VERSION ""

NS_ :

BS_:

BU_: ECM

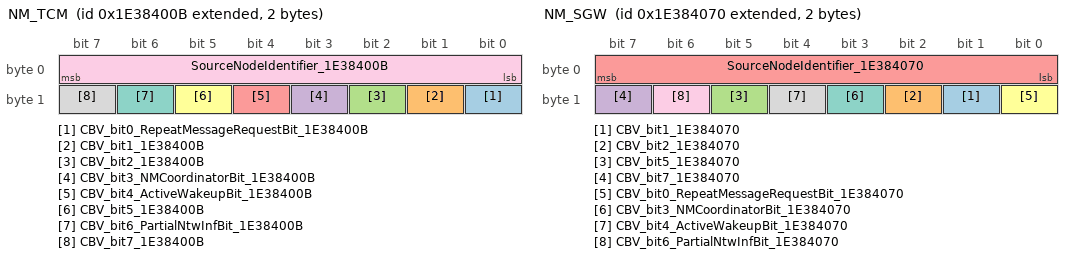
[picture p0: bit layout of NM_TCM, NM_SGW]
BO_ 2654486539 NM_TCM: 2 Vector__XXX
 SG_ CBV_bit0_RepeatMessageRequestBit_1E38400B : 8|1@0+ (1,0) [0|1] "" ECM
 SG_ CBV_bit1_1E38400B : 9|1@0+ (1,0) [0|1] "" ECM
 SG_ CBV_bit2_1E38400B : 10|1@0+ (1,0) [0|1] "" ECM
 SG_ CBV_bit3_NMCoordinatorBit_1E38400B : 11|1@0+ (1,0) [0|1] "" ECM
 SG_ CBV_bit4_ActiveWakeupBit_1E38400B : 12|1@0+ (1,0) [0|1] "" ECM
 SG_ CBV_bit5_1E38400B : 13|1@0+ (1,0) [0|1] "" ECM
 SG_ CBV_bit6_PartialNtwInfBit_1E38400B : 14|1@0+ (1,0) [0|1] "" ECM
 SG_ CBV_bit7_1E38400B : 15|1@0+ (1,0) [0|1] "" ECM
 SG_ SourceNodeIdentifier_1E38400B : 7|8@0+ (1,0) [0|255] "-"  ECM

BO_ 2654486640 NM_SGW: 2 Vector__XXX
 SG_ CBV_bit1_1E384070 : 9|1@0+ (1,0) [0|1] "" ECM
 SG_ CBV_bit2_1E384070 : 10|1@0+ (1,0) [0|1] "" ECM
 SG_ CBV_bit5_1E384070 : 13|1@0+ (1,0) [0|1] "" ECM
 SG_ CBV_bit7_1E384070 : 15|1@0+ (1,0) [0|1] "" ECM
 SG_ SourceNodeIdentifier_1E384070 : 7|8@0+ (1,0) [0|255] "-"  ECM
 SG_ CBV_bit0_RepeatMessageRequestBit_1E384070 : 8|1@0+ (1,0) [0|1] "" ECM
 SG_ CBV_bit3_NMCoordinatorBit_1E384070 : 11|1@0+ (1,0) [0|1] "" ECM
 SG_ CBV_bit4_ActiveWakeupBit_1E384070 : 12|1@0+ (1,0) [0|1] "" ECM
 SG_ CBV_bit6_PartialNtwInfBit_1E384070 : 14|1@0+ (1,0) [0|1] "" ECM

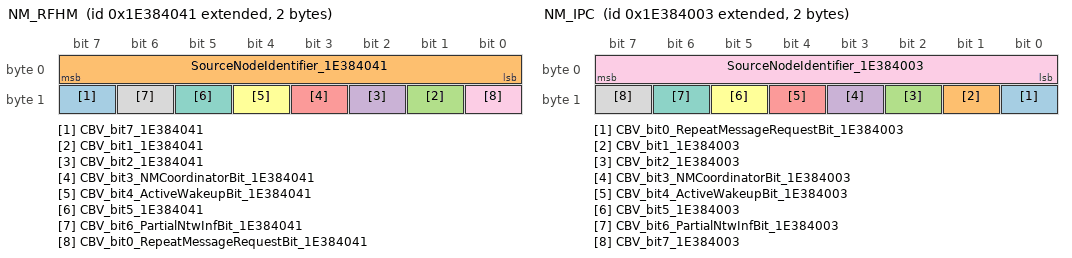
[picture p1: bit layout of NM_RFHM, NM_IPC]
BO_ 2654486593 NM_RFHM: 2 Vector__XXX
 SG_ CBV_bit7_1E384041 : 15|1@0+ (1,0) [0|1] "" ECM
 SG_ SourceNodeIdentifier_1E384041 : 7|8@0+ (1,0) [0|255] "-"  ECM
 SG_ CBV_bit1_1E384041 : 9|1@0+ (1,0) [0|1] "" ECM
 SG_ CBV_bit2_1E384041 : 10|1@0+ (1,0) [0|1] "" ECM
 SG_ CBV_bit3_NMCoordinatorBit_1E384041 : 11|1@0+ (1,0) [0|1] "" ECM
 SG_ CBV_bit4_ActiveWakeupBit_1E384041 : 12|1@0+ (1,0) [0|1] "" ECM
 SG_ CBV_bit5_1E384041 : 13|1@0+ (1,0) [0|1] "" ECM
 SG_ CBV_bit6_PartialNtwInfBit_1E384041 : 14|1@0+ (1,0) [0|1] "" ECM
 SG_ CBV_bit0_RepeatMessageRequestBit_1E384041 : 8|1@0+ (1,0) [0|1] "" ECM

BO_ 2654486531 NM_IPC: 2 Vector__XXX
 SG_ CBV_bit0_RepeatMessageRequestBit_1E384003 : 8|1@0+ (1,0) [0|1] "" ECM
 SG_ CBV_bit1_1E384003 : 9|1@0+ (1,0) [0|1] "" ECM
 SG_ CBV_bit2_1E384003 : 10|1@0+ (1,0) [0|1] "" ECM
 SG_ CBV_bit3_NMCoordinatorBit_1E384003 : 11|1@0+ (1,0) [0|1] "" ECM
 SG_ CBV_bit4_ActiveWakeupBit_1E384003 : 12|1@0+ (1,0) [0|1] "" ECM
 SG_ CBV_bit5_1E384003 : 13|1@0+ (1,0) [0|1] "" ECM
 SG_ CBV_bit6_PartialNtwInfBit_1E384003 : 14|1@0+ (1,0) [0|1] "" ECM
 SG_ CBV_bit7_1E384003 : 15|1@0+ (1,0) [0|1] "" ECM
 SG_ SourceNodeIdentifier_1E384003 : 7|8@0+ (1,0) [0|255] "-"  ECM

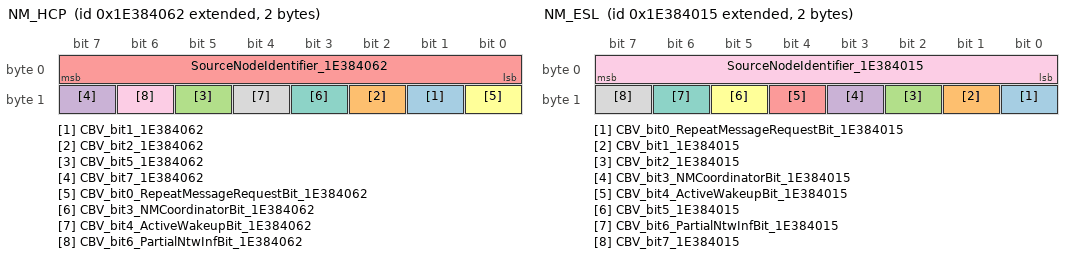
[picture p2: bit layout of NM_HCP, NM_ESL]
BO_ 2654486626 NM_HCP: 2 Vector__XXX
 SG_ CBV_bit1_1E384062 : 9|1@0+ (1,0) [0|1] "" ECM
 SG_ CBV_bit2_1E384062 : 10|1@0+ (1,0) [0|1] "" ECM
 SG_ CBV_bit5_1E384062 : 13|1@0+ (1,0) [0|1] "" ECM
 SG_ CBV_bit7_1E384062 : 15|1@0+ (1,0) [0|1] "" ECM
 SG_ SourceNodeIdentifier_1E384062 : 7|8@0+ (1,0) [0|255] "-"  ECM
 SG_ CBV_bit0_RepeatMessageRequestBit_1E384062 : 8|1@0+ (1,0) [0|1] "" ECM
 SG_ CBV_bit3_NMCoordinatorBit_1E384062 : 11|1@0+ (1,0) [0|1] "" ECM
 SG_ CBV_bit4_ActiveWakeupBit_1E384062 : 12|1@0+ (1,0) [0|1] "" ECM
 SG_ CBV_bit6_PartialNtwInfBit_1E384062 : 14|1@0+ (1,0) [0|1] "" ECM

BO_ 2654486549 NM_ESL: 2 Vector__XXX
 SG_ CBV_bit0_RepeatMessageRequestBit_1E384015 : 8|1@0+ (1,0) [0|1] "" ECM
 SG_ CBV_bit1_1E384015 : 9|1@0+ (1,0) [0|1] "" ECM
 SG_ CBV_bit2_1E384015 : 10|1@0+ (1,0) [0|1] "" ECM
 SG_ CBV_bit3_NMCoordinatorBit_1E384015 : 11|1@0+ (1,0) [0|1] "" ECM
 SG_ CBV_bit4_ActiveWakeupBit_1E384015 : 12|1@0+ (1,0) [0|1] "" ECM
 SG_ CBV_bit5_1E384015 : 13|1@0+ (1,0) [0|1] "" ECM
 SG_ CBV_bit6_PartialNtwInfBit_1E384015 : 14|1@0+ (1,0) [0|1] "" ECM
 SG_ CBV_bit7_1E384015 : 15|1@0+ (1,0) [0|1] "" ECM
 SG_ SourceNodeIdentifier_1E384015 : 7|8@0+ (1,0) [0|255] "-"  ECM

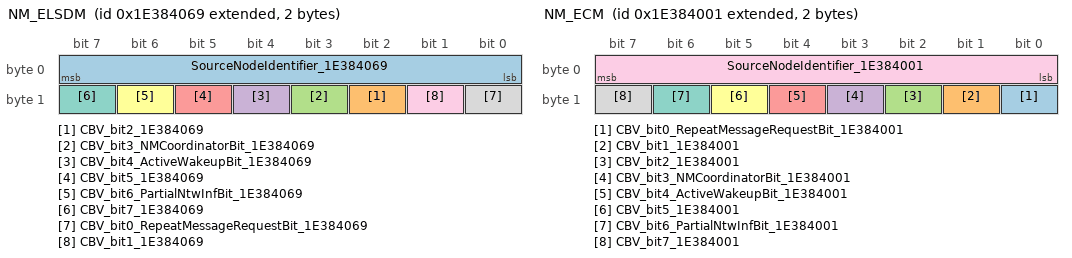
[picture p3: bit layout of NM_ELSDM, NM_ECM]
BO_ 2654486633 NM_ELSDM: 2 Vector__XXX
 SG_ SourceNodeIdentifier_1E384069 : 7|8@0+ (1,0) [0|255] "-"  ECM
 SG_ CBV_bit2_1E384069 : 10|1@0+ (1,0) [0|1] "" ECM
 SG_ CBV_bit3_NMCoordinatorBit_1E384069 : 11|1@0+ (1,0) [0|1] "" ECM
 SG_ CBV_bit4_ActiveWakeupBit_1E384069 : 12|1@0+ (1,0) [0|1] "" ECM
 SG_ CBV_bit5_1E384069 : 13|1@0+ (1,0) [0|1] "" ECM
 SG_ CBV_bit6_PartialNtwInfBit_1E384069 : 14|1@0+ (1,0) [0|1] "" ECM
 SG_ CBV_bit7_1E384069 : 15|1@0+ (1,0) [0|1] "" ECM
 SG_ CBV_bit0_RepeatMessageRequestBit_1E384069 : 8|1@0+ (1,0) [0|1] "" ECM
 SG_ CBV_bit1_1E384069 : 9|1@0+ (1,0) [0|1] "" ECM

BO_ 2654486529 NM_ECM: 2 ECM
 SG_ CBV_bit0_RepeatMessageRequestBit_1E384001 : 8|1@0+ (1,0) [0|1] "" Vector__XXX
 SG_ CBV_bit1_1E384001 : 9|1@0+ (1,0) [0|1] "" Vector__XXX
 SG_ CBV_bit2_1E384001 : 10|1@0+ (1,0) [0|1] "" Vector__XXX
 SG_ CBV_bit3_NMCoordinatorBit_1E384001 : 11|1@0+ (1,0) [0|1] "" Vector__XXX
 SG_ CBV_bit4_ActiveWakeupBit_1E384001 : 12|1@0+ (1,0) [0|1] "" Vector__XXX
 SG_ CBV_bit5_1E384001 : 13|1@0+ (1,0) [0|1] "" Vector__XXX
 SG_ CBV_bit6_PartialNtwInfBit_1E384001 : 14|1@0+ (1,0) [0|1] "" Vector__XXX
 SG_ CBV_bit7_1E384001 : 15|1@0+ (1,0) [0|1] "" Vector__XXX
 SG_ SourceNodeIdentifier_1E384001 : 7|8@0+ (1,0) [0|255] "-"  Vector__XXX

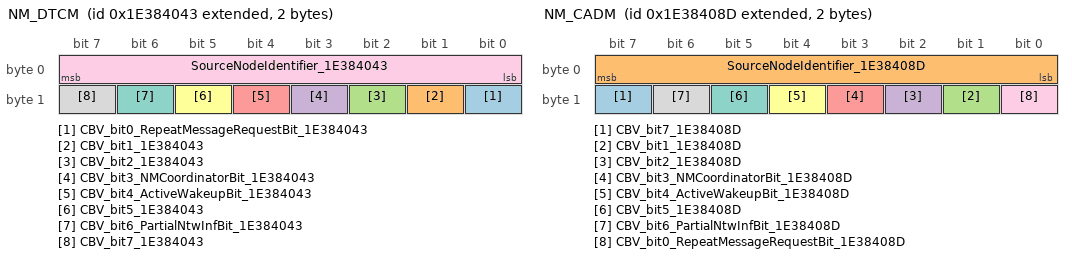
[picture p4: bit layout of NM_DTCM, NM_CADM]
BO_ 2654486595 NM_DTCM: 2 Vector__XXX
 SG_ CBV_bit0_RepeatMessageRequestBit_1E384043 : 8|1@0+ (1,0) [0|1] "" ECM
 SG_ CBV_bit1_1E384043 : 9|1@0+ (1,0) [0|1] "" ECM
 SG_ CBV_bit2_1E384043 : 10|1@0+ (1,0) [0|1] "" ECM
 SG_ CBV_bit3_NMCoordinatorBit_1E384043 : 11|1@0+ (1,0) [0|1] "" ECM
 SG_ CBV_bit4_ActiveWakeupBit_1E384043 : 12|1@0+ (1,0) [0|1] "" ECM
 SG_ CBV_bit5_1E384043 : 13|1@0+ (1,0) [0|1] "" ECM
 SG_ CBV_bit6_PartialNtwInfBit_1E384043 : 14|1@0+ (1,0) [0|1] "" ECM
 SG_ CBV_bit7_1E384043 : 15|1@0+ (1,0) [0|1] "" ECM
 SG_ SourceNodeIdentifier_1E384043 : 7|8@0+ (1,0) [0|255] "-"  ECM

BO_ 2654486669 NM_CADM: 2 Vector__XXX
 SG_ CBV_bit7_1E38408D : 15|1@0+ (1,0) [0|1] "" ECM
 SG_ SourceNodeIdentifier_1E38408D : 7|8@0+ (1,0) [0|255] "-"  ECM
 SG_ CBV_bit1_1E38408D : 9|1@0+ (1,0) [0|1] "" ECM
 SG_ CBV_bit2_1E38408D : 10|1@0+ (1,0) [0|1] "" ECM
 SG_ CBV_bit3_NMCoordinatorBit_1E38408D : 11|1@0+ (1,0) [0|1] "" ECM
 SG_ CBV_bit4_ActiveWakeupBit_1E38408D : 12|1@0+ (1,0) [0|1] "" ECM
 SG_ CBV_bit5_1E38408D : 13|1@0+ (1,0) [0|1] "" ECM
 SG_ CBV_bit6_PartialNtwInfBit_1E38408D : 14|1@0+ (1,0) [0|1] "" ECM
 SG_ CBV_bit0_RepeatMessageRequestBit_1E38408D : 8|1@0+ (1,0) [0|1] "" ECM

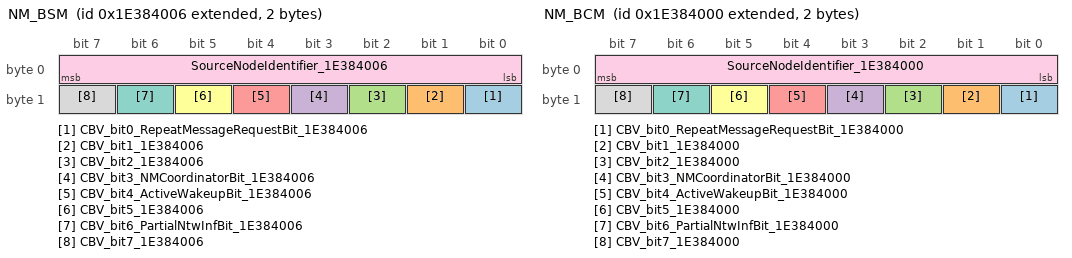
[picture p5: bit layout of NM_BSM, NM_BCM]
BO_ 2654486534 NM_BSM: 2 Vector__XXX
 SG_ CBV_bit0_RepeatMessageRequestBit_1E384006 : 8|1@0+ (1,0) [0|1] "" ECM
 SG_ CBV_bit1_1E384006 : 9|1@0+ (1,0) [0|1] "" ECM
 SG_ CBV_bit2_1E384006 : 10|1@0+ (1,0) [0|1] "" ECM
 SG_ CBV_bit3_NMCoordinatorBit_1E384006 : 11|1@0+ (1,0) [0|1] "" ECM
 SG_ CBV_bit4_ActiveWakeupBit_1E384006 : 12|1@0+ (1,0) [0|1] "" ECM
 SG_ CBV_bit5_1E384006 : 13|1@0+ (1,0) [0|1] "" ECM
 SG_ CBV_bit6_PartialNtwInfBit_1E384006 : 14|1@0+ (1,0) [0|1] "" ECM
 SG_ CBV_bit7_1E384006 : 15|1@0+ (1,0) [0|1] "" ECM
 SG_ SourceNodeIdentifier_1E384006 : 7|8@0+ (1,0) [0|255] "-"  ECM

BO_ 2654486528 NM_BCM: 2 Vector__XXX
 SG_ CBV_bit0_RepeatMessageRequestBit_1E384000 : 8|1@0+ (1,0) [0|1] "" ECM
 SG_ CBV_bit1_1E384000 : 9|1@0+ (1,0) [0|1] "" ECM
 SG_ CBV_bit2_1E384000 : 10|1@0+ (1,0) [0|1] "" ECM
 SG_ CBV_bit3_NMCoordinatorBit_1E384000 : 11|1@0+ (1,0) [0|1] "" ECM
 SG_ CBV_bit4_ActiveWakeupBit_1E384000 : 12|1@0+ (1,0) [0|1] "" ECM
 SG_ CBV_bit5_1E384000 : 13|1@0+ (1,0) [0|1] "" ECM
 SG_ CBV_bit6_PartialNtwInfBit_1E384000 : 14|1@0+ (1,0) [0|1] "" ECM
 SG_ CBV_bit7_1E384000 : 15|1@0+ (1,0) [0|1] "" ECM
 SG_ SourceNodeIdentifier_1E384000 : 7|8@0+ (1,0) [0|255] "-"  ECM

CM_ SG_ 2654486595 CBV_bit6_PartialNtwInfBit_1E384043 "Partial Network Information Bit (PNI)";
CM_ SG_ 2654486595 SourceNodeIdentifier_1E384043 "Source Node Identifier";
CM_ SG_ 2654486633 CBV_bit0_RepeatMessageRequestBit_1E384069 "Repeat Message Request Bit";
CM_ SG_ 2654486633 CBV_bit3_NMCoordinatorBit_1E384069 "NM Coordinator Sleep Bit";
CM_ SG_ 2654486633 CBV_bit4_ActiveWakeupBit_1E384069 "Active Wakeup Bit";
CM_ SG_ 2654486633 CBV_bit6_PartialNtwInfBit_1E384069 "Partial Network Information Bit (PNI)";
CM_ SG_ 2654486633 SourceNodeIdentifier_1E384069 "Source Node Identifier";
CM_ SG_ 2654486549 CBV_bit0_RepeatMessageRequestBit_1E384015 "Repeat Message Request Bit";
CM_ SG_ 2654486549 CBV_bit3_NMCoordinatorBit_1E384015 "NM Coordinator Sleep Bit";
CM_ SG_ 2654486549 CBV_bit4_ActiveWakeupBit_1E384015 "Active Wakeup Bit";
CM_ SG_ 2654486549 CBV_bit6_PartialNtwInfBit_1E384015 "Partial Network Information Bit (PNI)";
CM_ SG_ 2654486549 SourceNodeIdentifier_1E384015 "Source Node Identifier";
CM_ SG_ 2654486626 CBV_bit0_RepeatMessageRequestBit_1E384062 "Repeat Message Request Bit";
CM_ SG_ 2654486626 CBV_bit3_NMCoordinatorBit_1E384062 "NM Coordinator Sleep Bit";
CM_ SG_ 2654486626 CBV_bit4_ActiveWakeupBit_1E384062 "Active Wakeup Bit";
CM_ SG_ 2654486626 CBV_bit6_PartialNtwInfBit_1E384062 "Partial Network Information Bit (PNI)";
CM_ SG_ 2654486626 SourceNodeIdentifier_1E384062 "Source Node Identifier";
CM_ SG_ 2654486531 CBV_bit0_RepeatMessageRequestBit_1E384003 "Repeat Message Request Bit";
CM_ SG_ 2654486531 CBV_bit3_NMCoordinatorBit_1E384003 "NM Coordinator Sleep Bit";
CM_ SG_ 2654486531 CBV_bit4_ActiveWakeupBit_1E384003 "Active Wakeup Bit";
CM_ SG_ 2654486531 CBV_bit6_PartialNtwInfBit_1E384003 "Partial Network Information Bit (PNI)";
CM_ SG_ 2654486531 SourceNodeIdentifier_1E384003 "Source Node Identifier";
CM_ SG_ 2654486593 CBV_bit0_RepeatMessageRequestBit_1E384041 "Repeat Message Request Bit";
CM_ SG_ 2654486593 CBV_bit3_NMCoordinatorBit_1E384041 "NM Coordinator Sleep Bit";
CM_ SG_ 2654486593 CBV_bit4_ActiveWakeupBit_1E384041 "Active Wakeup Bit";
CM_ SG_ 2654486593 CBV_bit6_PartialNtwInfBit_1E384041 "Partial Network Information Bit (PNI)";
CM_ SG_ 2654486593 SourceNodeIdentifier_1E384041 "Source Node Identifier";
CM_ SG_ 2654486640 CBV_bit6_PartialNtwInfBit_1E384070 "Partial Network Information Bit (PNI)";
CM_ SG_ 2654486640 SourceNodeIdentifier_1E384070 "Source Node Identifier";
CM_ SG_ 2654486640 CBV_bit0_RepeatMessageRequestBit_1E384070 "Repeat Message Request Bit";
CM_ SG_ 2654486640 CBV_bit3_NMCoordinatorBit_1E384070 "NM Coordinator Sleep Bit";
CM_ SG_ 2654486640 CBV_bit4_ActiveWakeupBit_1E384070 "Active Wakeup Bit";
CM_ SG_ 2654486539 CBV_bit0_RepeatMessageRequestBit_1E38400B "Repeat Message Request Bit";
CM_ SG_ 2654486539 CBV_bit3_NMCoordinatorBit_1E38400B "NM Coordinator Sleep Bit";
CM_ SG_ 2654486539 CBV_bit4_ActiveWakeupBit_1E38400B "Active Wakeup Bit";
CM_ SG_ 2654486539 CBV_bit6_PartialNtwInfBit_1E38400B "Partial Network Information Bit (PNI)";
CM_ SG_ 2654486539 SourceNodeIdentifier_1E38400B "Source Node Identifier";
CM_ SG_ 2654486529 CBV_bit0_RepeatMessageRequestBit_1E384001 "Repeat Message Request Bit";
CM_ SG_ 2654486529 CBV_bit3_NMCoordinatorBit_1E384001 "NM Coordinator Sleep Bit";
CM_ SG_ 2654486529 CBV_bit4_ActiveWakeupBit_1E384001 "Active Wakeup Bit";
CM_ SG_ 2654486529 CBV_bit6_PartialNtwInfBit_1E384001 "Partial Network Information Bit (PNI)";
CM_ SG_ 2654486529 SourceNodeIdentifier_1E384001 "Source Node Identifier";
CM_ SG_ 2654486528 CBV_bit0_RepeatMessageRequestBit_1E384000 "Repeat Message Request Bit";
CM_ SG_ 2654486528 CBV_bit3_NMCoordinatorBit_1E384000 "NM Coordinator Sleep Bit";
CM_ SG_ 2654486528 CBV_bit4_ActiveWakeupBit_1E384000 "Active Wakeup Bit";
CM_ SG_ 2654486528 CBV_bit6_PartialNtwInfBit_1E384000 "Partial Network Information Bit (PNI)";
CM_ SG_ 2654486528 SourceNodeIdentifier_1E384000 "Source Node Identifier";
CM_ SG_ 2654486534 CBV_bit0_RepeatMessageRequestBit_1E384006 "Repeat Message Request Bit";
CM_ SG_ 2654486534 CBV_bit3_NMCoordinatorBit_1E384006 "NM Coordinator Sleep Bit";
CM_ SG_ 2654486534 CBV_bit4_ActiveWakeupBit_1E384006 "Active Wakeup Bit";
CM_ SG_ 2654486534 CBV_bit6_PartialNtwInfBit_1E384006 "Partial Network Information Bit (PNI)";
CM_ SG_ 2654486534 SourceNodeIdentifier_1E384006 "Source Node Identifier";
CM_ SG_ 2654486669 CBV_bit0_RepeatMessageRequestBit_1E38408D "Repeat Message Request Bit";
CM_ SG_ 2654486669 CBV_bit3_NMCoordinatorBit_1E38408D "NM Coordinator Sleep Bit";
CM_ SG_ 2654486669 CBV_bit4_ActiveWakeupBit_1E38408D "Active Wakeup Bit";
CM_ SG_ 2654486669 CBV_bit6_PartialNtwInfBit_1E38408D "Partial Network Information Bit (PNI)";
CM_ SG_ 2654486669 SourceNodeIdentifier_1E38408D "Source Node Identifier";
CM_ SG_ 2654486595 CBV_bit0_RepeatMessageRequestBit_1E384043 "Repeat Message Request Bit";
CM_ SG_ 2654486595 CBV_bit3_NMCoordinatorBit_1E384043 "NM Coordinator Sleep Bit";
CM_ SG_ 2654486595 CBV_bit4_ActiveWakeupBit_1E384043 "Active Wakeup Bit";
BA_DEF_ SG_ "GenSigTimeoutTime_ADCAM" INT 0 65535;
BA_DEF_ SG_ "GenSigTimeoutTime_EVCU2" INT 0 65535;
BA_DEF_ SG_ "GenSigTimeoutTime_VDCM" INT 0 65535;
BA_DEF_ SG_ "GenSigStartValue" INT 0 2147483647;
BA_DEF_ SG_ "GenSigInactiveValue" INT 0 2147483647;
BA_DEF_ SG_ "GenSigSendType" ENUM "NotUsed","OnWrite","OnWriteWithRepetition","OnChange","OnChangeWithRepetition","IfActive","IfActiveWithRepetition","NoSigSendType";
BA_DEF_ SG_ "SystemSignalLongSymbol" STRING ;
BA_DEF_ SG_ "GenSigTimeoutTime_AGSM" INT 0 65535;
BA_DEF_ SG_ "GenSigTimeoutTime_ASBS" INT 0 65535;
BA_DEF_ SG_ "GenSigTimeoutTime_BCM" INT 0 65535;
BA_DEF_ SG_ "GenSigTimeoutTime_BSM" INT 0 65535;
BA_DEF_ SG_ "GenSigTimeoutTime_CADM" INT 0 65535;
BA_DEF_ SG_ "GenSigTimeoutTime_DMSM" INT 0 65535;
BA_DEF_ SG_ "GenSigTimeoutTime_DTCM" INT 0 65535;
BA_DEF_ SG_ "GenSigTimeoutTime_ECM" INT 0 65535;
BA_DEF_ SG_ "GenSigTimeoutTime_ELSDM" INT 0 65535;
BA_DEF_ SG_ "GenSigTimeoutTime_ESL" INT 0 65535;
BA_DEF_ SG_ "GenSigTimeoutTime_GNMM" INT 0 65535;
BA_DEF_ SG_ "GenSigTimeoutTime_HCP" INT 0 65535;
BA_DEF_ SG_ "GenSigTimeoutTime_IPC" INT 0 65535;
BA_DEF_ SG_ "GenSigTimeoutTime_RFHM" INT 0 65535;
BA_DEF_ SG_ "GenSigTimeoutTime_SGW" INT 0 65535;
BA_DEF_ SG_ "GenSigTimeoutTime_TCM" INT 0 65535;
BA_DEF_ BO_ "DiagRequest" ENUM "No","Yes";
BA_DEF_ BO_ "Type" ENUM "P","C","PE","COC","PE_Cntrl","E","E_Cntrl","OC","S","BAF","DC","EM","MM","ISO-TP","-";
BA_DEF_ BO_ "DiagResponse" ENUM "No","Yes";
BA_DEF_ BO_ "NmMessage" ENUM "No","Yes";
BA_DEF_ BO_ "GenMsgSendType" ENUM "Cyclic","NotUsed","NotUsed","NotUsed","NotUsed","NotUsed","NotUsed","NotUsed","NoMsgSendType";
BA_DEF_ BO_ "GenMsgNrOfRepetition" INT 0 255;
BA_DEF_ BO_ "GenMsgILSupport" ENUM "No","Yes";
BA_DEF_ BO_ "GenMsgStartDelayTime" INT 0 65535;
BA_DEF_ BO_ "GenMsgCycleTimeFast" INT 0 65535;
BA_DEF_ BO_ "GenMsgCycleTime" INT 0 65535;
BA_DEF_ BO_ "GenMsgDelayTime" INT 0 65535;
BA_DEF_ BO_ "NmAsrMessage" ENUM "No","Yes";
BA_DEF_ BO_ "DiagState" ENUM "No","Yes";
BA_DEF_ BO_ "DiagConnection" HEX 0 65535;
BA_DEF_ BO_ "VFrameFormat" ENUM "StandardCAN","ExtendedCAN","reserved","reserved","reserved","reserved","reserved","reserved","reserved","reserved","reserved","reserved","reserved","reserved","StandardCAN_FD","ExtendedCAN_FD";
BA_DEF_ BO_ "CANFD_BRS" ENUM "0","1";
BA_DEF_DEF_ "GenSigTimeoutTime_ADCAM" 2500;
BA_DEF_DEF_ "GenSigTimeoutTime_EVCU2" 2500;
BA_DEF_DEF_ "GenSigTimeoutTime_VDCM" 2500;
BA_DEF_DEF_ "GenSigStartValue" 0;
BA_DEF_DEF_ "GenSigInactiveValue" 0;
BA_DEF_DEF_ "GenSigSendType" "NoSigSendType";
BA_DEF_DEF_ "SystemSignalLongSymbol" "";
BA_DEF_DEF_ "GenSigTimeoutTime_AGSM" 2500;
BA_DEF_DEF_ "GenSigTimeoutTime_ASBS" 2500;
BA_DEF_DEF_ "GenSigTimeoutTime_BCM" 2500;
BA_DEF_DEF_ "GenSigTimeoutTime_BSM" 2500;
BA_DEF_DEF_ "GenSigTimeoutTime_CADM" 2500;
BA_DEF_DEF_ "GenSigTimeoutTime_DMSM" 2500;
BA_DEF_DEF_ "GenSigTimeoutTime_DTCM" 2500;
BA_DEF_DEF_ "GenSigTimeoutTime_ECM" 2500;
BA_DEF_DEF_ "GenSigTimeoutTime_ELSDM" 2500;
BA_DEF_DEF_ "GenSigTimeoutTime_ESL" 2500;
BA_DEF_DEF_ "GenSigTimeoutTime_GNMM" 2500;
BA_DEF_DEF_ "GenSigTimeoutTime_HCP" 2500;
BA_DEF_DEF_ "GenSigTimeoutTime_IPC" 2500;
BA_DEF_DEF_ "GenSigTimeoutTime_RFHM" 2500;
BA_DEF_DEF_ "GenSigTimeoutTime_SGW" 2500;
BA_DEF_DEF_ "GenSigTimeoutTime_TCM" 2500;
BA_DEF_DEF_ "DiagRequest" "No";
BA_DEF_DEF_ "Type" "-";
BA_DEF_DEF_ "DiagResponse" "No";
BA_DEF_DEF_ "NmMessage" "No";
BA_DEF_DEF_ "GenMsgSendType" "NoMsgSendType";
BA_DEF_DEF_ "GenMsgNrOfRepetition" 0;
BA_DEF_DEF_ "GenMsgILSupport" "No";
BA_DEF_DEF_ "GenMsgStartDelayTime" 0;
BA_DEF_DEF_ "GenMsgCycleTimeFast" 0;
BA_DEF_DEF_ "GenMsgCycleTime" 0;
BA_DEF_DEF_ "GenMsgDelayTime" 0;
BA_DEF_DEF_ "NmAsrMessage" "No";
BA_DEF_DEF_ "DiagState" "No";
BA_DEF_DEF_ "DiagConnection" 0;
BA_DEF_DEF_ "VFrameFormat" "StandardCAN_FD";
BA_DEF_DEF_ "CANFD_BRS" "0";
BA_ "NmAsrMessage" BO_ 2654486669 1;
BA_ "Type" BO_ 2654486528 8;
BA_ "NmMessage" BO_ 2654486528 1;
BA_ "NmAsrMessage" BO_ 2654486528 1;
BA_ "VFrameFormat" BO_ 2654486528 15;
BA_ "CANFD_BRS" BO_ 2654486528 1;
BA_ "Type" BO_ 2654486534 8;
BA_ "NmMessage" BO_ 2654486534 1;
BA_ "NmAsrMessage" BO_ 2654486534 1;
BA_ "VFrameFormat" BO_ 2654486534 15;
BA_ "CANFD_BRS" BO_ 2654486534 1;
BA_ "Type" BO_ 2654486669 8;
BA_ "NmMessage" BO_ 2654486669 1;
BA_ "Type" BO_ 2654486529 8;
BA_ "NmMessage" BO_ 2654486529 1;
BA_ "NmAsrMessage" BO_ 2654486529 1;
BA_ "VFrameFormat" BO_ 2654486529 15;
BA_ "CANFD_BRS" BO_ 2654486529 1;
BA_ "VFrameFormat" BO_ 2654486669 15;
BA_ "CANFD_BRS" BO_ 2654486669 1;
BA_ "Type" BO_ 2654486595 8;
BA_ "NmMessage" BO_ 2654486595 1;
BA_ "NmAsrMessage" BO_ 2654486595 1;
BA_ "VFrameFormat" BO_ 2654486595 15;
BA_ "CANFD_BRS" BO_ 2654486595 1;
BA_ "Type" BO_ 2654486633 8;
BA_ "NmMessage" BO_ 2654486633 1;
BA_ "NmAsrMessage" BO_ 2654486633 1;
BA_ "VFrameFormat" BO_ 2654486633 15;
BA_ "CANFD_BRS" BO_ 2654486633 1;
BA_ "Type" BO_ 2654486549 8;
BA_ "NmMessage" BO_ 2654486549 1;
BA_ "NmAsrMessage" BO_ 2654486549 1;
BA_ "VFrameFormat" BO_ 2654486549 15;
BA_ "CANFD_BRS" BO_ 2654486549 1;
BA_ "Type" BO_ 2654486626 8;
BA_ "NmMessage" BO_ 2654486626 1;
BA_ "NmAsrMessage" BO_ 2654486626 1;
BA_ "VFrameFormat" BO_ 2654486626 15;
BA_ "CANFD_BRS" BO_ 2654486626 1;
BA_ "Type" BO_ 2654486531 8;
BA_ "NmMessage" BO_ 2654486531 1;
BA_ "NmAsrMessage" BO_ 2654486531 1;
BA_ "VFrameFormat" BO_ 2654486531 15;
BA_ "CANFD_BRS" BO_ 2654486531 1;
BA_ "Type" BO_ 2654486593 8;
BA_ "NmMessage" BO_ 2654486593 1;
BA_ "NmAsrMessage" BO_ 2654486593 1;
BA_ "VFrameFormat" BO_ 2654486593 15;
BA_ "CANFD_BRS" BO_ 2654486593 1;
BA_ "Type" BO_ 2654486640 8;
BA_ "NmMessage" BO_ 2654486640 1;
BA_ "NmAsrMessage" BO_ 2654486640 1;
BA_ "VFrameFormat" BO_ 2654486640 15;
BA_ "CANFD_BRS" BO_ 2654486640 1;
BA_ "Type" BO_ 2654486539 8;
BA_ "NmMessage" BO_ 2654486539 1;
BA_ "NmAsrMessage" BO_ 2654486539 1;
BA_ "VFrameFormat" BO_ 2654486539 15;
BA_ "CANFD_BRS" BO_ 2654486539 1;
BA_ "GenSigTimeoutTime_SGW" SG_ 2654486669 CBV_bit5_1E38408D 0;
BA_ "GenSigTimeoutTime_EVCU2" SG_ 2654486593 CBV_bit1_1E384041 0;
BA_ "GenSigTimeoutTime_VDCM" SG_ 2654486593 CBV_bit1_1E384041 0;
BA_ "GenSigTimeoutTime_ADCAM" SG_ 2654486593 CBV_bit2_1E384041 0;
BA_ "GenSigTimeoutTime_EVCU2" SG_ 2654486593 CBV_bit2_1E384041 0;
BA_ "GenSigTimeoutTime_VDCM" SG_ 2654486593 CBV_bit2_1E384041 0;
BA_ "GenSigTimeoutTime_ADCAM" SG_ 2654486593 CBV_bit3_NMCoordinatorBit_1E384041 0;
BA_ "GenSigTimeoutTime_EVCU2" SG_ 2654486593 CBV_bit3_NMCoordinatorBit_1E384041 0;
BA_ "GenSigTimeoutTime_VDCM" SG_ 2654486593 CBV_bit3_NMCoordinatorBit_1E384041 0;
BA_ "GenSigTimeoutTime_ADCAM" SG_ 2654486593 CBV_bit4_ActiveWakeupBit_1E384041 0;
BA_ "GenSigTimeoutTime_EVCU2" SG_ 2654486593 CBV_bit4_ActiveWakeupBit_1E384041 0;
BA_ "GenSigTimeoutTime_VDCM" SG_ 2654486593 CBV_bit4_ActiveWakeupBit_1E384041 0;
BA_ "GenSigTimeoutTime_ADCAM" SG_ 2654486593 CBV_bit5_1E384041 0;
BA_ "GenSigTimeoutTime_EVCU2" SG_ 2654486593 CBV_bit5_1E384041 0;
BA_ "GenSigTimeoutTime_VDCM" SG_ 2654486593 CBV_bit5_1E384041 0;
BA_ "GenSigTimeoutTime_ADCAM" SG_ 2654486593 CBV_bit6_PartialNtwInfBit_1E384041 0;
BA_ "GenSigTimeoutTime_EVCU2" SG_ 2654486593 CBV_bit6_PartialNtwInfBit_1E384041 0;
BA_ "GenSigTimeoutTime_VDCM" SG_ 2654486593 CBV_bit6_PartialNtwInfBit_1E384041 0;
BA_ "GenSigTimeoutTime_ADCAM" SG_ 2654486593 CBV_bit7_1E384041 0;
BA_ "GenSigTimeoutTime_EVCU2" SG_ 2654486593 CBV_bit7_1E384041 0;
BA_ "GenSigTimeoutTime_VDCM" SG_ 2654486593 CBV_bit7_1E384041 0;
BA_ "GenSigTimeoutTime_ADCAM" SG_ 2654486593 SourceNodeIdentifier_1E384041 0;
BA_ "GenSigTimeoutTime_EVCU2" SG_ 2654486593 SourceNodeIdentifier_1E384041 0;
BA_ "GenSigTimeoutTime_VDCM" SG_ 2654486593 SourceNodeIdentifier_1E384041 0;
BA_ "GenSigTimeoutTime_AGSM" SG_ 2654486593 CBV_bit0_RepeatMessageRequestBit_1E384041 0;
BA_ "GenSigTimeoutTime_ASBS" SG_ 2654486593 CBV_bit0_RepeatMessageRequestBit_1E384041 0;
BA_ "GenSigTimeoutTime_BCM" SG_ 2654486593 CBV_bit0_RepeatMessageRequestBit_1E384041 0;
BA_ "GenSigTimeoutTime_BSM" SG_ 2654486593 CBV_bit0_RepeatMessageRequestBit_1E384041 0;
BA_ "GenSigTimeoutTime_CADM" SG_ 2654486593 CBV_bit0_RepeatMessageRequestBit_1E384041 0;
BA_ "GenSigTimeoutTime_DMSM" SG_ 2654486593 CBV_bit0_RepeatMessageRequestBit_1E384041 0;
BA_ "GenSigTimeoutTime_DTCM" SG_ 2654486593 CBV_bit0_RepeatMessageRequestBit_1E384041 0;
BA_ "GenSigTimeoutTime_ECM" SG_ 2654486593 CBV_bit0_RepeatMessageRequestBit_1E384041 0;
BA_ "GenSigTimeoutTime_ELSDM" SG_ 2654486593 CBV_bit0_RepeatMessageRequestBit_1E384041 0;
BA_ "GenSigTimeoutTime_ESL" SG_ 2654486593 CBV_bit0_RepeatMessageRequestBit_1E384041 0;
BA_ "GenSigTimeoutTime_GNMM" SG_ 2654486593 CBV_bit0_RepeatMessageRequestBit_1E384041 0;
BA_ "GenSigTimeoutTime_HCP" SG_ 2654486593 CBV_bit0_RepeatMessageRequestBit_1E384041 0;
BA_ "GenSigTimeoutTime_IPC" SG_ 2654486593 CBV_bit0_RepeatMessageRequestBit_1E384041 0;
BA_ "GenSigTimeoutTime_RFHM" SG_ 2654486593 CBV_bit0_RepeatMessageRequestBit_1E384041 0;
BA_ "GenSigTimeoutTime_SGW" SG_ 2654486593 CBV_bit0_RepeatMessageRequestBit_1E384041 0;
BA_ "GenSigTimeoutTime_TCM" SG_ 2654486593 CBV_bit0_RepeatMessageRequestBit_1E384041 0;
BA_ "GenSigTimeoutTime_AGSM" SG_ 2654486593 CBV_bit1_1E384041 0;
BA_ "GenSigTimeoutTime_ASBS" SG_ 2654486593 CBV_bit1_1E384041 0;
BA_ "GenSigTimeoutTime_BCM" SG_ 2654486593 CBV_bit1_1E384041 0;
BA_ "GenSigTimeoutTime_BSM" SG_ 2654486593 CBV_bit1_1E384041 0;
BA_ "GenSigTimeoutTime_CADM" SG_ 2654486593 CBV_bit1_1E384041 0;
BA_ "GenSigTimeoutTime_DMSM" SG_ 2654486593 CBV_bit1_1E384041 0;
BA_ "GenSigTimeoutTime_DTCM" SG_ 2654486593 CBV_bit1_1E384041 0;
BA_ "GenSigTimeoutTime_ECM" SG_ 2654486593 CBV_bit1_1E384041 0;
BA_ "GenSigTimeoutTime_ELSDM" SG_ 2654486593 CBV_bit1_1E384041 0;
BA_ "GenSigTimeoutTime_ESL" SG_ 2654486593 CBV_bit1_1E384041 0;
BA_ "GenSigTimeoutTime_GNMM" SG_ 2654486593 CBV_bit1_1E384041 0;
BA_ "GenSigTimeoutTime_HCP" SG_ 2654486593 CBV_bit1_1E384041 0;
BA_ "GenSigTimeoutTime_IPC" SG_ 2654486593 CBV_bit1_1E384041 0;
BA_ "GenSigTimeoutTime_RFHM" SG_ 2654486593 CBV_bit1_1E384041 0;
BA_ "GenSigTimeoutTime_SGW" SG_ 2654486593 CBV_bit1_1E384041 0;
BA_ "GenSigTimeoutTime_TCM" SG_ 2654486593 CBV_bit1_1E384041 0;
BA_ "GenSigTimeoutTime_AGSM" SG_ 2654486593 CBV_bit2_1E384041 0;
BA_ "GenSigTimeoutTime_ASBS" SG_ 2654486593 CBV_bit2_1E384041 0;
BA_ "GenSigTimeoutTime_BCM" SG_ 2654486593 CBV_bit2_1E384041 0;
BA_ "GenSigTimeoutTime_BSM" SG_ 2654486593 CBV_bit2_1E384041 0;
BA_ "GenSigTimeoutTime_CADM" SG_ 2654486593 CBV_bit2_1E384041 0;
BA_ "GenSigTimeoutTime_DMSM" SG_ 2654486593 CBV_bit2_1E384041 0;
BA_ "GenSigTimeoutTime_DTCM" SG_ 2654486593 CBV_bit2_1E384041 0;
BA_ "GenSigTimeoutTime_ECM" SG_ 2654486593 CBV_bit2_1E384041 0;
BA_ "GenSigTimeoutTime_ELSDM" SG_ 2654486593 CBV_bit2_1E384041 0;
BA_ "GenSigTimeoutTime_ESL" SG_ 2654486593 CBV_bit2_1E384041 0;
BA_ "GenSigTimeoutTime_GNMM" SG_ 2654486593 CBV_bit2_1E384041 0;
BA_ "GenSigTimeoutTime_HCP" SG_ 2654486593 CBV_bit2_1E384041 0;
BA_ "GenSigTimeoutTime_IPC" SG_ 2654486593 CBV_bit2_1E384041 0;
BA_ "GenSigTimeoutTime_RFHM" SG_ 2654486593 CBV_bit2_1E384041 0;
BA_ "GenSigTimeoutTime_SGW" SG_ 2654486593 CBV_bit2_1E384041 0;
BA_ "GenSigTimeoutTime_TCM" SG_ 2654486593 CBV_bit2_1E384041 0;
BA_ "GenSigTimeoutTime_AGSM" SG_ 2654486593 CBV_bit3_NMCoordinatorBit_1E384041 0;
BA_ "GenSigTimeoutTime_ASBS" SG_ 2654486593 CBV_bit3_NMCoordinatorBit_1E384041 0;
BA_ "GenSigTimeoutTime_BCM" SG_ 2654486593 CBV_bit3_NMCoordinatorBit_1E384041 0;
BA_ "GenSigTimeoutTime_BSM" SG_ 2654486593 CBV_bit3_NMCoordinatorBit_1E384041 0;
BA_ "GenSigTimeoutTime_CADM" SG_ 2654486593 CBV_bit3_NMCoordinatorBit_1E384041 0;
BA_ "GenSigTimeoutTime_DMSM" SG_ 2654486593 CBV_bit3_NMCoordinatorBit_1E384041 0;
BA_ "GenSigTimeoutTime_DTCM" SG_ 2654486593 CBV_bit3_NMCoordinatorBit_1E384041 0;
BA_ "GenSigTimeoutTime_ECM" SG_ 2654486593 CBV_bit3_NMCoordinatorBit_1E384041 0;
BA_ "GenSigTimeoutTime_ELSDM" SG_ 2654486593 CBV_bit3_NMCoordinatorBit_1E384041 0;
BA_ "GenSigTimeoutTime_ESL" SG_ 2654486593 CBV_bit3_NMCoordinatorBit_1E384041 0;
BA_ "GenSigTimeoutTime_GNMM" SG_ 2654486593 CBV_bit3_NMCoordinatorBit_1E384041 0;
BA_ "GenSigTimeoutTime_HCP" SG_ 2654486593 CBV_bit3_NMCoordinatorBit_1E384041 0;
BA_ "GenSigTimeoutTime_IPC" SG_ 2654486593 CBV_bit3_NMCoordinatorBit_1E384041 0;
BA_ "GenSigTimeoutTime_RFHM" SG_ 2654486593 CBV_bit3_NMCoordinatorBit_1E384041 0;
BA_ "GenSigTimeoutTime_SGW" SG_ 2654486593 CBV_bit3_NMCoordinatorBit_1E384041 0;
BA_ "GenSigTimeoutTime_TCM" SG_ 2654486593 CBV_bit3_NMCoordinatorBit_1E384041 0;
BA_ "GenSigTimeoutTime_AGSM" SG_ 2654486593 CBV_bit4_ActiveWakeupBit_1E384041 0;
BA_ "GenSigTimeoutTime_ASBS" SG_ 2654486593 CBV_bit4_ActiveWakeupBit_1E384041 0;
BA_ "GenSigTimeoutTime_BCM" SG_ 2654486593 CBV_bit4_ActiveWakeupBit_1E384041 0;
BA_ "GenSigTimeoutTime_BSM" SG_ 2654486593 CBV_bit4_ActiveWakeupBit_1E384041 0;
BA_ "GenSigTimeoutTime_CADM" SG_ 2654486593 CBV_bit4_ActiveWakeupBit_1E384041 0;
BA_ "GenSigTimeoutTime_DMSM" SG_ 2654486593 CBV_bit4_ActiveWakeupBit_1E384041 0;
BA_ "GenSigTimeoutTime_DTCM" SG_ 2654486593 CBV_bit4_ActiveWakeupBit_1E384041 0;
BA_ "GenSigTimeoutTime_ECM" SG_ 2654486593 CBV_bit4_ActiveWakeupBit_1E384041 0;
BA_ "GenSigTimeoutTime_ELSDM" SG_ 2654486593 CBV_bit4_ActiveWakeupBit_1E384041 0;
BA_ "GenSigTimeoutTime_ESL" SG_ 2654486593 CBV_bit4_ActiveWakeupBit_1E384041 0;
BA_ "GenSigTimeoutTime_GNMM" SG_ 2654486593 CBV_bit4_ActiveWakeupBit_1E384041 0;
BA_ "GenSigTimeoutTime_HCP" SG_ 2654486593 CBV_bit4_ActiveWakeupBit_1E384041 0;
BA_ "GenSigTimeoutTime_IPC" SG_ 2654486593 CBV_bit4_ActiveWakeupBit_1E384041 0;
BA_ "GenSigTimeoutTime_RFHM" SG_ 2654486593 CBV_bit4_ActiveWakeupBit_1E384041 0;
BA_ "GenSigTimeoutTime_SGW" SG_ 2654486593 CBV_bit4_ActiveWakeupBit_1E384041 0;
BA_ "GenSigTimeoutTime_TCM" SG_ 2654486593 CBV_bit4_ActiveWakeupBit_1E384041 0;
BA_ "GenSigTimeoutTime_AGSM" SG_ 2654486593 CBV_bit5_1E384041 0;
BA_ "GenSigTimeoutTime_ASBS" SG_ 2654486593 CBV_bit5_1E384041 0;
BA_ "GenSigTimeoutTime_BCM" SG_ 2654486593 CBV_bit5_1E384041 0;
BA_ "GenSigTimeoutTime_BSM" SG_ 2654486593 CBV_bit5_1E384041 0;
BA_ "GenSigTimeoutTime_CADM" SG_ 2654486593 CBV_bit5_1E384041 0;
BA_ "GenSigTimeoutTime_DMSM" SG_ 2654486593 CBV_bit5_1E384041 0;
BA_ "GenSigTimeoutTime_DTCM" SG_ 2654486593 CBV_bit5_1E384041 0;
BA_ "GenSigTimeoutTime_ECM" SG_ 2654486593 CBV_bit5_1E384041 0;
BA_ "GenSigTimeoutTime_ELSDM" SG_ 2654486593 CBV_bit5_1E384041 0;
BA_ "GenSigTimeoutTime_ESL" SG_ 2654486593 CBV_bit5_1E384041 0;
BA_ "GenSigTimeoutTime_GNMM" SG_ 2654486593 CBV_bit5_1E384041 0;
BA_ "GenSigTimeoutTime_HCP" SG_ 2654486593 CBV_bit5_1E384041 0;
BA_ "GenSigTimeoutTime_IPC" SG_ 2654486593 CBV_bit5_1E384041 0;
BA_ "GenSigTimeoutTime_RFHM" SG_ 2654486593 CBV_bit5_1E384041 0;
BA_ "GenSigTimeoutTime_SGW" SG_ 2654486593 CBV_bit5_1E384041 0;
BA_ "GenSigTimeoutTime_TCM" SG_ 2654486593 CBV_bit5_1E384041 0;
BA_ "GenSigTimeoutTime_AGSM" SG_ 2654486593 CBV_bit6_PartialNtwInfBit_1E384041 0;
BA_ "GenSigTimeoutTime_ASBS" SG_ 2654486593 CBV_bit6_PartialNtwInfBit_1E384041 0;
BA_ "GenSigTimeoutTime_BCM" SG_ 2654486593 CBV_bit6_PartialNtwInfBit_1E384041 0;
BA_ "GenSigTimeoutTime_BSM" SG_ 2654486593 CBV_bit6_PartialNtwInfBit_1E384041 0;
BA_ "GenSigTimeoutTime_CADM" SG_ 2654486593 CBV_bit6_PartialNtwInfBit_1E384041 0;
BA_ "GenSigTimeoutTime_DMSM" SG_ 2654486593 CBV_bit6_PartialNtwInfBit_1E384041 0;
BA_ "GenSigTimeoutTime_DTCM" SG_ 2654486593 CBV_bit6_PartialNtwInfBit_1E384041 0;
BA_ "GenSigTimeoutTime_ECM" SG_ 2654486593 CBV_bit6_PartialNtwInfBit_1E384041 0;
BA_ "GenSigTimeoutTime_ELSDM" SG_ 2654486593 CBV_bit6_PartialNtwInfBit_1E384041 0;
BA_ "GenSigTimeoutTime_ESL" SG_ 2654486593 CBV_bit6_PartialNtwInfBit_1E384041 0;
BA_ "GenSigTimeoutTime_GNMM" SG_ 2654486593 CBV_bit6_PartialNtwInfBit_1E384041 0;
BA_ "GenSigTimeoutTime_HCP" SG_ 2654486593 CBV_bit6_PartialNtwInfBit_1E384041 0;
BA_ "GenSigTimeoutTime_IPC" SG_ 2654486593 CBV_bit6_PartialNtwInfBit_1E384041 0;
BA_ "GenSigTimeoutTime_RFHM" SG_ 2654486593 CBV_bit6_PartialNtwInfBit_1E384041 0;
BA_ "GenSigTimeoutTime_SGW" SG_ 2654486593 CBV_bit6_PartialNtwInfBit_1E384041 0;
BA_ "GenSigTimeoutTime_TCM" SG_ 2654486593 CBV_bit6_PartialNtwInfBit_1E384041 0;
BA_ "GenSigTimeoutTime_AGSM" SG_ 2654486593 CBV_bit7_1E384041 0;
BA_ "GenSigTimeoutTime_ASBS" SG_ 2654486593 CBV_bit7_1E384041 0;
BA_ "GenSigTimeoutTime_BCM" SG_ 2654486593 CBV_bit7_1E384041 0;
BA_ "GenSigTimeoutTime_BSM" SG_ 2654486593 CBV_bit7_1E384041 0;
BA_ "GenSigTimeoutTime_CADM" SG_ 2654486593 CBV_bit7_1E384041 0;
BA_ "GenSigTimeoutTime_DMSM" SG_ 2654486593 CBV_bit7_1E384041 0;
BA_ "GenSigTimeoutTime_DTCM" SG_ 2654486593 CBV_bit7_1E384041 0;
BA_ "GenSigTimeoutTime_ECM" SG_ 2654486593 CBV_bit7_1E384041 0;
BA_ "GenSigTimeoutTime_ELSDM" SG_ 2654486593 CBV_bit7_1E384041 0;
BA_ "GenSigTimeoutTime_ESL" SG_ 2654486593 CBV_bit7_1E384041 0;
BA_ "GenSigTimeoutTime_GNMM" SG_ 2654486593 CBV_bit7_1E384041 0;
BA_ "GenSigTimeoutTime_HCP" SG_ 2654486593 CBV_bit7_1E384041 0;
BA_ "GenSigTimeoutTime_IPC" SG_ 2654486593 CBV_bit7_1E384041 0;
BA_ "GenSigTimeoutTime_RFHM" SG_ 2654486593 CBV_bit7_1E384041 0;
BA_ "GenSigTimeoutTime_SGW" SG_ 2654486593 CBV_bit7_1E384041 0;
BA_ "GenSigTimeoutTime_TCM" SG_ 2654486593 CBV_bit7_1E384041 0;
BA_ "GenSigTimeoutTime_AGSM" SG_ 2654486593 SourceNodeIdentifier_1E384041 0;
BA_ "GenSigTimeoutTime_ASBS" SG_ 2654486593 SourceNodeIdentifier_1E384041 0;
BA_ "GenSigTimeoutTime_BCM" SG_ 2654486593 SourceNodeIdentifier_1E384041 0;
BA_ "GenSigTimeoutTime_BSM" SG_ 2654486593 SourceNodeIdentifier_1E384041 0;
BA_ "GenSigTimeoutTime_CADM" SG_ 2654486593 SourceNodeIdentifier_1E384041 0;
BA_ "GenSigTimeoutTime_DMSM" SG_ 2654486593 SourceNodeIdentifier_1E384041 0;
BA_ "GenSigTimeoutTime_DTCM" SG_ 2654486593 SourceNodeIdentifier_1E384041 0;
BA_ "GenSigTimeoutTime_ECM" SG_ 2654486593 SourceNodeIdentifier_1E384041 0;
BA_ "GenSigTimeoutTime_ELSDM" SG_ 2654486593 SourceNodeIdentifier_1E384041 0;
BA_ "GenSigTimeoutTime_ESL" SG_ 2654486593 SourceNodeIdentifier_1E384041 0;
BA_ "GenSigTimeoutTime_GNMM" SG_ 2654486593 SourceNodeIdentifier_1E384041 0;
BA_ "GenSigTimeoutTime_HCP" SG_ 2654486593 SourceNodeIdentifier_1E384041 0;
BA_ "GenSigTimeoutTime_IPC" SG_ 2654486593 SourceNodeIdentifier_1E384041 0;
BA_ "GenSigTimeoutTime_RFHM" SG_ 2654486593 SourceNodeIdentifier_1E384041 0;
BA_ "GenSigTimeoutTime_SGW" SG_ 2654486593 SourceNodeIdentifier_1E384041 0;
BA_ "GenSigTimeoutTime_TCM" SG_ 2654486593 SourceNodeIdentifier_1E384041 0;
BA_ "GenSigTimeoutTime_ADCAM" SG_ 2654486640 CBV_bit5_1E384070 0;
BA_ "GenSigTimeoutTime_EVCU2" SG_ 2654486640 CBV_bit5_1E384070 0;
BA_ "GenSigTimeoutTime_VDCM" SG_ 2654486640 CBV_bit5_1E384070 0;
BA_ "GenSigTimeoutTime_ADCAM" SG_ 2654486640 CBV_bit6_PartialNtwInfBit_1E384070 0;
BA_ "GenSigTimeoutTime_EVCU2" SG_ 2654486640 CBV_bit6_PartialNtwInfBit_1E384070 0;
BA_ "GenSigTimeoutTime_VDCM" SG_ 2654486640 CBV_bit6_PartialNtwInfBit_1E384070 0;
BA_ "GenSigTimeoutTime_ADCAM" SG_ 2654486640 CBV_bit7_1E384070 0;
BA_ "GenSigTimeoutTime_EVCU2" SG_ 2654486640 CBV_bit7_1E384070 0;
BA_ "GenSigTimeoutTime_VDCM" SG_ 2654486640 CBV_bit7_1E384070 0;
BA_ "GenSigTimeoutTime_ADCAM" SG_ 2654486640 SourceNodeIdentifier_1E384070 0;
BA_ "GenSigTimeoutTime_EVCU2" SG_ 2654486640 SourceNodeIdentifier_1E384070 0;
BA_ "GenSigTimeoutTime_VDCM" SG_ 2654486640 SourceNodeIdentifier_1E384070 0;
BA_ "GenSigTimeoutTime_ADCAM" SG_ 2654486640 CBV_bit0_RepeatMessageRequestBit_1E384070 0;
BA_ "GenSigTimeoutTime_EVCU2" SG_ 2654486640 CBV_bit0_RepeatMessageRequestBit_1E384070 0;
BA_ "GenSigTimeoutTime_VDCM" SG_ 2654486640 CBV_bit0_RepeatMessageRequestBit_1E384070 0;
BA_ "GenSigTimeoutTime_ADCAM" SG_ 2654486640 CBV_bit1_1E384070 0;
BA_ "GenSigTimeoutTime_EVCU2" SG_ 2654486640 CBV_bit1_1E384070 0;
BA_ "GenSigTimeoutTime_VDCM" SG_ 2654486640 CBV_bit1_1E384070 0;
BA_ "GenSigTimeoutTime_ADCAM" SG_ 2654486640 CBV_bit2_1E384070 0;
BA_ "GenSigTimeoutTime_EVCU2" SG_ 2654486640 CBV_bit2_1E384070 0;
BA_ "GenSigTimeoutTime_VDCM" SG_ 2654486640 CBV_bit2_1E384070 0;
BA_ "GenSigTimeoutTime_ADCAM" SG_ 2654486640 CBV_bit3_NMCoordinatorBit_1E384070 0;
BA_ "GenSigTimeoutTime_EVCU2" SG_ 2654486640 CBV_bit3_NMCoordinatorBit_1E384070 0;
BA_ "GenSigTimeoutTime_VDCM" SG_ 2654486640 CBV_bit3_NMCoordinatorBit_1E384070 0;
BA_ "GenSigTimeoutTime_ADCAM" SG_ 2654486640 CBV_bit4_ActiveWakeupBit_1E384070 0;
BA_ "GenSigTimeoutTime_EVCU2" SG_ 2654486640 CBV_bit4_ActiveWakeupBit_1E384070 0;
BA_ "GenSigTimeoutTime_VDCM" SG_ 2654486640 CBV_bit4_ActiveWakeupBit_1E384070 0;
BA_ "GenSigTimeoutTime_AGSM" SG_ 2654486640 CBV_bit5_1E384070 0;
BA_ "GenSigTimeoutTime_ASBS" SG_ 2654486640 CBV_bit5_1E384070 0;
BA_ "GenSigTimeoutTime_BCM" SG_ 2654486640 CBV_bit5_1E384070 0;
BA_ "GenSigTimeoutTime_BSM" SG_ 2654486640 CBV_bit5_1E384070 0;
BA_ "GenSigTimeoutTime_CADM" SG_ 2654486640 CBV_bit5_1E384070 0;
BA_ "GenSigTimeoutTime_DMSM" SG_ 2654486640 CBV_bit5_1E384070 0;
BA_ "GenSigTimeoutTime_DTCM" SG_ 2654486640 CBV_bit5_1E384070 0;
BA_ "GenSigTimeoutTime_ECM" SG_ 2654486640 CBV_bit5_1E384070 0;
BA_ "GenSigTimeoutTime_ELSDM" SG_ 2654486640 CBV_bit5_1E384070 0;
BA_ "GenSigTimeoutTime_ESL" SG_ 2654486640 CBV_bit5_1E384070 0;
BA_ "GenSigTimeoutTime_GNMM" SG_ 2654486640 CBV_bit5_1E384070 0;
BA_ "GenSigTimeoutTime_HCP" SG_ 2654486640 CBV_bit5_1E384070 0;
BA_ "GenSigTimeoutTime_IPC" SG_ 2654486640 CBV_bit5_1E384070 0;
BA_ "GenSigTimeoutTime_RFHM" SG_ 2654486640 CBV_bit5_1E384070 0;
BA_ "GenSigTimeoutTime_SGW" SG_ 2654486640 CBV_bit5_1E384070 0;
BA_ "GenSigTimeoutTime_TCM" SG_ 2654486640 CBV_bit5_1E384070 0;
BA_ "GenSigTimeoutTime_AGSM" SG_ 2654486640 CBV_bit6_PartialNtwInfBit_1E384070 0;
BA_ "GenSigTimeoutTime_ASBS" SG_ 2654486640 CBV_bit6_PartialNtwInfBit_1E384070 0;
BA_ "GenSigTimeoutTime_BCM" SG_ 2654486640 CBV_bit6_PartialNtwInfBit_1E384070 0;
BA_ "GenSigTimeoutTime_BSM" SG_ 2654486640 CBV_bit6_PartialNtwInfBit_1E384070 0;
BA_ "GenSigTimeoutTime_CADM" SG_ 2654486640 CBV_bit6_PartialNtwInfBit_1E384070 0;
BA_ "GenSigTimeoutTime_DMSM" SG_ 2654486640 CBV_bit6_PartialNtwInfBit_1E384070 0;
BA_ "GenSigTimeoutTime_DTCM" SG_ 2654486640 CBV_bit6_PartialNtwInfBit_1E384070 0;
BA_ "GenSigTimeoutTime_ECM" SG_ 2654486640 CBV_bit6_PartialNtwInfBit_1E384070 0;
BA_ "GenSigTimeoutTime_ELSDM" SG_ 2654486640 CBV_bit6_PartialNtwInfBit_1E384070 0;
BA_ "GenSigTimeoutTime_ESL" SG_ 2654486640 CBV_bit6_PartialNtwInfBit_1E384070 0;
BA_ "GenSigTimeoutTime_GNMM" SG_ 2654486640 CBV_bit6_PartialNtwInfBit_1E384070 0;
BA_ "GenSigTimeoutTime_HCP" SG_ 2654486640 CBV_bit6_PartialNtwInfBit_1E384070 0;
BA_ "GenSigTimeoutTime_IPC" SG_ 2654486640 CBV_bit6_PartialNtwInfBit_1E384070 0;
BA_ "GenSigTimeoutTime_RFHM" SG_ 2654486640 CBV_bit6_PartialNtwInfBit_1E384070 0;
BA_ "GenSigTimeoutTime_SGW" SG_ 2654486640 CBV_bit6_PartialNtwInfBit_1E384070 0;
BA_ "GenSigTimeoutTime_TCM" SG_ 2654486640 CBV_bit6_PartialNtwInfBit_1E384070 0;
BA_ "GenSigTimeoutTime_AGSM" SG_ 2654486640 CBV_bit7_1E384070 0;
BA_ "GenSigTimeoutTime_ASBS" SG_ 2654486640 CBV_bit7_1E384070 0;
BA_ "GenSigTimeoutTime_BCM" SG_ 2654486640 CBV_bit7_1E384070 0;
BA_ "GenSigTimeoutTime_BSM" SG_ 2654486640 CBV_bit7_1E384070 0;
BA_ "GenSigTimeoutTime_TCM" SG_ 2654486669 CBV_bit5_1E38408D 0;
BA_ "GenSigTimeoutTime_AGSM" SG_ 2654486669 CBV_bit6_PartialNtwInfBit_1E38408D 0;
BA_ "GenSigTimeoutTime_ASBS" SG_ 2654486669 CBV_bit6_PartialNtwInfBit_1E38408D 0;
BA_ "GenSigTimeoutTime_BCM" SG_ 2654486669 CBV_bit6_PartialNtwInfBit_1E38408D 0;
BA_ "GenSigTimeoutTime_BSM" SG_ 2654486669 CBV_bit6_PartialNtwInfBit_1E38408D 0;
BA_ "GenSigTimeoutTime_CADM" SG_ 2654486669 CBV_bit6_PartialNtwInfBit_1E38408D 0;
BA_ "GenSigTimeoutTime_DMSM" SG_ 2654486669 CBV_bit6_PartialNtwInfBit_1E38408D 0;
BA_ "GenSigTimeoutTime_DTCM" SG_ 2654486669 CBV_bit6_PartialNtwInfBit_1E38408D 0;
BA_ "GenSigTimeoutTime_ECM" SG_ 2654486669 CBV_bit6_PartialNtwInfBit_1E38408D 0;
BA_ "GenSigTimeoutTime_ELSDM" SG_ 2654486669 CBV_bit6_PartialNtwInfBit_1E38408D 0;
BA_ "GenSigTimeoutTime_ESL" SG_ 2654486669 CBV_bit6_PartialNtwInfBit_1E38408D 0;
BA_ "GenSigTimeoutTime_GNMM" SG_ 2654486669 CBV_bit6_PartialNtwInfBit_1E38408D 0;
BA_ "GenSigTimeoutTime_HCP" SG_ 2654486669 CBV_bit6_PartialNtwInfBit_1E38408D 0;
BA_ "GenSigTimeoutTime_IPC" SG_ 2654486669 CBV_bit6_PartialNtwInfBit_1E38408D 0;
BA_ "GenSigTimeoutTime_RFHM" SG_ 2654486669 CBV_bit6_PartialNtwInfBit_1E38408D 0;
BA_ "GenSigTimeoutTime_SGW" SG_ 2654486669 CBV_bit6_PartialNtwInfBit_1E38408D 0;
BA_ "GenSigTimeoutTime_TCM" SG_ 2654486669 CBV_bit6_PartialNtwInfBit_1E38408D 0;
BA_ "GenSigTimeoutTime_AGSM" SG_ 2654486669 CBV_bit7_1E38408D 0;
BA_ "GenSigTimeoutTime_ASBS" SG_ 2654486669 CBV_bit7_1E38408D 0;
BA_ "GenSigTimeoutTime_BCM" SG_ 2654486669 CBV_bit7_1E38408D 0;
BA_ "GenSigTimeoutTime_BSM" SG_ 2654486669 CBV_bit7_1E38408D 0;
BA_ "GenSigTimeoutTime_CADM" SG_ 2654486669 CBV_bit7_1E38408D 0;
BA_ "GenSigTimeoutTime_DMSM" SG_ 2654486669 CBV_bit7_1E38408D 0;
BA_ "GenSigTimeoutTime_DTCM" SG_ 2654486669 CBV_bit7_1E38408D 0;
BA_ "GenSigTimeoutTime_ECM" SG_ 2654486669 CBV_bit7_1E38408D 0;
BA_ "GenSigTimeoutTime_ELSDM" SG_ 2654486669 CBV_bit7_1E38408D 0;
BA_ "GenSigTimeoutTime_ESL" SG_ 2654486669 CBV_bit7_1E38408D 0;
BA_ "GenSigTimeoutTime_GNMM" SG_ 2654486669 CBV_bit7_1E38408D 0;
BA_ "GenSigTimeoutTime_HCP" SG_ 2654486669 CBV_bit7_1E38408D 0;
BA_ "GenSigTimeoutTime_IPC" SG_ 2654486669 CBV_bit7_1E38408D 0;
BA_ "GenSigTimeoutTime_RFHM" SG_ 2654486669 CBV_bit7_1E38408D 0;
BA_ "GenSigTimeoutTime_SGW" SG_ 2654486669 CBV_bit7_1E38408D 0;
BA_ "GenSigTimeoutTime_TCM" SG_ 2654486669 CBV_bit7_1E38408D 0;
BA_ "GenSigTimeoutTime_AGSM" SG_ 2654486669 SourceNodeIdentifier_1E38408D 0;
BA_ "GenSigTimeoutTime_ASBS" SG_ 2654486669 SourceNodeIdentifier_1E38408D 0;
BA_ "GenSigTimeoutTime_BCM" SG_ 2654486669 SourceNodeIdentifier_1E38408D 0;
BA_ "GenSigTimeoutTime_BSM" SG_ 2654486669 SourceNodeIdentifier_1E38408D 0;
BA_ "GenSigTimeoutTime_CADM" SG_ 2654486669 SourceNodeIdentifier_1E38408D 0;
BA_ "GenSigTimeoutTime_DMSM" SG_ 2654486669 SourceNodeIdentifier_1E38408D 0;
BA_ "GenSigTimeoutTime_DTCM" SG_ 2654486669 SourceNodeIdentifier_1E38408D 0;
BA_ "GenSigTimeoutTime_ECM" SG_ 2654486669 SourceNodeIdentifier_1E38408D 0;
BA_ "GenSigTimeoutTime_ELSDM" SG_ 2654486669 SourceNodeIdentifier_1E38408D 0;
BA_ "GenSigTimeoutTime_ESL" SG_ 2654486669 SourceNodeIdentifier_1E38408D 0;
BA_ "GenSigTimeoutTime_GNMM" SG_ 2654486669 SourceNodeIdentifier_1E38408D 0;
BA_ "GenSigTimeoutTime_HCP" SG_ 2654486669 SourceNodeIdentifier_1E38408D 0;
BA_ "GenSigTimeoutTime_IPC" SG_ 2654486669 SourceNodeIdentifier_1E38408D 0;
BA_ "GenSigTimeoutTime_RFHM" SG_ 2654486669 SourceNodeIdentifier_1E38408D 0;
BA_ "GenSigTimeoutTime_SGW" SG_ 2654486669 SourceNodeIdentifier_1E38408D 0;
BA_ "GenSigTimeoutTime_TCM" SG_ 2654486669 SourceNodeIdentifier_1E38408D 0;
BA_ "GenSigTimeoutTime_ADCAM" SG_ 2654486595 CBV_bit0_RepeatMessageRequestBit_1E384043 0;
BA_ "GenSigTimeoutTime_EVCU2" SG_ 2654486595 CBV_bit0_RepeatMessageRequestBit_1E384043 0;
BA_ "GenSigTimeoutTime_VDCM" SG_ 2654486595 CBV_bit0_RepeatMessageRequestBit_1E384043 0;
BA_ "GenSigTimeoutTime_ADCAM" SG_ 2654486595 CBV_bit1_1E384043 0;
BA_ "GenSigTimeoutTime_EVCU2" SG_ 2654486595 CBV_bit1_1E384043 0;
BA_ "GenSigTimeoutTime_VDCM" SG_ 2654486595 CBV_bit1_1E384043 0;
BA_ "GenSigTimeoutTime_ADCAM" SG_ 2654486595 CBV_bit2_1E384043 0;
BA_ "GenSigTimeoutTime_EVCU2" SG_ 2654486595 CBV_bit2_1E384043 0;
BA_ "GenSigTimeoutTime_VDCM" SG_ 2654486595 CBV_bit2_1E384043 0;
BA_ "GenSigTimeoutTime_ADCAM" SG_ 2654486595 CBV_bit3_NMCoordinatorBit_1E384043 0;
BA_ "GenSigTimeoutTime_EVCU2" SG_ 2654486595 CBV_bit3_NMCoordinatorBit_1E384043 0;
BA_ "GenSigTimeoutTime_VDCM" SG_ 2654486595 CBV_bit3_NMCoordinatorBit_1E384043 0;
BA_ "GenSigTimeoutTime_ADCAM" SG_ 2654486595 CBV_bit4_ActiveWakeupBit_1E384043 0;
BA_ "GenSigTimeoutTime_EVCU2" SG_ 2654486595 CBV_bit4_ActiveWakeupBit_1E384043 0;
BA_ "GenSigTimeoutTime_VDCM" SG_ 2654486595 CBV_bit4_ActiveWakeupBit_1E384043 0;
BA_ "GenSigTimeoutTime_ADCAM" SG_ 2654486595 CBV_bit5_1E384043 0;
BA_ "GenSigTimeoutTime_EVCU2" SG_ 2654486595 CBV_bit5_1E384043 0;
BA_ "GenSigTimeoutTime_VDCM" SG_ 2654486595 CBV_bit5_1E384043 0;
BA_ "GenSigTimeoutTime_ADCAM" SG_ 2654486595 CBV_bit6_PartialNtwInfBit_1E384043 0;
BA_ "GenSigTimeoutTime_EVCU2" SG_ 2654486595 CBV_bit6_PartialNtwInfBit_1E384043 0;
BA_ "GenSigTimeoutTime_VDCM" SG_ 2654486595 CBV_bit6_PartialNtwInfBit_1E384043 0;
BA_ "GenSigTimeoutTime_ADCAM" SG_ 2654486595 CBV_bit7_1E384043 0;
BA_ "GenSigTimeoutTime_EVCU2" SG_ 2654486595 CBV_bit7_1E384043 0;
BA_ "GenSigTimeoutTime_VDCM" SG_ 2654486595 CBV_bit7_1E384043 0;
BA_ "GenSigTimeoutTime_ADCAM" SG_ 2654486595 SourceNodeIdentifier_1E384043 0;
BA_ "GenSigTimeoutTime_EVCU2" SG_ 2654486595 SourceNodeIdentifier_1E384043 0;
BA_ "GenSigTimeoutTime_VDCM" SG_ 2654486595 SourceNodeIdentifier_1E384043 0;
BA_ "GenSigTimeoutTime_AGSM" SG_ 2654486595 CBV_bit0_RepeatMessageRequestBit_1E384043 0;
BA_ "GenSigTimeoutTime_ASBS" SG_ 2654486595 CBV_bit0_RepeatMessageRequestBit_1E384043 0;
BA_ "GenSigTimeoutTime_BCM" SG_ 2654486595 CBV_bit0_RepeatMessageRequestBit_1E384043 0;
BA_ "GenSigTimeoutTime_BSM" SG_ 2654486595 CBV_bit0_RepeatMessageRequestBit_1E384043 0;
BA_ "GenSigTimeoutTime_CADM" SG_ 2654486595 CBV_bit0_RepeatMessageRequestBit_1E384043 0;
BA_ "GenSigTimeoutTime_DMSM" SG_ 2654486595 CBV_bit0_RepeatMessageRequestBit_1E384043 0;
BA_ "GenSigTimeoutTime_DTCM" SG_ 2654486595 CBV_bit0_RepeatMessageRequestBit_1E384043 0;
BA_ "GenSigTimeoutTime_ECM" SG_ 2654486595 CBV_bit0_RepeatMessageRequestBit_1E384043 0;
BA_ "GenSigTimeoutTime_ELSDM" SG_ 2654486595 CBV_bit0_RepeatMessageRequestBit_1E384043 0;
BA_ "GenSigTimeoutTime_ESL" SG_ 2654486595 CBV_bit0_RepeatMessageRequestBit_1E384043 0;
BA_ "GenSigTimeoutTime_GNMM" SG_ 2654486595 CBV_bit0_RepeatMessageRequestBit_1E384043 0;
BA_ "GenSigTimeoutTime_HCP" SG_ 2654486595 CBV_bit0_RepeatMessageRequestBit_1E384043 0;
BA_ "GenSigTimeoutTime_IPC" SG_ 2654486595 CBV_bit0_RepeatMessageRequestBit_1E384043 0;
BA_ "GenSigTimeoutTime_RFHM" SG_ 2654486595 CBV_bit0_RepeatMessageRequestBit_1E384043 0;
BA_ "GenSigTimeoutTime_SGW" SG_ 2654486595 CBV_bit0_RepeatMessageRequestBit_1E384043 0;
BA_ "GenSigTimeoutTime_TCM" SG_ 2654486595 CBV_bit0_RepeatMessageRequestBit_1E384043 0;
BA_ "GenSigTimeoutTime_AGSM" SG_ 2654486595 CBV_bit1_1E384043 0;
BA_ "GenSigTimeoutTime_ASBS" SG_ 2654486595 CBV_bit1_1E384043 0;
BA_ "GenSigTimeoutTime_BCM" SG_ 2654486595 CBV_bit1_1E384043 0;
BA_ "GenSigTimeoutTime_BSM" SG_ 2654486595 CBV_bit1_1E384043 0;
BA_ "GenSigTimeoutTime_CADM" SG_ 2654486595 CBV_bit1_1E384043 0;
BA_ "GenSigTimeoutTime_DMSM" SG_ 2654486595 CBV_bit1_1E384043 0;
BA_ "GenSigTimeoutTime_DTCM" SG_ 2654486595 CBV_bit1_1E384043 0;
BA_ "GenSigTimeoutTime_ECM" SG_ 2654486595 CBV_bit1_1E384043 0;
BA_ "GenSigTimeoutTime_ELSDM" SG_ 2654486595 CBV_bit1_1E384043 0;
BA_ "GenSigTimeoutTime_ESL" SG_ 2654486595 CBV_bit1_1E384043 0;
BA_ "GenSigTimeoutTime_GNMM" SG_ 2654486595 CBV_bit1_1E384043 0;
BA_ "GenSigTimeoutTime_HCP" SG_ 2654486595 CBV_bit1_1E384043 0;
BA_ "GenSigTimeoutTime_IPC" SG_ 2654486595 CBV_bit1_1E384043 0;
BA_ "GenSigTimeoutTime_RFHM" SG_ 2654486595 CBV_bit1_1E384043 0;
BA_ "GenSigTimeoutTime_SGW" SG_ 2654486595 CBV_bit1_1E384043 0;
BA_ "GenSigTimeoutTime_TCM" SG_ 2654486595 CBV_bit1_1E384043 0;
BA_ "GenSigTimeoutTime_AGSM" SG_ 2654486595 CBV_bit2_1E384043 0;
BA_ "GenSigTimeoutTime_ASBS" SG_ 2654486595 CBV_bit2_1E384043 0;
BA_ "GenSigTimeoutTime_BCM" SG_ 2654486595 CBV_bit2_1E384043 0;
BA_ "GenSigTimeoutTime_BSM" SG_ 2654486595 CBV_bit2_1E384043 0;
BA_ "GenSigTimeoutTime_CADM" SG_ 2654486595 CBV_bit2_1E384043 0;
BA_ "GenSigTimeoutTime_DMSM" SG_ 2654486595 CBV_bit2_1E384043 0;
BA_ "GenSigTimeoutTime_DTCM" SG_ 2654486595 CBV_bit2_1E384043 0;
BA_ "GenSigTimeoutTime_ECM" SG_ 2654486595 CBV_bit2_1E384043 0;
BA_ "GenSigTimeoutTime_ELSDM" SG_ 2654486595 CBV_bit2_1E384043 0;
BA_ "GenSigTimeoutTime_ESL" SG_ 2654486595 CBV_bit2_1E384043 0;
BA_ "GenSigTimeoutTime_GNMM" SG_ 2654486595 CBV_bit2_1E384043 0;
BA_ "GenSigTimeoutTime_HCP" SG_ 2654486595 CBV_bit2_1E384043 0;
BA_ "GenSigTimeoutTime_IPC" SG_ 2654486595 CBV_bit2_1E384043 0;
BA_ "GenSigTimeoutTime_RFHM" SG_ 2654486595 CBV_bit2_1E384043 0;
BA_ "GenSigTimeoutTime_SGW" SG_ 2654486595 CBV_bit2_1E384043 0;
BA_ "GenSigTimeoutTime_TCM" SG_ 2654486595 CBV_bit2_1E384043 0;
BA_ "GenSigTimeoutTime_AGSM" SG_ 2654486595 CBV_bit3_NMCoordinatorBit_1E384043 0;
BA_ "GenSigTimeoutTime_ASBS" SG_ 2654486595 CBV_bit3_NMCoordinatorBit_1E384043 0;
BA_ "GenSigTimeoutTime_BCM" SG_ 2654486595 CBV_bit3_NMCoordinatorBit_1E384043 0;
BA_ "GenSigTimeoutTime_BSM" SG_ 2654486595 CBV_bit3_NMCoordinatorBit_1E384043 0;
BA_ "GenSigTimeoutTime_CADM" SG_ 2654486595 CBV_bit3_NMCoordinatorBit_1E384043 0;
BA_ "GenSigTimeoutTime_DMSM" SG_ 2654486595 CBV_bit3_NMCoordinatorBit_1E384043 0;
BA_ "GenSigTimeoutTime_DTCM" SG_ 2654486595 CBV_bit3_NMCoordinatorBit_1E384043 0;
BA_ "GenSigTimeoutTime_ECM" SG_ 2654486595 CBV_bit3_NMCoordinatorBit_1E384043 0;
BA_ "GenSigTimeoutTime_ELSDM" SG_ 2654486595 CBV_bit3_NMCoordinatorBit_1E384043 0;
BA_ "GenSigTimeoutTime_ESL" SG_ 2654486595 CBV_bit3_NMCoordinatorBit_1E384043 0;
BA_ "GenSigTimeoutTime_GNMM" SG_ 2654486595 CBV_bit3_NMCoordinatorBit_1E384043 0;
BA_ "GenSigTimeoutTime_HCP" SG_ 2654486595 CBV_bit3_NMCoordinatorBit_1E384043 0;
BA_ "GenSigTimeoutTime_IPC" SG_ 2654486595 CBV_bit3_NMCoordinatorBit_1E384043 0;
BA_ "GenSigTimeoutTime_RFHM" SG_ 2654486595 CBV_bit3_NMCoordinatorBit_1E384043 0;
BA_ "GenSigTimeoutTime_SGW" SG_ 2654486595 CBV_bit3_NMCoordinatorBit_1E384043 0;
BA_ "GenSigTimeoutTime_TCM" SG_ 2654486595 CBV_bit3_NMCoordinatorBit_1E384043 0;
BA_ "GenSigTimeoutTime_AGSM" SG_ 2654486595 CBV_bit4_ActiveWakeupBit_1E384043 0;
BA_ "GenSigTimeoutTime_ASBS" SG_ 2654486595 CBV_bit4_ActiveWakeupBit_1E384043 0;
BA_ "GenSigTimeoutTime_BCM" SG_ 2654486595 CBV_bit4_ActiveWakeupBit_1E384043 0;
BA_ "GenSigTimeoutTime_BSM" SG_ 2654486595 CBV_bit4_ActiveWakeupBit_1E384043 0;
BA_ "GenSigTimeoutTime_CADM" SG_ 2654486595 CBV_bit4_ActiveWakeupBit_1E384043 0;
BA_ "GenSigTimeoutTime_DMSM" SG_ 2654486595 CBV_bit4_ActiveWakeupBit_1E384043 0;
BA_ "GenSigTimeoutTime_DTCM" SG_ 2654486595 CBV_bit4_ActiveWakeupBit_1E384043 0;
BA_ "GenSigTimeoutTime_ECM" SG_ 2654486595 CBV_bit4_ActiveWakeupBit_1E384043 0;
BA_ "GenSigTimeoutTime_ELSDM" SG_ 2654486595 CBV_bit4_ActiveWakeupBit_1E384043 0;
BA_ "GenSigTimeoutTime_ADCAM" SG_ 2654486528 CBV_bit0_RepeatMessageRequestBit_1E384000 0;
BA_ "GenSigTimeoutTime_EVCU2" SG_ 2654486528 CBV_bit0_RepeatMessageRequestBit_1E384000 0;
BA_ "GenSigTimeoutTime_VDCM" SG_ 2654486528 CBV_bit0_RepeatMessageRequestBit_1E384000 0;
BA_ "GenSigTimeoutTime_ADCAM" SG_ 2654486528 CBV_bit1_1E384000 0;
BA_ "GenSigTimeoutTime_EVCU2" SG_ 2654486528 CBV_bit1_1E384000 0;
BA_ "GenSigTimeoutTime_VDCM" SG_ 2654486528 CBV_bit1_1E384000 0;
BA_ "GenSigTimeoutTime_ADCAM" SG_ 2654486528 CBV_bit2_1E384000 0;
BA_ "GenSigTimeoutTime_EVCU2" SG_ 2654486528 CBV_bit2_1E384000 0;
BA_ "GenSigTimeoutTime_VDCM" SG_ 2654486528 CBV_bit2_1E384000 0;
BA_ "GenSigTimeoutTime_ADCAM" SG_ 2654486528 CBV_bit3_NMCoordinatorBit_1E384000 0;
BA_ "GenSigTimeoutTime_EVCU2" SG_ 2654486528 CBV_bit3_NMCoordinatorBit_1E384000 0;
BA_ "GenSigTimeoutTime_VDCM" SG_ 2654486528 CBV_bit3_NMCoordinatorBit_1E384000 0;
BA_ "GenSigTimeoutTime_ADCAM" SG_ 2654486528 CBV_bit4_ActiveWakeupBit_1E384000 0;
BA_ "GenSigTimeoutTime_EVCU2" SG_ 2654486528 CBV_bit4_ActiveWakeupBit_1E384000 0;
BA_ "GenSigTimeoutTime_VDCM" SG_ 2654486528 CBV_bit4_ActiveWakeupBit_1E384000 0;
BA_ "GenSigTimeoutTime_ADCAM" SG_ 2654486528 CBV_bit5_1E384000 0;
BA_ "GenSigTimeoutTime_EVCU2" SG_ 2654486528 CBV_bit5_1E384000 0;
BA_ "GenSigTimeoutTime_VDCM" SG_ 2654486528 CBV_bit5_1E384000 0;
BA_ "GenSigTimeoutTime_ADCAM" SG_ 2654486528 CBV_bit6_PartialNtwInfBit_1E384000 0;
BA_ "GenSigTimeoutTime_EVCU2" SG_ 2654486528 CBV_bit6_PartialNtwInfBit_1E384000 0;
BA_ "GenSigTimeoutTime_VDCM" SG_ 2654486528 CBV_bit6_PartialNtwInfBit_1E384000 0;
BA_ "GenSigTimeoutTime_ADCAM" SG_ 2654486528 CBV_bit7_1E384000 0;
BA_ "GenSigTimeoutTime_EVCU2" SG_ 2654486528 CBV_bit7_1E384000 0;
BA_ "GenSigTimeoutTime_VDCM" SG_ 2654486528 CBV_bit7_1E384000 0;
BA_ "GenSigTimeoutTime_ADCAM" SG_ 2654486528 SourceNodeIdentifier_1E384000 0;
BA_ "GenSigTimeoutTime_EVCU2" SG_ 2654486528 SourceNodeIdentifier_1E384000 0;
BA_ "GenSigTimeoutTime_VDCM" SG_ 2654486528 SourceNodeIdentifier_1E384000 0;
BA_ "GenSigTimeoutTime_AGSM" SG_ 2654486528 CBV_bit0_RepeatMessageRequestBit_1E384000 0;
BA_ "GenSigTimeoutTime_ASBS" SG_ 2654486528 CBV_bit0_RepeatMessageRequestBit_1E384000 0;
BA_ "GenSigTimeoutTime_BCM" SG_ 2654486528 CBV_bit0_RepeatMessageRequestBit_1E384000 0;
BA_ "GenSigTimeoutTime_BSM" SG_ 2654486528 CBV_bit0_RepeatMessageRequestBit_1E384000 0;
BA_ "GenSigTimeoutTime_CADM" SG_ 2654486528 CBV_bit0_RepeatMessageRequestBit_1E384000 0;
BA_ "GenSigTimeoutTime_DMSM" SG_ 2654486528 CBV_bit0_RepeatMessageRequestBit_1E384000 0;
BA_ "GenSigTimeoutTime_DTCM" SG_ 2654486528 CBV_bit0_RepeatMessageRequestBit_1E384000 0;
BA_ "GenSigTimeoutTime_ECM" SG_ 2654486528 CBV_bit0_RepeatMessageRequestBit_1E384000 0;
BA_ "GenSigTimeoutTime_ELSDM" SG_ 2654486528 CBV_bit0_RepeatMessageRequestBit_1E384000 0;
BA_ "GenSigTimeoutTime_ESL" SG_ 2654486528 CBV_bit0_RepeatMessageRequestBit_1E384000 0;
BA_ "GenSigTimeoutTime_GNMM" SG_ 2654486528 CBV_bit0_RepeatMessageRequestBit_1E384000 0;
BA_ "GenSigTimeoutTime_HCP" SG_ 2654486528 CBV_bit0_RepeatMessageRequestBit_1E384000 0;
BA_ "GenSigTimeoutTime_IPC" SG_ 2654486528 CBV_bit0_RepeatMessageRequestBit_1E384000 0;
BA_ "GenSigTimeoutTime_RFHM" SG_ 2654486528 CBV_bit0_RepeatMessageRequestBit_1E384000 0;
BA_ "GenSigTimeoutTime_SGW" SG_ 2654486528 CBV_bit0_RepeatMessageRequestBit_1E384000 0;
BA_ "GenSigTimeoutTime_TCM" SG_ 2654486528 CBV_bit0_RepeatMessageRequestBit_1E384000 0;
BA_ "GenSigTimeoutTime_AGSM" SG_ 2654486528 CBV_bit1_1E384000 0;
BA_ "GenSigTimeoutTime_ASBS" SG_ 2654486528 CBV_bit1_1E384000 0;
BA_ "GenSigTimeoutTime_BCM" SG_ 2654486528 CBV_bit1_1E384000 0;
BA_ "GenSigTimeoutTime_BSM" SG_ 2654486528 CBV_bit1_1E384000 0;
BA_ "GenSigTimeoutTime_CADM" SG_ 2654486528 CBV_bit1_1E384000 0;
BA_ "GenSigTimeoutTime_DMSM" SG_ 2654486528 CBV_bit1_1E384000 0;
BA_ "GenSigTimeoutTime_DTCM" SG_ 2654486528 CBV_bit1_1E384000 0;
BA_ "GenSigTimeoutTime_ECM" SG_ 2654486528 CBV_bit1_1E384000 0;
BA_ "GenSigTimeoutTime_ELSDM" SG_ 2654486528 CBV_bit1_1E384000 0;
BA_ "GenSigTimeoutTime_ESL" SG_ 2654486528 CBV_bit1_1E384000 0;
BA_ "GenSigTimeoutTime_GNMM" SG_ 2654486528 CBV_bit1_1E384000 0;
BA_ "GenSigTimeoutTime_HCP" SG_ 2654486528 CBV_bit1_1E384000 0;
BA_ "GenSigTimeoutTime_IPC" SG_ 2654486528 CBV_bit1_1E384000 0;
BA_ "GenSigTimeoutTime_RFHM" SG_ 2654486528 CBV_bit1_1E384000 0;
BA_ "GenSigTimeoutTime_SGW" SG_ 2654486528 CBV_bit1_1E384000 0;
BA_ "GenSigTimeoutTime_TCM" SG_ 2654486528 CBV_bit1_1E384000 0;
BA_ "GenSigTimeoutTime_AGSM" SG_ 2654486528 CBV_bit2_1E384000 0;
BA_ "GenSigTimeoutTime_ASBS" SG_ 2654486528 CBV_bit2_1E384000 0;
BA_ "GenSigTimeoutTime_BCM" SG_ 2654486528 CBV_bit2_1E384000 0;
BA_ "GenSigTimeoutTime_BSM" SG_ 2654486528 CBV_bit2_1E384000 0;
BA_ "GenSigTimeoutTime_CADM" SG_ 2654486528 CBV_bit2_1E384000 0;
BA_ "GenSigTimeoutTime_DMSM" SG_ 2654486528 CBV_bit2_1E384000 0;
BA_ "GenSigTimeoutTime_DTCM" SG_ 2654486528 CBV_bit2_1E384000 0;
BA_ "GenSigTimeoutTime_ECM" SG_ 2654486528 CBV_bit2_1E384000 0;
BA_ "GenSigTimeoutTime_ELSDM" SG_ 2654486528 CBV_bit2_1E384000 0;
BA_ "GenSigTimeoutTime_ESL" SG_ 2654486528 CBV_bit2_1E384000 0;
BA_ "GenSigTimeoutTime_GNMM" SG_ 2654486528 CBV_bit2_1E384000 0;
BA_ "GenSigTimeoutTime_HCP" SG_ 2654486528 CBV_bit2_1E384000 0;
BA_ "GenSigTimeoutTime_IPC" SG_ 2654486528 CBV_bit2_1E384000 0;
BA_ "GenSigTimeoutTime_RFHM" SG_ 2654486528 CBV_bit2_1E384000 0;
BA_ "GenSigTimeoutTime_SGW" SG_ 2654486528 CBV_bit2_1E384000 0;
BA_ "GenSigTimeoutTime_TCM" SG_ 2654486528 CBV_bit2_1E384000 0;
BA_ "GenSigTimeoutTime_AGSM" SG_ 2654486528 CBV_bit3_NMCoordinatorBit_1E384000 0;
BA_ "GenSigTimeoutTime_ASBS" SG_ 2654486528 CBV_bit3_NMCoordinatorBit_1E384000 0;
BA_ "GenSigTimeoutTime_BCM" SG_ 2654486528 CBV_bit3_NMCoordinatorBit_1E384000 0;
BA_ "GenSigTimeoutTime_BSM" SG_ 2654486528 CBV_bit3_NMCoordinatorBit_1E384000 0;
BA_ "GenSigTimeoutTime_CADM" SG_ 2654486528 CBV_bit3_NMCoordinatorBit_1E384000 0;
BA_ "GenSigTimeoutTime_DMSM" SG_ 2654486528 CBV_bit3_NMCoordinatorBit_1E384000 0;
BA_ "GenSigTimeoutTime_DTCM" SG_ 2654486528 CBV_bit3_NMCoordinatorBit_1E384000 0;
BA_ "GenSigTimeoutTime_ECM" SG_ 2654486528 CBV_bit3_NMCoordinatorBit_1E384000 0;
BA_ "GenSigTimeoutTime_ELSDM" SG_ 2654486528 CBV_bit3_NMCoordinatorBit_1E384000 0;
BA_ "GenSigTimeoutTime_ESL" SG_ 2654486528 CBV_bit3_NMCoordinatorBit_1E384000 0;
BA_ "GenSigTimeoutTime_GNMM" SG_ 2654486528 CBV_bit3_NMCoordinatorBit_1E384000 0;
BA_ "GenSigTimeoutTime_HCP" SG_ 2654486528 CBV_bit3_NMCoordinatorBit_1E384000 0;
BA_ "GenSigTimeoutTime_IPC" SG_ 2654486528 CBV_bit3_NMCoordinatorBit_1E384000 0;
BA_ "GenSigTimeoutTime_RFHM" SG_ 2654486528 CBV_bit3_NMCoordinatorBit_1E384000 0;
BA_ "GenSigTimeoutTime_SGW" SG_ 2654486528 CBV_bit3_NMCoordinatorBit_1E384000 0;
BA_ "GenSigTimeoutTime_TCM" SG_ 2654486528 CBV_bit3_NMCoordinatorBit_1E384000 0;
BA_ "GenSigTimeoutTime_AGSM" SG_ 2654486528 CBV_bit4_ActiveWakeupBit_1E384000 0;
BA_ "GenSigTimeoutTime_ASBS" SG_ 2654486528 CBV_bit4_ActiveWakeupBit_1E384000 0;
BA_ "GenSigTimeoutTime_BCM" SG_ 2654486528 CBV_bit4_ActiveWakeupBit_1E384000 0;
BA_ "GenSigTimeoutTime_BSM" SG_ 2654486528 CBV_bit4_ActiveWakeupBit_1E384000 0;
BA_ "GenSigTimeoutTime_CADM" SG_ 2654486528 CBV_bit4_ActiveWakeupBit_1E384000 0;
BA_ "GenSigTimeoutTime_DMSM" SG_ 2654486528 CBV_bit4_ActiveWakeupBit_1E384000 0;
BA_ "GenSigTimeoutTime_DTCM" SG_ 2654486528 CBV_bit4_ActiveWakeupBit_1E384000 0;
BA_ "GenSigTimeoutTime_ECM" SG_ 2654486528 CBV_bit4_ActiveWakeupBit_1E384000 0;
BA_ "GenSigTimeoutTime_ELSDM" SG_ 2654486528 CBV_bit4_ActiveWakeupBit_1E384000 0;
BA_ "GenSigTimeoutTime_ESL" SG_ 2654486528 CBV_bit4_ActiveWakeupBit_1E384000 0;
BA_ "GenSigTimeoutTime_GNMM" SG_ 2654486528 CBV_bit4_ActiveWakeupBit_1E384000 0;
BA_ "GenSigTimeoutTime_HCP" SG_ 2654486528 CBV_bit4_ActiveWakeupBit_1E384000 0;
BA_ "GenSigTimeoutTime_IPC" SG_ 2654486528 CBV_bit4_ActiveWakeupBit_1E384000 0;
BA_ "GenSigTimeoutTime_RFHM" SG_ 2654486528 CBV_bit4_ActiveWakeupBit_1E384000 0;
BA_ "GenSigTimeoutTime_SGW" SG_ 2654486528 CBV_bit4_ActiveWakeupBit_1E384000 0;
BA_ "GenSigTimeoutTime_TCM" SG_ 2654486528 CBV_bit4_ActiveWakeupBit_1E384000 0;
BA_ "GenSigTimeoutTime_AGSM" SG_ 2654486528 CBV_bit5_1E384000 0;
BA_ "GenSigTimeoutTime_ASBS" SG_ 2654486528 CBV_bit5_1E384000 0;
BA_ "GenSigTimeoutTime_BCM" SG_ 2654486528 CBV_bit5_1E384000 0;
BA_ "GenSigTimeoutTime_BSM" SG_ 2654486528 CBV_bit5_1E384000 0;
BA_ "GenSigTimeoutTime_CADM" SG_ 2654486528 CBV_bit5_1E384000 0;
BA_ "GenSigTimeoutTime_DMSM" SG_ 2654486528 CBV_bit5_1E384000 0;
BA_ "GenSigTimeoutTime_DTCM" SG_ 2654486528 CBV_bit5_1E384000 0;
BA_ "GenSigTimeoutTime_ECM" SG_ 2654486528 CBV_bit5_1E384000 0;
BA_ "GenSigTimeoutTime_ELSDM" SG_ 2654486528 CBV_bit5_1E384000 0;
BA_ "GenSigTimeoutTime_ESL" SG_ 2654486528 CBV_bit5_1E384000 0;
BA_ "GenSigTimeoutTime_GNMM" SG_ 2654486528 CBV_bit5_1E384000 0;
BA_ "GenSigTimeoutTime_HCP" SG_ 2654486528 CBV_bit5_1E384000 0;
BA_ "GenSigTimeoutTime_IPC" SG_ 2654486528 CBV_bit5_1E384000 0;
BA_ "GenSigTimeoutTime_RFHM" SG_ 2654486528 CBV_bit5_1E384000 0;
BA_ "GenSigTimeoutTime_SGW" SG_ 2654486528 CBV_bit5_1E384000 0;
BA_ "GenSigTimeoutTime_TCM" SG_ 2654486528 CBV_bit5_1E384000 0;
BA_ "GenSigTimeoutTime_AGSM" SG_ 2654486528 CBV_bit6_PartialNtwInfBit_1E384000 0;
BA_ "GenSigTimeoutTime_ASBS" SG_ 2654486528 CBV_bit6_PartialNtwInfBit_1E384000 0;
BA_ "GenSigTimeoutTime_BCM" SG_ 2654486528 CBV_bit6_PartialNtwInfBit_1E384000 0;
BA_ "GenSigTimeoutTime_BSM" SG_ 2654486528 CBV_bit6_PartialNtwInfBit_1E384000 0;
BA_ "GenSigTimeoutTime_CADM" SG_ 2654486528 CBV_bit6_PartialNtwInfBit_1E384000 0;
BA_ "GenSigTimeoutTime_DMSM" SG_ 2654486528 CBV_bit6_PartialNtwInfBit_1E384000 0;
BA_ "GenSigTimeoutTime_DTCM" SG_ 2654486528 CBV_bit6_PartialNtwInfBit_1E384000 0;
BA_ "GenSigTimeoutTime_ECM" SG_ 2654486528 CBV_bit6_PartialNtwInfBit_1E384000 0;
BA_ "GenSigTimeoutTime_ELSDM" SG_ 2654486528 CBV_bit6_PartialNtwInfBit_1E384000 0;
BA_ "GenSigTimeoutTime_ESL" SG_ 2654486528 CBV_bit6_PartialNtwInfBit_1E384000 0;
BA_ "GenSigTimeoutTime_GNMM" SG_ 2654486528 CBV_bit6_PartialNtwInfBit_1E384000 0;
BA_ "GenSigTimeoutTime_HCP" SG_ 2654486528 CBV_bit6_PartialNtwInfBit_1E384000 0;
BA_ "GenSigTimeoutTime_IPC" SG_ 2654486528 CBV_bit6_PartialNtwInfBit_1E384000 0;
BA_ "GenSigTimeoutTime_RFHM" SG_ 2654486528 CBV_bit6_PartialNtwInfBit_1E384000 0;
BA_ "GenSigTimeoutTime_SGW" SG_ 2654486528 CBV_bit6_PartialNtwInfBit_1E384000 0;
BA_ "GenSigTimeoutTime_TCM" SG_ 2654486528 CBV_bit6_PartialNtwInfBit_1E384000 0;
BA_ "GenSigTimeoutTime_AGSM" SG_ 2654486528 CBV_bit7_1E384000 0;
BA_ "GenSigTimeoutTime_ASBS" SG_ 2654486528 CBV_bit7_1E384000 0;
BA_ "GenSigTimeoutTime_BCM" SG_ 2654486528 CBV_bit7_1E384000 0;
BA_ "GenSigTimeoutTime_BSM" SG_ 2654486528 CBV_bit7_1E384000 0;
BA_ "GenSigTimeoutTime_CADM" SG_ 2654486528 CBV_bit7_1E384000 0;
BA_ "GenSigTimeoutTime_DMSM" SG_ 2654486528 CBV_bit7_1E384000 0;
BA_ "GenSigTimeoutTime_DTCM" SG_ 2654486528 CBV_bit7_1E384000 0;
BA_ "GenSigTimeoutTime_ECM" SG_ 2654486528 CBV_bit7_1E384000 0;
BA_ "GenSigTimeoutTime_ELSDM" SG_ 2654486528 CBV_bit7_1E384000 0;
BA_ "GenSigTimeoutTime_ESL" SG_ 2654486528 CBV_bit7_1E384000 0;
BA_ "GenSigTimeoutTime_GNMM" SG_ 2654486528 CBV_bit7_1E384000 0;
BA_ "GenSigTimeoutTime_HCP" SG_ 2654486528 CBV_bit7_1E384000 0;
BA_ "GenSigTimeoutTime_IPC" SG_ 2654486528 CBV_bit7_1E384000 0;
BA_ "GenSigTimeoutTime_RFHM" SG_ 2654486528 CBV_bit7_1E384000 0;
BA_ "GenSigTimeoutTime_SGW" SG_ 2654486528 CBV_bit7_1E384000 0;
BA_ "GenSigTimeoutTime_TCM" SG_ 2654486528 CBV_bit7_1E384000 0;
BA_ "GenSigTimeoutTime_AGSM" SG_ 2654486528 SourceNodeIdentifier_1E384000 0;
BA_ "GenSigTimeoutTime_ASBS" SG_ 2654486528 SourceNodeIdentifier_1E384000 0;
BA_ "GenSigTimeoutTime_BCM" SG_ 2654486528 SourceNodeIdentifier_1E384000 0;
BA_ "GenSigTimeoutTime_BSM" SG_ 2654486528 SourceNodeIdentifier_1E384000 0;
BA_ "GenSigTimeoutTime_CADM" SG_ 2654486528 SourceNodeIdentifier_1E384000 0;
BA_ "GenSigTimeoutTime_DMSM" SG_ 2654486528 SourceNodeIdentifier_1E384000 0;
BA_ "GenSigTimeoutTime_DTCM" SG_ 2654486528 SourceNodeIdentifier_1E384000 0;
BA_ "GenSigTimeoutTime_ECM" SG_ 2654486528 SourceNodeIdentifier_1E384000 0;
BA_ "GenSigTimeoutTime_ELSDM" SG_ 2654486528 SourceNodeIdentifier_1E384000 0;
BA_ "GenSigTimeoutTime_ESL" SG_ 2654486528 SourceNodeIdentifier_1E384000 0;
BA_ "GenSigTimeoutTime_GNMM" SG_ 2654486528 SourceNodeIdentifier_1E384000 0;
BA_ "GenSigTimeoutTime_HCP" SG_ 2654486528 SourceNodeIdentifier_1E384000 0;
BA_ "GenSigTimeoutTime_IPC" SG_ 2654486528 SourceNodeIdentifier_1E384000 0;
BA_ "GenSigTimeoutTime_RFHM" SG_ 2654486528 SourceNodeIdentifier_1E384000 0;
BA_ "GenSigTimeoutTime_SGW" SG_ 2654486528 SourceNodeIdentifier_1E384000 0;
BA_ "GenSigTimeoutTime_TCM" SG_ 2654486528 SourceNodeIdentifier_1E384000 0;
BA_ "GenSigTimeoutTime_ADCAM" SG_ 2654486534 CBV_bit0_RepeatMessageRequestBit_1E384006 0;
BA_ "GenSigTimeoutTime_EVCU2" SG_ 2654486534 CBV_bit0_RepeatMessageRequestBit_1E384006 0;
BA_ "GenSigTimeoutTime_VDCM" SG_ 2654486534 CBV_bit0_RepeatMessageRequestBit_1E384006 0;
BA_ "GenSigTimeoutTime_ADCAM" SG_ 2654486534 CBV_bit1_1E384006 0;
BA_ "GenSigTimeoutTime_EVCU2" SG_ 2654486534 CBV_bit1_1E384006 0;
BA_ "GenSigTimeoutTime_VDCM" SG_ 2654486534 CBV_bit1_1E384006 0;
BA_ "GenSigTimeoutTime_ADCAM" SG_ 2654486534 CBV_bit2_1E384006 0;
BA_ "GenSigTimeoutTime_EVCU2" SG_ 2654486534 CBV_bit2_1E384006 0;
BA_ "GenSigTimeoutTime_VDCM" SG_ 2654486534 CBV_bit2_1E384006 0;
BA_ "GenSigTimeoutTime_ADCAM" SG_ 2654486534 CBV_bit3_NMCoordinatorBit_1E384006 0;
BA_ "GenSigTimeoutTime_EVCU2" SG_ 2654486534 CBV_bit3_NMCoordinatorBit_1E384006 0;
BA_ "GenSigTimeoutTime_VDCM" SG_ 2654486534 CBV_bit3_NMCoordinatorBit_1E384006 0;
BA_ "GenSigTimeoutTime_ADCAM" SG_ 2654486534 CBV_bit4_ActiveWakeupBit_1E384006 0;
BA_ "GenSigTimeoutTime_EVCU2" SG_ 2654486534 CBV_bit4_ActiveWakeupBit_1E384006 0;
BA_ "GenSigTimeoutTime_VDCM" SG_ 2654486534 CBV_bit4_ActiveWakeupBit_1E384006 0;
BA_ "GenSigTimeoutTime_ADCAM" SG_ 2654486534 CBV_bit5_1E384006 0;
BA_ "GenSigTimeoutTime_EVCU2" SG_ 2654486534 CBV_bit5_1E384006 0;
BA_ "GenSigTimeoutTime_VDCM" SG_ 2654486534 CBV_bit5_1E384006 0;
BA_ "GenSigTimeoutTime_ADCAM" SG_ 2654486534 CBV_bit6_PartialNtwInfBit_1E384006 0;
BA_ "GenSigTimeoutTime_EVCU2" SG_ 2654486534 CBV_bit6_PartialNtwInfBit_1E384006 0;
BA_ "GenSigTimeoutTime_VDCM" SG_ 2654486534 CBV_bit6_PartialNtwInfBit_1E384006 0;
BA_ "GenSigTimeoutTime_ADCAM" SG_ 2654486534 CBV_bit7_1E384006 0;
BA_ "GenSigTimeoutTime_EVCU2" SG_ 2654486534 CBV_bit7_1E384006 0;
BA_ "GenSigTimeoutTime_VDCM" SG_ 2654486534 CBV_bit7_1E384006 0;
BA_ "GenSigTimeoutTime_ADCAM" SG_ 2654486534 SourceNodeIdentifier_1E384006 0;
BA_ "GenSigTimeoutTime_EVCU2" SG_ 2654486534 SourceNodeIdentifier_1E384006 0;
BA_ "GenSigTimeoutTime_VDCM" SG_ 2654486534 SourceNodeIdentifier_1E384006 0;
BA_ "GenSigTimeoutTime_AGSM" SG_ 2654486534 CBV_bit0_RepeatMessageRequestBit_1E384006 0;
BA_ "GenSigTimeoutTime_ASBS" SG_ 2654486534 CBV_bit0_RepeatMessageRequestBit_1E384006 0;
BA_ "GenSigTimeoutTime_BCM" SG_ 2654486534 CBV_bit0_RepeatMessageRequestBit_1E384006 0;
BA_ "GenSigTimeoutTime_BSM" SG_ 2654486534 CBV_bit0_RepeatMessageRequestBit_1E384006 0;
BA_ "GenSigTimeoutTime_CADM" SG_ 2654486534 CBV_bit0_RepeatMessageRequestBit_1E384006 0;
BA_ "GenSigTimeoutTime_DMSM" SG_ 2654486534 CBV_bit0_RepeatMessageRequestBit_1E384006 0;
BA_ "GenSigTimeoutTime_DTCM" SG_ 2654486534 CBV_bit0_RepeatMessageRequestBit_1E384006 0;
BA_ "GenSigTimeoutTime_ECM" SG_ 2654486534 CBV_bit0_RepeatMessageRequestBit_1E384006 0;
BA_ "GenSigTimeoutTime_ELSDM" SG_ 2654486534 CBV_bit0_RepeatMessageRequestBit_1E384006 0;
BA_ "GenSigTimeoutTime_ESL" SG_ 2654486534 CBV_bit0_RepeatMessageRequestBit_1E384006 0;
BA_ "GenSigTimeoutTime_GNMM" SG_ 2654486534 CBV_bit0_RepeatMessageRequestBit_1E384006 0;
BA_ "GenSigTimeoutTime_HCP" SG_ 2654486534 CBV_bit0_RepeatMessageRequestBit_1E384006 0;
BA_ "GenSigTimeoutTime_IPC" SG_ 2654486534 CBV_bit0_RepeatMessageRequestBit_1E384006 0;
BA_ "GenSigTimeoutTime_RFHM" SG_ 2654486534 CBV_bit0_RepeatMessageRequestBit_1E384006 0;
BA_ "GenSigTimeoutTime_SGW" SG_ 2654486534 CBV_bit0_RepeatMessageRequestBit_1E384006 0;
BA_ "GenSigTimeoutTime_TCM" SG_ 2654486534 CBV_bit0_RepeatMessageRequestBit_1E384006 0;
BA_ "GenSigTimeoutTime_AGSM" SG_ 2654486534 CBV_bit1_1E384006 0;
BA_ "GenSigTimeoutTime_ASBS" SG_ 2654486534 CBV_bit1_1E384006 0;
BA_ "GenSigTimeoutTime_BCM" SG_ 2654486534 CBV_bit1_1E384006 0;
BA_ "GenSigTimeoutTime_BSM" SG_ 2654486534 CBV_bit1_1E384006 0;
BA_ "GenSigTimeoutTime_CADM" SG_ 2654486534 CBV_bit1_1E384006 0;
BA_ "GenSigTimeoutTime_DMSM" SG_ 2654486534 CBV_bit1_1E384006 0;
BA_ "GenSigTimeoutTime_DTCM" SG_ 2654486534 CBV_bit1_1E384006 0;
BA_ "GenSigTimeoutTime_ECM" SG_ 2654486534 CBV_bit1_1E384006 0;
BA_ "GenSigTimeoutTime_ELSDM" SG_ 2654486534 CBV_bit1_1E384006 0;
BA_ "GenSigTimeoutTime_ESL" SG_ 2654486534 CBV_bit1_1E384006 0;
BA_ "GenSigTimeoutTime_GNMM" SG_ 2654486534 CBV_bit1_1E384006 0;
BA_ "GenSigTimeoutTime_HCP" SG_ 2654486534 CBV_bit1_1E384006 0;
BA_ "GenSigTimeoutTime_IPC" SG_ 2654486534 CBV_bit1_1E384006 0;
BA_ "GenSigTimeoutTime_RFHM" SG_ 2654486534 CBV_bit1_1E384006 0;
BA_ "GenSigTimeoutTime_SGW" SG_ 2654486534 CBV_bit1_1E384006 0;
BA_ "GenSigTimeoutTime_TCM" SG_ 2654486534 CBV_bit1_1E384006 0;
BA_ "GenSigTimeoutTime_AGSM" SG_ 2654486534 CBV_bit2_1E384006 0;
BA_ "GenSigTimeoutTime_ASBS" SG_ 2654486534 CBV_bit2_1E384006 0;
BA_ "GenSigTimeoutTime_BCM" SG_ 2654486534 CBV_bit2_1E384006 0;
BA_ "GenSigTimeoutTime_BSM" SG_ 2654486534 CBV_bit2_1E384006 0;
BA_ "GenSigTimeoutTime_CADM" SG_ 2654486534 CBV_bit2_1E384006 0;
BA_ "GenSigTimeoutTime_DMSM" SG_ 2654486534 CBV_bit2_1E384006 0;
BA_ "GenSigTimeoutTime_DTCM" SG_ 2654486534 CBV_bit2_1E384006 0;
BA_ "GenSigTimeoutTime_ECM" SG_ 2654486534 CBV_bit2_1E384006 0;
BA_ "GenSigTimeoutTime_ELSDM" SG_ 2654486534 CBV_bit2_1E384006 0;
BA_ "GenSigTimeoutTime_ESL" SG_ 2654486534 CBV_bit2_1E384006 0;
BA_ "GenSigTimeoutTime_GNMM" SG_ 2654486534 CBV_bit2_1E384006 0;
BA_ "GenSigTimeoutTime_HCP" SG_ 2654486534 CBV_bit2_1E384006 0;
BA_ "GenSigTimeoutTime_IPC" SG_ 2654486534 CBV_bit2_1E384006 0;
BA_ "GenSigTimeoutTime_RFHM" SG_ 2654486534 CBV_bit2_1E384006 0;
BA_ "GenSigTimeoutTime_SGW" SG_ 2654486534 CBV_bit2_1E384006 0;
BA_ "GenSigTimeoutTime_TCM" SG_ 2654486534 CBV_bit2_1E384006 0;
BA_ "GenSigTimeoutTime_AGSM" SG_ 2654486534 CBV_bit3_NMCoordinatorBit_1E384006 0;
BA_ "GenSigTimeoutTime_ASBS" SG_ 2654486534 CBV_bit3_NMCoordinatorBit_1E384006 0;
BA_ "GenSigTimeoutTime_BCM" SG_ 2654486534 CBV_bit3_NMCoordinatorBit_1E384006 0;
BA_ "GenSigTimeoutTime_BSM" SG_ 2654486534 CBV_bit3_NMCoordinatorBit_1E384006 0;
BA_ "GenSigTimeoutTime_CADM" SG_ 2654486534 CBV_bit3_NMCoordinatorBit_1E384006 0;
BA_ "GenSigTimeoutTime_DMSM" SG_ 2654486534 CBV_bit3_NMCoordinatorBit_1E384006 0;
BA_ "GenSigTimeoutTime_DTCM" SG_ 2654486534 CBV_bit3_NMCoordinatorBit_1E384006 0;
BA_ "GenSigTimeoutTime_AGSM" SG_ 2654486633 CBV_bit2_1E384069 0;
BA_ "GenSigTimeoutTime_ASBS" SG_ 2654486633 CBV_bit2_1E384069 0;
BA_ "GenSigTimeoutTime_BCM" SG_ 2654486633 CBV_bit2_1E384069 0;
BA_ "GenSigTimeoutTime_BSM" SG_ 2654486633 CBV_bit2_1E384069 0;
BA_ "GenSigTimeoutTime_CADM" SG_ 2654486633 CBV_bit2_1E384069 0;
BA_ "GenSigTimeoutTime_DMSM" SG_ 2654486633 CBV_bit2_1E384069 0;
BA_ "GenSigTimeoutTime_DTCM" SG_ 2654486633 CBV_bit2_1E384069 0;
BA_ "GenSigTimeoutTime_ECM" SG_ 2654486633 CBV_bit2_1E384069 0;
BA_ "GenSigTimeoutTime_ELSDM" SG_ 2654486633 CBV_bit2_1E384069 0;
BA_ "GenSigTimeoutTime_ESL" SG_ 2654486633 CBV_bit2_1E384069 0;
BA_ "GenSigTimeoutTime_GNMM" SG_ 2654486633 CBV_bit2_1E384069 0;
BA_ "GenSigTimeoutTime_HCP" SG_ 2654486633 CBV_bit2_1E384069 0;
BA_ "GenSigTimeoutTime_IPC" SG_ 2654486633 CBV_bit2_1E384069 0;
BA_ "GenSigTimeoutTime_RFHM" SG_ 2654486633 CBV_bit2_1E384069 0;
BA_ "GenSigTimeoutTime_SGW" SG_ 2654486633 CBV_bit2_1E384069 0;
BA_ "GenSigTimeoutTime_TCM" SG_ 2654486633 CBV_bit2_1E384069 0;
BA_ "GenSigTimeoutTime_AGSM" SG_ 2654486633 CBV_bit3_NMCoordinatorBit_1E384069 0;
BA_ "GenSigTimeoutTime_ASBS" SG_ 2654486633 CBV_bit3_NMCoordinatorBit_1E384069 0;
BA_ "GenSigTimeoutTime_BCM" SG_ 2654486633 CBV_bit3_NMCoordinatorBit_1E384069 0;
BA_ "GenSigTimeoutTime_BSM" SG_ 2654486633 CBV_bit3_NMCoordinatorBit_1E384069 0;
BA_ "GenSigTimeoutTime_CADM" SG_ 2654486633 CBV_bit3_NMCoordinatorBit_1E384069 0;
BA_ "GenSigTimeoutTime_DMSM" SG_ 2654486633 CBV_bit3_NMCoordinatorBit_1E384069 0;
BA_ "GenSigTimeoutTime_DTCM" SG_ 2654486633 CBV_bit3_NMCoordinatorBit_1E384069 0;
BA_ "GenSigTimeoutTime_ECM" SG_ 2654486633 CBV_bit3_NMCoordinatorBit_1E384069 0;
BA_ "GenSigTimeoutTime_ELSDM" SG_ 2654486633 CBV_bit3_NMCoordinatorBit_1E384069 0;
BA_ "GenSigTimeoutTime_ESL" SG_ 2654486633 CBV_bit3_NMCoordinatorBit_1E384069 0;
BA_ "GenSigTimeoutTime_GNMM" SG_ 2654486633 CBV_bit3_NMCoordinatorBit_1E384069 0;
BA_ "GenSigTimeoutTime_HCP" SG_ 2654486633 CBV_bit3_NMCoordinatorBit_1E384069 0;
BA_ "GenSigTimeoutTime_IPC" SG_ 2654486633 CBV_bit3_NMCoordinatorBit_1E384069 0;
BA_ "GenSigTimeoutTime_RFHM" SG_ 2654486633 CBV_bit3_NMCoordinatorBit_1E384069 0;
BA_ "GenSigTimeoutTime_SGW" SG_ 2654486633 CBV_bit3_NMCoordinatorBit_1E384069 0;
BA_ "GenSigTimeoutTime_TCM" SG_ 2654486633 CBV_bit3_NMCoordinatorBit_1E384069 0;
BA_ "GenSigTimeoutTime_AGSM" SG_ 2654486633 CBV_bit4_ActiveWakeupBit_1E384069 0;
BA_ "GenSigTimeoutTime_ASBS" SG_ 2654486633 CBV_bit4_ActiveWakeupBit_1E384069 0;
BA_ "GenSigTimeoutTime_BCM" SG_ 2654486633 CBV_bit4_ActiveWakeupBit_1E384069 0;
BA_ "GenSigTimeoutTime_BSM" SG_ 2654486633 CBV_bit4_ActiveWakeupBit_1E384069 0;
BA_ "GenSigTimeoutTime_CADM" SG_ 2654486633 CBV_bit4_ActiveWakeupBit_1E384069 0;
BA_ "GenSigTimeoutTime_DMSM" SG_ 2654486633 CBV_bit4_ActiveWakeupBit_1E384069 0;
BA_ "GenSigTimeoutTime_DTCM" SG_ 2654486633 CBV_bit4_ActiveWakeupBit_1E384069 0;
BA_ "GenSigTimeoutTime_ECM" SG_ 2654486633 CBV_bit4_ActiveWakeupBit_1E384069 0;
BA_ "GenSigTimeoutTime_ELSDM" SG_ 2654486633 CBV_bit4_ActiveWakeupBit_1E384069 0;
BA_ "GenSigTimeoutTime_ESL" SG_ 2654486633 CBV_bit4_ActiveWakeupBit_1E384069 0;
BA_ "GenSigTimeoutTime_GNMM" SG_ 2654486633 CBV_bit4_ActiveWakeupBit_1E384069 0;
BA_ "GenSigTimeoutTime_HCP" SG_ 2654486633 CBV_bit4_ActiveWakeupBit_1E384069 0;
BA_ "GenSigTimeoutTime_IPC" SG_ 2654486633 CBV_bit4_ActiveWakeupBit_1E384069 0;
BA_ "GenSigTimeoutTime_RFHM" SG_ 2654486633 CBV_bit4_ActiveWakeupBit_1E384069 0;
BA_ "GenSigTimeoutTime_SGW" SG_ 2654486633 CBV_bit4_ActiveWakeupBit_1E384069 0;
BA_ "GenSigTimeoutTime_TCM" SG_ 2654486633 CBV_bit4_ActiveWakeupBit_1E384069 0;
BA_ "GenSigTimeoutTime_AGSM" SG_ 2654486633 CBV_bit5_1E384069 0;
BA_ "GenSigTimeoutTime_ASBS" SG_ 2654486633 CBV_bit5_1E384069 0;
BA_ "GenSigTimeoutTime_BCM" SG_ 2654486633 CBV_bit5_1E384069 0;
BA_ "GenSigTimeoutTime_BSM" SG_ 2654486633 CBV_bit5_1E384069 0;
BA_ "GenSigTimeoutTime_CADM" SG_ 2654486633 CBV_bit5_1E384069 0;
BA_ "GenSigTimeoutTime_DMSM" SG_ 2654486633 CBV_bit5_1E384069 0;
BA_ "GenSigTimeoutTime_DTCM" SG_ 2654486633 CBV_bit5_1E384069 0;
BA_ "GenSigTimeoutTime_ECM" SG_ 2654486633 CBV_bit5_1E384069 0;
BA_ "GenSigTimeoutTime_ELSDM" SG_ 2654486633 CBV_bit5_1E384069 0;
BA_ "GenSigTimeoutTime_ESL" SG_ 2654486633 CBV_bit5_1E384069 0;
BA_ "GenSigTimeoutTime_GNMM" SG_ 2654486633 CBV_bit5_1E384069 0;
BA_ "GenSigTimeoutTime_HCP" SG_ 2654486633 CBV_bit5_1E384069 0;
BA_ "GenSigTimeoutTime_IPC" SG_ 2654486633 CBV_bit5_1E384069 0;
BA_ "GenSigTimeoutTime_RFHM" SG_ 2654486633 CBV_bit5_1E384069 0;
BA_ "GenSigTimeoutTime_SGW" SG_ 2654486633 CBV_bit5_1E384069 0;
BA_ "GenSigTimeoutTime_TCM" SG_ 2654486633 CBV_bit5_1E384069 0;
BA_ "GenSigTimeoutTime_AGSM" SG_ 2654486633 CBV_bit6_PartialNtwInfBit_1E384069 0;
BA_ "GenSigTimeoutTime_ASBS" SG_ 2654486633 CBV_bit6_PartialNtwInfBit_1E384069 0;
BA_ "GenSigTimeoutTime_BCM" SG_ 2654486633 CBV_bit6_PartialNtwInfBit_1E384069 0;
BA_ "GenSigTimeoutTime_BSM" SG_ 2654486633 CBV_bit6_PartialNtwInfBit_1E384069 0;
BA_ "GenSigTimeoutTime_CADM" SG_ 2654486633 CBV_bit6_PartialNtwInfBit_1E384069 0;
BA_ "GenSigTimeoutTime_DMSM" SG_ 2654486633 CBV_bit6_PartialNtwInfBit_1E384069 0;
BA_ "GenSigTimeoutTime_DTCM" SG_ 2654486633 CBV_bit6_PartialNtwInfBit_1E384069 0;
BA_ "GenSigTimeoutTime_ECM" SG_ 2654486633 CBV_bit6_PartialNtwInfBit_1E384069 0;
BA_ "GenSigTimeoutTime_ELSDM" SG_ 2654486633 CBV_bit6_PartialNtwInfBit_1E384069 0;
BA_ "GenSigTimeoutTime_ESL" SG_ 2654486633 CBV_bit6_PartialNtwInfBit_1E384069 0;
BA_ "GenSigTimeoutTime_GNMM" SG_ 2654486633 CBV_bit6_PartialNtwInfBit_1E384069 0;
BA_ "GenSigTimeoutTime_HCP" SG_ 2654486633 CBV_bit6_PartialNtwInfBit_1E384069 0;
BA_ "GenSigTimeoutTime_IPC" SG_ 2654486633 CBV_bit6_PartialNtwInfBit_1E384069 0;
BA_ "GenSigTimeoutTime_RFHM" SG_ 2654486633 CBV_bit6_PartialNtwInfBit_1E384069 0;
BA_ "GenSigTimeoutTime_SGW" SG_ 2654486633 CBV_bit6_PartialNtwInfBit_1E384069 0;
BA_ "GenSigTimeoutTime_TCM" SG_ 2654486633 CBV_bit6_PartialNtwInfBit_1E384069 0;
BA_ "GenSigTimeoutTime_AGSM" SG_ 2654486633 CBV_bit7_1E384069 0;
BA_ "GenSigTimeoutTime_ASBS" SG_ 2654486633 CBV_bit7_1E384069 0;
BA_ "GenSigTimeoutTime_BCM" SG_ 2654486633 CBV_bit7_1E384069 0;
BA_ "GenSigTimeoutTime_BSM" SG_ 2654486633 CBV_bit7_1E384069 0;
BA_ "GenSigTimeoutTime_CADM" SG_ 2654486633 CBV_bit7_1E384069 0;
BA_ "GenSigTimeoutTime_DMSM" SG_ 2654486633 CBV_bit7_1E384069 0;
BA_ "GenSigTimeoutTime_DTCM" SG_ 2654486633 CBV_bit7_1E384069 0;
BA_ "GenSigTimeoutTime_ECM" SG_ 2654486633 CBV_bit7_1E384069 0;
BA_ "GenSigTimeoutTime_ELSDM" SG_ 2654486633 CBV_bit7_1E384069 0;
BA_ "GenSigTimeoutTime_ESL" SG_ 2654486633 CBV_bit7_1E384069 0;
BA_ "GenSigTimeoutTime_GNMM" SG_ 2654486633 CBV_bit7_1E384069 0;
BA_ "GenSigTimeoutTime_HCP" SG_ 2654486633 CBV_bit7_1E384069 0;
BA_ "GenSigTimeoutTime_IPC" SG_ 2654486633 CBV_bit7_1E384069 0;
BA_ "GenSigTimeoutTime_RFHM" SG_ 2654486633 CBV_bit7_1E384069 0;
BA_ "GenSigTimeoutTime_SGW" SG_ 2654486633 CBV_bit7_1E384069 0;
BA_ "GenSigTimeoutTime_TCM" SG_ 2654486633 CBV_bit7_1E384069 0;
BA_ "GenSigTimeoutTime_AGSM" SG_ 2654486633 SourceNodeIdentifier_1E384069 0;
BA_ "GenSigTimeoutTime_ASBS" SG_ 2654486633 SourceNodeIdentifier_1E384069 0;
BA_ "GenSigTimeoutTime_BCM" SG_ 2654486633 SourceNodeIdentifier_1E384069 0;
BA_ "GenSigTimeoutTime_BSM" SG_ 2654486633 SourceNodeIdentifier_1E384069 0;
BA_ "GenSigTimeoutTime_CADM" SG_ 2654486633 SourceNodeIdentifier_1E384069 0;
BA_ "GenSigTimeoutTime_DMSM" SG_ 2654486633 SourceNodeIdentifier_1E384069 0;
BA_ "GenSigTimeoutTime_DTCM" SG_ 2654486633 SourceNodeIdentifier_1E384069 0;
BA_ "GenSigTimeoutTime_ECM" SG_ 2654486633 SourceNodeIdentifier_1E384069 0;
BA_ "GenSigTimeoutTime_ELSDM" SG_ 2654486633 SourceNodeIdentifier_1E384069 0;
BA_ "GenSigTimeoutTime_ESL" SG_ 2654486633 SourceNodeIdentifier_1E384069 0;
BA_ "GenSigTimeoutTime_GNMM" SG_ 2654486633 SourceNodeIdentifier_1E384069 0;
BA_ "GenSigTimeoutTime_HCP" SG_ 2654486633 SourceNodeIdentifier_1E384069 0;
BA_ "GenSigTimeoutTime_IPC" SG_ 2654486633 SourceNodeIdentifier_1E384069 0;
BA_ "GenSigTimeoutTime_RFHM" SG_ 2654486633 SourceNodeIdentifier_1E384069 0;
BA_ "GenSigTimeoutTime_SGW" SG_ 2654486633 SourceNodeIdentifier_1E384069 0;
BA_ "GenSigTimeoutTime_TCM" SG_ 2654486633 SourceNodeIdentifier_1E384069 0;
BA_ "GenSigTimeoutTime_AGSM" SG_ 2654486549 CBV_bit0_RepeatMessageRequestBit_1E384015 0;
BA_ "GenSigTimeoutTime_ASBS" SG_ 2654486549 CBV_bit0_RepeatMessageRequestBit_1E384015 0;
BA_ "GenSigTimeoutTime_BCM" SG_ 2654486549 CBV_bit0_RepeatMessageRequestBit_1E384015 0;
BA_ "GenSigTimeoutTime_BSM" SG_ 2654486549 CBV_bit0_RepeatMessageRequestBit_1E384015 0;
BA_ "GenSigTimeoutTime_CADM" SG_ 2654486549 CBV_bit0_RepeatMessageRequestBit_1E384015 0;
BA_ "GenSigTimeoutTime_DMSM" SG_ 2654486549 CBV_bit0_RepeatMessageRequestBit_1E384015 0;
BA_ "GenSigTimeoutTime_DTCM" SG_ 2654486549 CBV_bit0_RepeatMessageRequestBit_1E384015 0;
BA_ "GenSigTimeoutTime_ECM" SG_ 2654486549 CBV_bit0_RepeatMessageRequestBit_1E384015 0;
BA_ "GenSigTimeoutTime_ELSDM" SG_ 2654486549 CBV_bit0_RepeatMessageRequestBit_1E384015 0;
BA_ "GenSigTimeoutTime_ESL" SG_ 2654486549 CBV_bit0_RepeatMessageRequestBit_1E384015 0;
BA_ "GenSigTimeoutTime_GNMM" SG_ 2654486549 CBV_bit0_RepeatMessageRequestBit_1E384015 0;
BA_ "GenSigTimeoutTime_HCP" SG_ 2654486549 CBV_bit0_RepeatMessageRequestBit_1E384015 0;
BA_ "GenSigTimeoutTime_IPC" SG_ 2654486549 CBV_bit0_RepeatMessageRequestBit_1E384015 0;
BA_ "GenSigTimeoutTime_RFHM" SG_ 2654486549 CBV_bit0_RepeatMessageRequestBit_1E384015 0;
BA_ "GenSigTimeoutTime_SGW" SG_ 2654486549 CBV_bit0_RepeatMessageRequestBit_1E384015 0;
BA_ "GenSigTimeoutTime_TCM" SG_ 2654486549 CBV_bit0_RepeatMessageRequestBit_1E384015 0;
BA_ "GenSigTimeoutTime_AGSM" SG_ 2654486549 CBV_bit1_1E384015 0;
BA_ "GenSigTimeoutTime_ASBS" SG_ 2654486549 CBV_bit1_1E384015 0;
BA_ "GenSigTimeoutTime_BCM" SG_ 2654486549 CBV_bit1_1E384015 0;
BA_ "GenSigTimeoutTime_BSM" SG_ 2654486549 CBV_bit1_1E384015 0;
BA_ "GenSigTimeoutTime_CADM" SG_ 2654486549 CBV_bit1_1E384015 0;
BA_ "GenSigTimeoutTime_DMSM" SG_ 2654486549 CBV_bit1_1E384015 0;
BA_ "GenSigTimeoutTime_DTCM" SG_ 2654486549 CBV_bit1_1E384015 0;
BA_ "GenSigTimeoutTime_ECM" SG_ 2654486549 CBV_bit1_1E384015 0;
BA_ "GenSigTimeoutTime_ELSDM" SG_ 2654486549 CBV_bit1_1E384015 0;
BA_ "GenSigTimeoutTime_ESL" SG_ 2654486549 CBV_bit1_1E384015 0;
BA_ "GenSigTimeoutTime_GNMM" SG_ 2654486549 CBV_bit1_1E384015 0;
BA_ "GenSigTimeoutTime_HCP" SG_ 2654486549 CBV_bit1_1E384015 0;
BA_ "GenSigTimeoutTime_IPC" SG_ 2654486549 CBV_bit1_1E384015 0;
BA_ "GenSigTimeoutTime_RFHM" SG_ 2654486549 CBV_bit1_1E384015 0;
BA_ "GenSigTimeoutTime_SGW" SG_ 2654486549 CBV_bit1_1E384015 0;
BA_ "GenSigTimeoutTime_TCM" SG_ 2654486549 CBV_bit1_1E384015 0;
BA_ "GenSigTimeoutTime_AGSM" SG_ 2654486549 CBV_bit2_1E384015 0;
BA_ "GenSigTimeoutTime_ASBS" SG_ 2654486549 CBV_bit2_1E384015 0;
BA_ "GenSigTimeoutTime_BCM" SG_ 2654486549 CBV_bit2_1E384015 0;
BA_ "GenSigTimeoutTime_BSM" SG_ 2654486549 CBV_bit2_1E384015 0;
BA_ "GenSigTimeoutTime_CADM" SG_ 2654486549 CBV_bit2_1E384015 0;
BA_ "GenSigTimeoutTime_DMSM" SG_ 2654486549 CBV_bit2_1E384015 0;
BA_ "GenSigTimeoutTime_DTCM" SG_ 2654486549 CBV_bit2_1E384015 0;
BA_ "GenSigTimeoutTime_ECM" SG_ 2654486549 CBV_bit2_1E384015 0;
BA_ "GenSigTimeoutTime_ELSDM" SG_ 2654486549 CBV_bit2_1E384015 0;
BA_ "GenSigTimeoutTime_ESL" SG_ 2654486549 CBV_bit2_1E384015 0;
BA_ "GenSigTimeoutTime_GNMM" SG_ 2654486549 CBV_bit2_1E384015 0;
BA_ "GenSigTimeoutTime_HCP" SG_ 2654486549 CBV_bit2_1E384015 0;
BA_ "GenSigTimeoutTime_IPC" SG_ 2654486549 CBV_bit2_1E384015 0;
BA_ "GenSigTimeoutTime_RFHM" SG_ 2654486549 CBV_bit2_1E384015 0;
BA_ "GenSigTimeoutTime_SGW" SG_ 2654486549 CBV_bit2_1E384015 0;
BA_ "GenSigTimeoutTime_TCM" SG_ 2654486549 CBV_bit2_1E384015 0;
BA_ "GenSigTimeoutTime_AGSM" SG_ 2654486549 CBV_bit3_NMCoordinatorBit_1E384015 0;
BA_ "GenSigTimeoutTime_ASBS" SG_ 2654486549 CBV_bit3_NMCoordinatorBit_1E384015 0;
BA_ "GenSigTimeoutTime_BCM" SG_ 2654486549 CBV_bit3_NMCoordinatorBit_1E384015 0;
BA_ "GenSigTimeoutTime_BSM" SG_ 2654486549 CBV_bit3_NMCoordinatorBit_1E384015 0;
BA_ "GenSigTimeoutTime_CADM" SG_ 2654486549 CBV_bit3_NMCoordinatorBit_1E384015 0;
BA_ "GenSigTimeoutTime_DMSM" SG_ 2654486549 CBV_bit3_NMCoordinatorBit_1E384015 0;
BA_ "GenSigTimeoutTime_DTCM" SG_ 2654486549 CBV_bit3_NMCoordinatorBit_1E384015 0;
BA_ "GenSigTimeoutTime_ECM" SG_ 2654486549 CBV_bit3_NMCoordinatorBit_1E384015 0;
BA_ "GenSigTimeoutTime_ELSDM" SG_ 2654486549 CBV_bit3_NMCoordinatorBit_1E384015 0;
BA_ "GenSigTimeoutTime_ESL" SG_ 2654486549 CBV_bit3_NMCoordinatorBit_1E384015 0;
BA_ "GenSigTimeoutTime_GNMM" SG_ 2654486549 CBV_bit3_NMCoordinatorBit_1E384015 0;
BA_ "GenSigTimeoutTime_HCP" SG_ 2654486549 CBV_bit3_NMCoordinatorBit_1E384015 0;
BA_ "GenSigTimeoutTime_CADM" SG_ 2654486640 CBV_bit7_1E384070 0;
BA_ "GenSigTimeoutTime_DMSM" SG_ 2654486640 CBV_bit7_1E384070 0;
BA_ "GenSigTimeoutTime_DTCM" SG_ 2654486640 CBV_bit7_1E384070 0;
BA_ "GenSigTimeoutTime_ECM" SG_ 2654486640 CBV_bit7_1E384070 0;
BA_ "GenSigTimeoutTime_ELSDM" SG_ 2654486640 CBV_bit7_1E384070 0;
BA_ "GenSigTimeoutTime_ESL" SG_ 2654486640 CBV_bit7_1E384070 0;
BA_ "GenSigTimeoutTime_GNMM" SG_ 2654486640 CBV_bit7_1E384070 0;
BA_ "GenSigTimeoutTime_HCP" SG_ 2654486640 CBV_bit7_1E384070 0;
BA_ "GenSigTimeoutTime_IPC" SG_ 2654486640 CBV_bit7_1E384070 0;
BA_ "GenSigTimeoutTime_RFHM" SG_ 2654486640 CBV_bit7_1E384070 0;
BA_ "GenSigTimeoutTime_SGW" SG_ 2654486640 CBV_bit7_1E384070 0;
BA_ "GenSigTimeoutTime_TCM" SG_ 2654486640 CBV_bit7_1E384070 0;
BA_ "GenSigTimeoutTime_AGSM" SG_ 2654486640 SourceNodeIdentifier_1E384070 0;
BA_ "GenSigTimeoutTime_ASBS" SG_ 2654486640 SourceNodeIdentifier_1E384070 0;
BA_ "GenSigTimeoutTime_BCM" SG_ 2654486640 SourceNodeIdentifier_1E384070 0;
BA_ "GenSigTimeoutTime_BSM" SG_ 2654486640 SourceNodeIdentifier_1E384070 0;
BA_ "GenSigTimeoutTime_CADM" SG_ 2654486640 SourceNodeIdentifier_1E384070 0;
BA_ "GenSigTimeoutTime_DMSM" SG_ 2654486640 SourceNodeIdentifier_1E384070 0;
BA_ "GenSigTimeoutTime_DTCM" SG_ 2654486640 SourceNodeIdentifier_1E384070 0;
BA_ "GenSigTimeoutTime_ECM" SG_ 2654486640 SourceNodeIdentifier_1E384070 0;
BA_ "GenSigTimeoutTime_ELSDM" SG_ 2654486640 SourceNodeIdentifier_1E384070 0;
BA_ "GenSigTimeoutTime_ESL" SG_ 2654486640 SourceNodeIdentifier_1E384070 0;
BA_ "GenSigTimeoutTime_GNMM" SG_ 2654486640 SourceNodeIdentifier_1E384070 0;
BA_ "GenSigTimeoutTime_HCP" SG_ 2654486640 SourceNodeIdentifier_1E384070 0;
BA_ "GenSigTimeoutTime_IPC" SG_ 2654486640 SourceNodeIdentifier_1E384070 0;
BA_ "GenSigTimeoutTime_RFHM" SG_ 2654486640 SourceNodeIdentifier_1E384070 0;
BA_ "GenSigTimeoutTime_SGW" SG_ 2654486640 SourceNodeIdentifier_1E384070 0;
BA_ "GenSigTimeoutTime_TCM" SG_ 2654486640 SourceNodeIdentifier_1E384070 0;
BA_ "GenSigTimeoutTime_ESL" SG_ 2654486595 CBV_bit4_ActiveWakeupBit_1E384043 0;
BA_ "GenSigTimeoutTime_GNMM" SG_ 2654486595 CBV_bit4_ActiveWakeupBit_1E384043 0;
BA_ "GenSigTimeoutTime_HCP" SG_ 2654486595 CBV_bit4_ActiveWakeupBit_1E384043 0;
BA_ "GenSigTimeoutTime_IPC" SG_ 2654486595 CBV_bit4_ActiveWakeupBit_1E384043 0;
BA_ "GenSigTimeoutTime_RFHM" SG_ 2654486595 CBV_bit4_ActiveWakeupBit_1E384043 0;
BA_ "GenSigTimeoutTime_SGW" SG_ 2654486595 CBV_bit4_ActiveWakeupBit_1E384043 0;
BA_ "GenSigTimeoutTime_TCM" SG_ 2654486595 CBV_bit4_ActiveWakeupBit_1E384043 0;
BA_ "GenSigTimeoutTime_AGSM" SG_ 2654486595 CBV_bit5_1E384043 0;
BA_ "GenSigTimeoutTime_ASBS" SG_ 2654486595 CBV_bit5_1E384043 0;
BA_ "GenSigTimeoutTime_BCM" SG_ 2654486595 CBV_bit5_1E384043 0;
BA_ "GenSigTimeoutTime_BSM" SG_ 2654486595 CBV_bit5_1E384043 0;
BA_ "GenSigTimeoutTime_CADM" SG_ 2654486595 CBV_bit5_1E384043 0;
BA_ "GenSigTimeoutTime_DMSM" SG_ 2654486595 CBV_bit5_1E384043 0;
BA_ "GenSigTimeoutTime_DTCM" SG_ 2654486595 CBV_bit5_1E384043 0;
BA_ "GenSigTimeoutTime_ECM" SG_ 2654486595 CBV_bit5_1E384043 0;
BA_ "GenSigTimeoutTime_ELSDM" SG_ 2654486595 CBV_bit5_1E384043 0;
BA_ "GenSigTimeoutTime_ESL" SG_ 2654486595 CBV_bit5_1E384043 0;
BA_ "GenSigTimeoutTime_GNMM" SG_ 2654486595 CBV_bit5_1E384043 0;
BA_ "GenSigTimeoutTime_HCP" SG_ 2654486595 CBV_bit5_1E384043 0;
BA_ "GenSigTimeoutTime_IPC" SG_ 2654486595 CBV_bit5_1E384043 0;
BA_ "GenSigTimeoutTime_RFHM" SG_ 2654486595 CBV_bit5_1E384043 0;
BA_ "GenSigTimeoutTime_SGW" SG_ 2654486595 CBV_bit5_1E384043 0;
BA_ "GenSigTimeoutTime_TCM" SG_ 2654486595 CBV_bit5_1E384043 0;
BA_ "GenSigTimeoutTime_AGSM" SG_ 2654486595 CBV_bit6_PartialNtwInfBit_1E384043 0;
BA_ "GenSigTimeoutTime_ASBS" SG_ 2654486595 CBV_bit6_PartialNtwInfBit_1E384043 0;
BA_ "GenSigTimeoutTime_BCM" SG_ 2654486595 CBV_bit6_PartialNtwInfBit_1E384043 0;
BA_ "GenSigTimeoutTime_BSM" SG_ 2654486595 CBV_bit6_PartialNtwInfBit_1E384043 0;
BA_ "GenSigTimeoutTime_CADM" SG_ 2654486595 CBV_bit6_PartialNtwInfBit_1E384043 0;
BA_ "GenSigTimeoutTime_DMSM" SG_ 2654486595 CBV_bit6_PartialNtwInfBit_1E384043 0;
BA_ "GenSigTimeoutTime_DTCM" SG_ 2654486595 CBV_bit6_PartialNtwInfBit_1E384043 0;
BA_ "GenSigTimeoutTime_ECM" SG_ 2654486595 CBV_bit6_PartialNtwInfBit_1E384043 0;
BA_ "GenSigTimeoutTime_ELSDM" SG_ 2654486595 CBV_bit6_PartialNtwInfBit_1E384043 0;
BA_ "GenSigTimeoutTime_ESL" SG_ 2654486595 CBV_bit6_PartialNtwInfBit_1E384043 0;
BA_ "GenSigTimeoutTime_GNMM" SG_ 2654486595 CBV_bit6_PartialNtwInfBit_1E384043 0;
BA_ "GenSigTimeoutTime_HCP" SG_ 2654486595 CBV_bit6_PartialNtwInfBit_1E384043 0;
BA_ "GenSigTimeoutTime_IPC" SG_ 2654486595 CBV_bit6_PartialNtwInfBit_1E384043 0;
BA_ "GenSigTimeoutTime_RFHM" SG_ 2654486595 CBV_bit6_PartialNtwInfBit_1E384043 0;
BA_ "GenSigTimeoutTime_SGW" SG_ 2654486595 CBV_bit6_PartialNtwInfBit_1E384043 0;
BA_ "GenSigTimeoutTime_TCM" SG_ 2654486595 CBV_bit6_PartialNtwInfBit_1E384043 0;
BA_ "GenSigTimeoutTime_AGSM" SG_ 2654486595 CBV_bit7_1E384043 0;
BA_ "GenSigTimeoutTime_ASBS" SG_ 2654486595 CBV_bit7_1E384043 0;
BA_ "GenSigTimeoutTime_BCM" SG_ 2654486595 CBV_bit7_1E384043 0;
BA_ "GenSigTimeoutTime_BSM" SG_ 2654486595 CBV_bit7_1E384043 0;
BA_ "GenSigTimeoutTime_CADM" SG_ 2654486595 CBV_bit7_1E384043 0;
BA_ "GenSigTimeoutTime_DMSM" SG_ 2654486595 CBV_bit7_1E384043 0;
BA_ "GenSigTimeoutTime_DTCM" SG_ 2654486595 CBV_bit7_1E384043 0;
BA_ "GenSigTimeoutTime_ECM" SG_ 2654486595 CBV_bit7_1E384043 0;
BA_ "GenSigTimeoutTime_ELSDM" SG_ 2654486595 CBV_bit7_1E384043 0;
BA_ "GenSigTimeoutTime_ESL" SG_ 2654486595 CBV_bit7_1E384043 0;
BA_ "GenSigTimeoutTime_GNMM" SG_ 2654486595 CBV_bit7_1E384043 0;
BA_ "GenSigTimeoutTime_HCP" SG_ 2654486595 CBV_bit7_1E384043 0;
BA_ "GenSigTimeoutTime_IPC" SG_ 2654486595 CBV_bit7_1E384043 0;
BA_ "GenSigTimeoutTime_RFHM" SG_ 2654486595 CBV_bit7_1E384043 0;
BA_ "GenSigTimeoutTime_SGW" SG_ 2654486595 CBV_bit7_1E384043 0;
BA_ "GenSigTimeoutTime_TCM" SG_ 2654486595 CBV_bit7_1E384043 0;
BA_ "GenSigTimeoutTime_AGSM" SG_ 2654486595 SourceNodeIdentifier_1E384043 0;
BA_ "GenSigTimeoutTime_ASBS" SG_ 2654486595 SourceNodeIdentifier_1E384043 0;
BA_ "GenSigTimeoutTime_BCM" SG_ 2654486595 SourceNodeIdentifier_1E384043 0;
BA_ "GenSigTimeoutTime_BSM" SG_ 2654486595 SourceNodeIdentifier_1E384043 0;
BA_ "GenSigTimeoutTime_CADM" SG_ 2654486595 SourceNodeIdentifier_1E384043 0;
BA_ "GenSigTimeoutTime_DMSM" SG_ 2654486595 SourceNodeIdentifier_1E384043 0;
BA_ "GenSigTimeoutTime_DTCM" SG_ 2654486595 SourceNodeIdentifier_1E384043 0;
BA_ "GenSigTimeoutTime_ECM" SG_ 2654486595 SourceNodeIdentifier_1E384043 0;
BA_ "GenSigTimeoutTime_ELSDM" SG_ 2654486595 SourceNodeIdentifier_1E384043 0;
BA_ "GenSigTimeoutTime_ESL" SG_ 2654486595 SourceNodeIdentifier_1E384043 0;
BA_ "GenSigTimeoutTime_GNMM" SG_ 2654486595 SourceNodeIdentifier_1E384043 0;
BA_ "GenSigTimeoutTime_HCP" SG_ 2654486595 SourceNodeIdentifier_1E384043 0;
BA_ "GenSigTimeoutTime_IPC" SG_ 2654486595 SourceNodeIdentifier_1E384043 0;
BA_ "GenSigTimeoutTime_RFHM" SG_ 2654486595 SourceNodeIdentifier_1E384043 0;
BA_ "GenSigTimeoutTime_SGW" SG_ 2654486595 SourceNodeIdentifier_1E384043 0;
BA_ "GenSigTimeoutTime_TCM" SG_ 2654486595 SourceNodeIdentifier_1E384043 0;
BA_ "GenSigTimeoutTime_AGSM" SG_ 2654486633 CBV_bit0_RepeatMessageRequestBit_1E384069 0;
BA_ "GenSigTimeoutTime_ASBS" SG_ 2654486633 CBV_bit0_RepeatMessageRequestBit_1E384069 0;
BA_ "GenSigTimeoutTime_BCM" SG_ 2654486633 CBV_bit0_RepeatMessageRequestBit_1E384069 0;
BA_ "GenSigTimeoutTime_BSM" SG_ 2654486633 CBV_bit0_RepeatMessageRequestBit_1E384069 0;
BA_ "GenSigTimeoutTime_CADM" SG_ 2654486633 CBV_bit0_RepeatMessageRequestBit_1E384069 0;
BA_ "GenSigTimeoutTime_DMSM" SG_ 2654486633 CBV_bit0_RepeatMessageRequestBit_1E384069 0;
BA_ "GenSigTimeoutTime_DTCM" SG_ 2654486633 CBV_bit0_RepeatMessageRequestBit_1E384069 0;
BA_ "GenSigTimeoutTime_ECM" SG_ 2654486633 CBV_bit0_RepeatMessageRequestBit_1E384069 0;
BA_ "GenSigTimeoutTime_ELSDM" SG_ 2654486633 CBV_bit0_RepeatMessageRequestBit_1E384069 0;
BA_ "GenSigTimeoutTime_ESL" SG_ 2654486633 CBV_bit0_RepeatMessageRequestBit_1E384069 0;
BA_ "GenSigTimeoutTime_GNMM" SG_ 2654486633 CBV_bit0_RepeatMessageRequestBit_1E384069 0;
BA_ "GenSigTimeoutTime_HCP" SG_ 2654486633 CBV_bit0_RepeatMessageRequestBit_1E384069 0;
BA_ "GenSigTimeoutTime_IPC" SG_ 2654486633 CBV_bit0_RepeatMessageRequestBit_1E384069 0;
BA_ "GenSigTimeoutTime_RFHM" SG_ 2654486633 CBV_bit0_RepeatMessageRequestBit_1E384069 0;
BA_ "GenSigTimeoutTime_SGW" SG_ 2654486633 CBV_bit0_RepeatMessageRequestBit_1E384069 0;
BA_ "GenSigTimeoutTime_TCM" SG_ 2654486633 CBV_bit0_RepeatMessageRequestBit_1E384069 0;
BA_ "GenSigTimeoutTime_AGSM" SG_ 2654486633 CBV_bit1_1E384069 0;
BA_ "GenSigTimeoutTime_ASBS" SG_ 2654486633 CBV_bit1_1E384069 0;
BA_ "GenSigTimeoutTime_BCM" SG_ 2654486633 CBV_bit1_1E384069 0;
BA_ "GenSigTimeoutTime_BSM" SG_ 2654486633 CBV_bit1_1E384069 0;
BA_ "GenSigTimeoutTime_CADM" SG_ 2654486633 CBV_bit1_1E384069 0;
BA_ "GenSigTimeoutTime_DMSM" SG_ 2654486633 CBV_bit1_1E384069 0;
BA_ "GenSigTimeoutTime_DTCM" SG_ 2654486633 CBV_bit1_1E384069 0;
BA_ "GenSigTimeoutTime_ECM" SG_ 2654486633 CBV_bit1_1E384069 0;
BA_ "GenSigTimeoutTime_ELSDM" SG_ 2654486633 CBV_bit1_1E384069 0;
BA_ "GenSigTimeoutTime_ESL" SG_ 2654486633 CBV_bit1_1E384069 0;
BA_ "GenSigTimeoutTime_GNMM" SG_ 2654486633 CBV_bit1_1E384069 0;
BA_ "GenSigTimeoutTime_HCP" SG_ 2654486633 CBV_bit1_1E384069 0;
BA_ "GenSigTimeoutTime_IPC" SG_ 2654486633 CBV_bit1_1E384069 0;
BA_ "GenSigTimeoutTime_RFHM" SG_ 2654486633 CBV_bit1_1E384069 0;
BA_ "GenSigTimeoutTime_SGW" SG_ 2654486633 CBV_bit1_1E384069 0;
BA_ "GenSigTimeoutTime_TCM" SG_ 2654486633 CBV_bit1_1E384069 0;
BA_ "GenSigTimeoutTime_TCM" SG_ 2654486531 CBV_bit4_ActiveWakeupBit_1E384003 0;
BA_ "GenSigTimeoutTime_AGSM" SG_ 2654486531 CBV_bit5_1E384003 0;
BA_ "GenSigTimeoutTime_ASBS" SG_ 2654486531 CBV_bit5_1E384003 0;
BA_ "GenSigTimeoutTime_BCM" SG_ 2654486531 CBV_bit5_1E384003 0;
BA_ "GenSigTimeoutTime_BSM" SG_ 2654486531 CBV_bit5_1E384003 0;
BA_ "GenSigTimeoutTime_CADM" SG_ 2654486531 CBV_bit5_1E384003 0;
BA_ "GenSigTimeoutTime_DMSM" SG_ 2654486531 CBV_bit5_1E384003 0;
BA_ "GenSigTimeoutTime_DTCM" SG_ 2654486531 CBV_bit5_1E384003 0;
BA_ "GenSigTimeoutTime_ECM" SG_ 2654486531 CBV_bit5_1E384003 0;
BA_ "GenSigTimeoutTime_ELSDM" SG_ 2654486531 CBV_bit5_1E384003 0;
BA_ "GenSigTimeoutTime_ESL" SG_ 2654486531 CBV_bit5_1E384003 0;
BA_ "GenSigTimeoutTime_GNMM" SG_ 2654486531 CBV_bit5_1E384003 0;
BA_ "GenSigTimeoutTime_HCP" SG_ 2654486531 CBV_bit5_1E384003 0;
BA_ "GenSigTimeoutTime_IPC" SG_ 2654486531 CBV_bit5_1E384003 0;
BA_ "GenSigTimeoutTime_RFHM" SG_ 2654486531 CBV_bit5_1E384003 0;
BA_ "GenSigTimeoutTime_SGW" SG_ 2654486531 CBV_bit5_1E384003 0;
BA_ "GenSigTimeoutTime_TCM" SG_ 2654486531 CBV_bit5_1E384003 0;
BA_ "GenSigTimeoutTime_AGSM" SG_ 2654486531 CBV_bit6_PartialNtwInfBit_1E384003 0;
BA_ "GenSigTimeoutTime_ASBS" SG_ 2654486531 CBV_bit6_PartialNtwInfBit_1E384003 0;
BA_ "GenSigTimeoutTime_BCM" SG_ 2654486531 CBV_bit6_PartialNtwInfBit_1E384003 0;
BA_ "GenSigTimeoutTime_BSM" SG_ 2654486531 CBV_bit6_PartialNtwInfBit_1E384003 0;
BA_ "GenSigTimeoutTime_CADM" SG_ 2654486531 CBV_bit6_PartialNtwInfBit_1E384003 0;
BA_ "GenSigTimeoutTime_DMSM" SG_ 2654486531 CBV_bit6_PartialNtwInfBit_1E384003 0;
BA_ "GenSigTimeoutTime_DTCM" SG_ 2654486531 CBV_bit6_PartialNtwInfBit_1E384003 0;
BA_ "GenSigTimeoutTime_ECM" SG_ 2654486531 CBV_bit6_PartialNtwInfBit_1E384003 0;
BA_ "GenSigTimeoutTime_ELSDM" SG_ 2654486531 CBV_bit6_PartialNtwInfBit_1E384003 0;
BA_ "GenSigTimeoutTime_ESL" SG_ 2654486531 CBV_bit6_PartialNtwInfBit_1E384003 0;
BA_ "GenSigTimeoutTime_GNMM" SG_ 2654486531 CBV_bit6_PartialNtwInfBit_1E384003 0;
BA_ "GenSigTimeoutTime_HCP" SG_ 2654486531 CBV_bit6_PartialNtwInfBit_1E384003 0;
BA_ "GenSigTimeoutTime_IPC" SG_ 2654486531 CBV_bit6_PartialNtwInfBit_1E384003 0;
BA_ "GenSigTimeoutTime_RFHM" SG_ 2654486531 CBV_bit6_PartialNtwInfBit_1E384003 0;
BA_ "GenSigTimeoutTime_SGW" SG_ 2654486531 CBV_bit6_PartialNtwInfBit_1E384003 0;
BA_ "GenSigTimeoutTime_TCM" SG_ 2654486531 CBV_bit6_PartialNtwInfBit_1E384003 0;
BA_ "GenSigTimeoutTime_AGSM" SG_ 2654486531 CBV_bit7_1E384003 0;
BA_ "GenSigTimeoutTime_ASBS" SG_ 2654486531 CBV_bit7_1E384003 0;
BA_ "GenSigTimeoutTime_BCM" SG_ 2654486531 CBV_bit7_1E384003 0;
BA_ "GenSigTimeoutTime_BSM" SG_ 2654486531 CBV_bit7_1E384003 0;
BA_ "GenSigTimeoutTime_CADM" SG_ 2654486531 CBV_bit7_1E384003 0;
BA_ "GenSigTimeoutTime_DMSM" SG_ 2654486531 CBV_bit7_1E384003 0;
BA_ "GenSigTimeoutTime_DTCM" SG_ 2654486531 CBV_bit7_1E384003 0;
BA_ "GenSigTimeoutTime_ECM" SG_ 2654486531 CBV_bit7_1E384003 0;
BA_ "GenSigTimeoutTime_ELSDM" SG_ 2654486531 CBV_bit7_1E384003 0;
BA_ "GenSigTimeoutTime_ESL" SG_ 2654486531 CBV_bit7_1E384003 0;
BA_ "GenSigTimeoutTime_GNMM" SG_ 2654486531 CBV_bit7_1E384003 0;
BA_ "GenSigTimeoutTime_HCP" SG_ 2654486531 CBV_bit7_1E384003 0;
BA_ "GenSigTimeoutTime_IPC" SG_ 2654486531 CBV_bit7_1E384003 0;
BA_ "GenSigTimeoutTime_RFHM" SG_ 2654486531 CBV_bit7_1E384003 0;
BA_ "GenSigTimeoutTime_SGW" SG_ 2654486531 CBV_bit7_1E384003 0;
BA_ "GenSigTimeoutTime_TCM" SG_ 2654486531 CBV_bit7_1E384003 0;
BA_ "GenSigTimeoutTime_AGSM" SG_ 2654486531 SourceNodeIdentifier_1E384003 0;
BA_ "GenSigTimeoutTime_ASBS" SG_ 2654486531 SourceNodeIdentifier_1E384003 0;
BA_ "GenSigTimeoutTime_BCM" SG_ 2654486531 SourceNodeIdentifier_1E384003 0;
BA_ "GenSigTimeoutTime_BSM" SG_ 2654486531 SourceNodeIdentifier_1E384003 0;
BA_ "GenSigTimeoutTime_CADM" SG_ 2654486531 SourceNodeIdentifier_1E384003 0;
BA_ "GenSigTimeoutTime_DMSM" SG_ 2654486531 SourceNodeIdentifier_1E384003 0;
BA_ "GenSigTimeoutTime_DTCM" SG_ 2654486531 SourceNodeIdentifier_1E384003 0;
BA_ "GenSigTimeoutTime_ECM" SG_ 2654486531 SourceNodeIdentifier_1E384003 0;
BA_ "GenSigTimeoutTime_ELSDM" SG_ 2654486531 SourceNodeIdentifier_1E384003 0;
BA_ "GenSigTimeoutTime_ESL" SG_ 2654486531 SourceNodeIdentifier_1E384003 0;
BA_ "GenSigTimeoutTime_GNMM" SG_ 2654486531 SourceNodeIdentifier_1E384003 0;
BA_ "GenSigTimeoutTime_HCP" SG_ 2654486531 SourceNodeIdentifier_1E384003 0;
BA_ "GenSigTimeoutTime_IPC" SG_ 2654486531 SourceNodeIdentifier_1E384003 0;
BA_ "GenSigTimeoutTime_RFHM" SG_ 2654486531 SourceNodeIdentifier_1E384003 0;
BA_ "GenSigTimeoutTime_SGW" SG_ 2654486531 SourceNodeIdentifier_1E384003 0;
BA_ "GenSigTimeoutTime_TCM" SG_ 2654486531 SourceNodeIdentifier_1E384003 0;
BA_ "GenSigTimeoutTime_ADCAM" SG_ 2654486593 CBV_bit0_RepeatMessageRequestBit_1E384041 0;
BA_ "GenSigTimeoutTime_EVCU2" SG_ 2654486593 CBV_bit0_RepeatMessageRequestBit_1E384041 0;
BA_ "GenSigTimeoutTime_VDCM" SG_ 2654486593 CBV_bit0_RepeatMessageRequestBit_1E384041 0;
BA_ "GenSigTimeoutTime_ADCAM" SG_ 2654486593 CBV_bit1_1E384041 0;
BA_ "GenSigTimeoutTime_AGSM" SG_ 2654486640 CBV_bit0_RepeatMessageRequestBit_1E384070 0;
BA_ "GenSigTimeoutTime_ASBS" SG_ 2654486640 CBV_bit0_RepeatMessageRequestBit_1E384070 0;
BA_ "GenSigTimeoutTime_BCM" SG_ 2654486640 CBV_bit0_RepeatMessageRequestBit_1E384070 0;
BA_ "GenSigTimeoutTime_BSM" SG_ 2654486640 CBV_bit0_RepeatMessageRequestBit_1E384070 0;
BA_ "GenSigTimeoutTime_CADM" SG_ 2654486640 CBV_bit0_RepeatMessageRequestBit_1E384070 0;
BA_ "GenSigTimeoutTime_DMSM" SG_ 2654486640 CBV_bit0_RepeatMessageRequestBit_1E384070 0;
BA_ "GenSigTimeoutTime_DTCM" SG_ 2654486640 CBV_bit0_RepeatMessageRequestBit_1E384070 0;
BA_ "GenSigTimeoutTime_ECM" SG_ 2654486640 CBV_bit0_RepeatMessageRequestBit_1E384070 0;
BA_ "GenSigTimeoutTime_ELSDM" SG_ 2654486640 CBV_bit0_RepeatMessageRequestBit_1E384070 0;
BA_ "GenSigTimeoutTime_ESL" SG_ 2654486640 CBV_bit0_RepeatMessageRequestBit_1E384070 0;
BA_ "GenSigTimeoutTime_GNMM" SG_ 2654486640 CBV_bit0_RepeatMessageRequestBit_1E384070 0;
BA_ "GenSigTimeoutTime_HCP" SG_ 2654486640 CBV_bit0_RepeatMessageRequestBit_1E384070 0;
BA_ "GenSigTimeoutTime_IPC" SG_ 2654486640 CBV_bit0_RepeatMessageRequestBit_1E384070 0;
BA_ "GenSigTimeoutTime_RFHM" SG_ 2654486640 CBV_bit0_RepeatMessageRequestBit_1E384070 0;
BA_ "GenSigTimeoutTime_SGW" SG_ 2654486640 CBV_bit0_RepeatMessageRequestBit_1E384070 0;
BA_ "GenSigTimeoutTime_TCM" SG_ 2654486640 CBV_bit0_RepeatMessageRequestBit_1E384070 0;
BA_ "GenSigTimeoutTime_AGSM" SG_ 2654486640 CBV_bit1_1E384070 0;
BA_ "GenSigTimeoutTime_ASBS" SG_ 2654486640 CBV_bit1_1E384070 0;
BA_ "GenSigTimeoutTime_BCM" SG_ 2654486640 CBV_bit1_1E384070 0;
BA_ "GenSigTimeoutTime_BSM" SG_ 2654486640 CBV_bit1_1E384070 0;
BA_ "GenSigTimeoutTime_CADM" SG_ 2654486640 CBV_bit1_1E384070 0;
BA_ "GenSigTimeoutTime_DMSM" SG_ 2654486640 CBV_bit1_1E384070 0;
BA_ "GenSigTimeoutTime_DTCM" SG_ 2654486640 CBV_bit1_1E384070 0;
BA_ "GenSigTimeoutTime_ECM" SG_ 2654486640 CBV_bit1_1E384070 0;
BA_ "GenSigTimeoutTime_ELSDM" SG_ 2654486640 CBV_bit1_1E384070 0;
BA_ "GenSigTimeoutTime_ESL" SG_ 2654486640 CBV_bit1_1E384070 0;
BA_ "GenSigTimeoutTime_GNMM" SG_ 2654486640 CBV_bit1_1E384070 0;
BA_ "GenSigTimeoutTime_HCP" SG_ 2654486640 CBV_bit1_1E384070 0;
BA_ "GenSigTimeoutTime_IPC" SG_ 2654486640 CBV_bit1_1E384070 0;
BA_ "GenSigTimeoutTime_RFHM" SG_ 2654486640 CBV_bit1_1E384070 0;
BA_ "GenSigTimeoutTime_SGW" SG_ 2654486640 CBV_bit1_1E384070 0;
BA_ "GenSigTimeoutTime_TCM" SG_ 2654486640 CBV_bit1_1E384070 0;
BA_ "GenSigTimeoutTime_AGSM" SG_ 2654486640 CBV_bit2_1E384070 0;
BA_ "GenSigTimeoutTime_ASBS" SG_ 2654486640 CBV_bit2_1E384070 0;
BA_ "GenSigTimeoutTime_BCM" SG_ 2654486640 CBV_bit2_1E384070 0;
BA_ "GenSigTimeoutTime_BSM" SG_ 2654486640 CBV_bit2_1E384070 0;
BA_ "GenSigTimeoutTime_CADM" SG_ 2654486640 CBV_bit2_1E384070 0;
BA_ "GenSigTimeoutTime_DMSM" SG_ 2654486640 CBV_bit2_1E384070 0;
BA_ "GenSigTimeoutTime_DTCM" SG_ 2654486640 CBV_bit2_1E384070 0;
BA_ "GenSigTimeoutTime_ECM" SG_ 2654486640 CBV_bit2_1E384070 0;
BA_ "GenSigTimeoutTime_ELSDM" SG_ 2654486640 CBV_bit2_1E384070 0;
BA_ "GenSigTimeoutTime_ESL" SG_ 2654486640 CBV_bit2_1E384070 0;
BA_ "GenSigTimeoutTime_GNMM" SG_ 2654486640 CBV_bit2_1E384070 0;
BA_ "GenSigTimeoutTime_HCP" SG_ 2654486640 CBV_bit2_1E384070 0;
BA_ "GenSigTimeoutTime_IPC" SG_ 2654486640 CBV_bit2_1E384070 0;
BA_ "GenSigTimeoutTime_RFHM" SG_ 2654486640 CBV_bit2_1E384070 0;
BA_ "GenSigTimeoutTime_SGW" SG_ 2654486640 CBV_bit2_1E384070 0;
BA_ "GenSigTimeoutTime_TCM" SG_ 2654486640 CBV_bit2_1E384070 0;
BA_ "GenSigTimeoutTime_AGSM" SG_ 2654486640 CBV_bit3_NMCoordinatorBit_1E384070 0;
BA_ "GenSigTimeoutTime_ASBS" SG_ 2654486640 CBV_bit3_NMCoordinatorBit_1E384070 0;
BA_ "GenSigTimeoutTime_BCM" SG_ 2654486640 CBV_bit3_NMCoordinatorBit_1E384070 0;
BA_ "GenSigTimeoutTime_BSM" SG_ 2654486640 CBV_bit3_NMCoordinatorBit_1E384070 0;
BA_ "GenSigTimeoutTime_CADM" SG_ 2654486640 CBV_bit3_NMCoordinatorBit_1E384070 0;
BA_ "GenSigTimeoutTime_DMSM" SG_ 2654486640 CBV_bit3_NMCoordinatorBit_1E384070 0;
BA_ "GenSigTimeoutTime_DTCM" SG_ 2654486640 CBV_bit3_NMCoordinatorBit_1E384070 0;
BA_ "GenSigTimeoutTime_ECM" SG_ 2654486640 CBV_bit3_NMCoordinatorBit_1E384070 0;
BA_ "GenSigTimeoutTime_ELSDM" SG_ 2654486640 CBV_bit3_NMCoordinatorBit_1E384070 0;
BA_ "GenSigTimeoutTime_ESL" SG_ 2654486640 CBV_bit3_NMCoordinatorBit_1E384070 0;
BA_ "GenSigTimeoutTime_GNMM" SG_ 2654486640 CBV_bit3_NMCoordinatorBit_1E384070 0;
BA_ "GenSigTimeoutTime_HCP" SG_ 2654486640 CBV_bit3_NMCoordinatorBit_1E384070 0;
BA_ "GenSigTimeoutTime_IPC" SG_ 2654486640 CBV_bit3_NMCoordinatorBit_1E384070 0;
BA_ "GenSigTimeoutTime_RFHM" SG_ 2654486640 CBV_bit3_NMCoordinatorBit_1E384070 0;
BA_ "GenSigTimeoutTime_SGW" SG_ 2654486640 CBV_bit3_NMCoordinatorBit_1E384070 0;
BA_ "GenSigTimeoutTime_TCM" SG_ 2654486640 CBV_bit3_NMCoordinatorBit_1E384070 0;
BA_ "GenSigTimeoutTime_AGSM" SG_ 2654486640 CBV_bit4_ActiveWakeupBit_1E384070 0;
BA_ "GenSigTimeoutTime_ASBS" SG_ 2654486640 CBV_bit4_ActiveWakeupBit_1E384070 0;
BA_ "GenSigTimeoutTime_BCM" SG_ 2654486640 CBV_bit4_ActiveWakeupBit_1E384070 0;
BA_ "GenSigTimeoutTime_BSM" SG_ 2654486640 CBV_bit4_ActiveWakeupBit_1E384070 0;
BA_ "GenSigTimeoutTime_CADM" SG_ 2654486640 CBV_bit4_ActiveWakeupBit_1E384070 0;
BA_ "GenSigTimeoutTime_DMSM" SG_ 2654486640 CBV_bit4_ActiveWakeupBit_1E384070 0;
BA_ "GenSigTimeoutTime_DTCM" SG_ 2654486640 CBV_bit4_ActiveWakeupBit_1E384070 0;
BA_ "GenSigTimeoutTime_ECM" SG_ 2654486640 CBV_bit4_ActiveWakeupBit_1E384070 0;
BA_ "GenSigTimeoutTime_ELSDM" SG_ 2654486640 CBV_bit4_ActiveWakeupBit_1E384070 0;
BA_ "GenSigTimeoutTime_ESL" SG_ 2654486640 CBV_bit4_ActiveWakeupBit_1E384070 0;
BA_ "GenSigTimeoutTime_GNMM" SG_ 2654486640 CBV_bit4_ActiveWakeupBit_1E384070 0;
BA_ "GenSigTimeoutTime_HCP" SG_ 2654486640 CBV_bit4_ActiveWakeupBit_1E384070 0;
BA_ "GenSigTimeoutTime_IPC" SG_ 2654486640 CBV_bit4_ActiveWakeupBit_1E384070 0;
BA_ "GenSigTimeoutTime_RFHM" SG_ 2654486640 CBV_bit4_ActiveWakeupBit_1E384070 0;
BA_ "GenSigTimeoutTime_SGW" SG_ 2654486640 CBV_bit4_ActiveWakeupBit_1E384070 0;
BA_ "GenSigTimeoutTime_TCM" SG_ 2654486640 CBV_bit4_ActiveWakeupBit_1E384070 0;
BA_ "GenSigTimeoutTime_ADCAM" SG_ 2654486539 CBV_bit0_RepeatMessageRequestBit_1E38400B 0;
BA_ "GenSigTimeoutTime_EVCU2" SG_ 2654486539 CBV_bit0_RepeatMessageRequestBit_1E38400B 0;
BA_ "GenSigTimeoutTime_VDCM" SG_ 2654486539 CBV_bit0_RepeatMessageRequestBit_1E38400B 0;
BA_ "GenSigTimeoutTime_ADCAM" SG_ 2654486539 CBV_bit1_1E38400B 0;
BA_ "GenSigTimeoutTime_EVCU2" SG_ 2654486539 CBV_bit1_1E38400B 0;
BA_ "GenSigTimeoutTime_VDCM" SG_ 2654486539 CBV_bit1_1E38400B 0;
BA_ "GenSigTimeoutTime_ADCAM" SG_ 2654486539 CBV_bit2_1E38400B 0;
BA_ "GenSigTimeoutTime_EVCU2" SG_ 2654486539 CBV_bit2_1E38400B 0;
BA_ "GenSigTimeoutTime_VDCM" SG_ 2654486539 CBV_bit2_1E38400B 0;
BA_ "GenSigTimeoutTime_ADCAM" SG_ 2654486539 CBV_bit3_NMCoordinatorBit_1E38400B 0;
BA_ "GenSigTimeoutTime_EVCU2" SG_ 2654486539 CBV_bit3_NMCoordinatorBit_1E38400B 0;
BA_ "GenSigTimeoutTime_VDCM" SG_ 2654486539 CBV_bit3_NMCoordinatorBit_1E38400B 0;
BA_ "GenSigTimeoutTime_ADCAM" SG_ 2654486539 CBV_bit4_ActiveWakeupBit_1E38400B 0;
BA_ "GenSigTimeoutTime_EVCU2" SG_ 2654486539 CBV_bit4_ActiveWakeupBit_1E38400B 0;
BA_ "GenSigTimeoutTime_VDCM" SG_ 2654486539 CBV_bit4_ActiveWakeupBit_1E38400B 0;
BA_ "GenSigTimeoutTime_ADCAM" SG_ 2654486539 CBV_bit5_1E38400B 0;
BA_ "GenSigTimeoutTime_EVCU2" SG_ 2654486539 CBV_bit5_1E38400B 0;
BA_ "GenSigTimeoutTime_VDCM" SG_ 2654486539 CBV_bit5_1E38400B 0;
BA_ "GenSigTimeoutTime_ADCAM" SG_ 2654486539 CBV_bit6_PartialNtwInfBit_1E38400B 0;
BA_ "GenSigTimeoutTime_EVCU2" SG_ 2654486539 CBV_bit6_PartialNtwInfBit_1E38400B 0;
BA_ "GenSigTimeoutTime_VDCM" SG_ 2654486539 CBV_bit6_PartialNtwInfBit_1E38400B 0;
BA_ "GenSigTimeoutTime_ADCAM" SG_ 2654486539 CBV_bit7_1E38400B 0;
BA_ "GenSigTimeoutTime_EVCU2" SG_ 2654486539 CBV_bit7_1E38400B 0;
BA_ "GenSigTimeoutTime_VDCM" SG_ 2654486539 CBV_bit7_1E38400B 0;
BA_ "GenSigTimeoutTime_ADCAM" SG_ 2654486539 SourceNodeIdentifier_1E38400B 0;
BA_ "GenSigTimeoutTime_EVCU2" SG_ 2654486539 SourceNodeIdentifier_1E38400B 0;
BA_ "GenSigTimeoutTime_VDCM" SG_ 2654486539 SourceNodeIdentifier_1E38400B 0;
BA_ "GenSigTimeoutTime_AGSM" SG_ 2654486539 CBV_bit0_RepeatMessageRequestBit_1E38400B 0;
BA_ "GenSigTimeoutTime_ASBS" SG_ 2654486539 CBV_bit0_RepeatMessageRequestBit_1E38400B 0;
BA_ "GenSigTimeoutTime_BCM" SG_ 2654486539 CBV_bit0_RepeatMessageRequestBit_1E38400B 0;
BA_ "GenSigTimeoutTime_BSM" SG_ 2654486539 CBV_bit0_RepeatMessageRequestBit_1E38400B 0;
BA_ "GenSigTimeoutTime_CADM" SG_ 2654486539 CBV_bit0_RepeatMessageRequestBit_1E38400B 0;
BA_ "GenSigTimeoutTime_DMSM" SG_ 2654486539 CBV_bit0_RepeatMessageRequestBit_1E38400B 0;
BA_ "GenSigTimeoutTime_DTCM" SG_ 2654486539 CBV_bit0_RepeatMessageRequestBit_1E38400B 0;
BA_ "GenSigTimeoutTime_ECM" SG_ 2654486539 CBV_bit0_RepeatMessageRequestBit_1E38400B 0;
BA_ "GenSigTimeoutTime_ELSDM" SG_ 2654486539 CBV_bit0_RepeatMessageRequestBit_1E38400B 0;
BA_ "GenSigTimeoutTime_ESL" SG_ 2654486539 CBV_bit0_RepeatMessageRequestBit_1E38400B 0;
BA_ "GenSigTimeoutTime_GNMM" SG_ 2654486539 CBV_bit0_RepeatMessageRequestBit_1E38400B 0;
BA_ "GenSigTimeoutTime_HCP" SG_ 2654486539 CBV_bit0_RepeatMessageRequestBit_1E38400B 0;
BA_ "GenSigTimeoutTime_IPC" SG_ 2654486539 CBV_bit0_RepeatMessageRequestBit_1E38400B 0;
BA_ "GenSigTimeoutTime_RFHM" SG_ 2654486539 CBV_bit0_RepeatMessageRequestBit_1E38400B 0;
BA_ "GenSigTimeoutTime_SGW" SG_ 2654486539 CBV_bit0_RepeatMessageRequestBit_1E38400B 0;
BA_ "GenSigTimeoutTime_TCM" SG_ 2654486539 CBV_bit0_RepeatMessageRequestBit_1E38400B 0;
BA_ "GenSigTimeoutTime_AGSM" SG_ 2654486539 CBV_bit1_1E38400B 0;
BA_ "GenSigTimeoutTime_ASBS" SG_ 2654486539 CBV_bit1_1E38400B 0;
BA_ "GenSigTimeoutTime_BCM" SG_ 2654486539 CBV_bit1_1E38400B 0;
BA_ "GenSigTimeoutTime_BSM" SG_ 2654486539 CBV_bit1_1E38400B 0;
BA_ "GenSigTimeoutTime_CADM" SG_ 2654486539 CBV_bit1_1E38400B 0;
BA_ "GenSigTimeoutTime_DMSM" SG_ 2654486539 CBV_bit1_1E38400B 0;
BA_ "GenSigTimeoutTime_DTCM" SG_ 2654486539 CBV_bit1_1E38400B 0;
BA_ "GenSigTimeoutTime_ECM" SG_ 2654486539 CBV_bit1_1E38400B 0;
BA_ "GenSigTimeoutTime_ELSDM" SG_ 2654486539 CBV_bit1_1E38400B 0;
BA_ "GenSigTimeoutTime_ESL" SG_ 2654486539 CBV_bit1_1E38400B 0;
BA_ "GenSigTimeoutTime_GNMM" SG_ 2654486539 CBV_bit1_1E38400B 0;
BA_ "GenSigTimeoutTime_HCP" SG_ 2654486539 CBV_bit1_1E38400B 0;
BA_ "GenSigTimeoutTime_IPC" SG_ 2654486539 CBV_bit1_1E38400B 0;
BA_ "GenSigTimeoutTime_RFHM" SG_ 2654486539 CBV_bit1_1E38400B 0;
BA_ "GenSigTimeoutTime_SGW" SG_ 2654486539 CBV_bit1_1E38400B 0;
BA_ "GenSigTimeoutTime_TCM" SG_ 2654486539 CBV_bit1_1E38400B 0;
BA_ "GenSigTimeoutTime_AGSM" SG_ 2654486539 CBV_bit2_1E38400B 0;
BA_ "GenSigTimeoutTime_ASBS" SG_ 2654486539 CBV_bit2_1E38400B 0;
BA_ "GenSigTimeoutTime_BCM" SG_ 2654486539 CBV_bit2_1E38400B 0;
BA_ "GenSigTimeoutTime_BSM" SG_ 2654486539 CBV_bit2_1E38400B 0;
BA_ "GenSigTimeoutTime_CADM" SG_ 2654486539 CBV_bit2_1E38400B 0;
BA_ "GenSigTimeoutTime_DMSM" SG_ 2654486539 CBV_bit2_1E38400B 0;
BA_ "GenSigTimeoutTime_DTCM" SG_ 2654486539 CBV_bit2_1E38400B 0;
BA_ "GenSigTimeoutTime_ECM" SG_ 2654486539 CBV_bit2_1E38400B 0;
BA_ "GenSigTimeoutTime_ELSDM" SG_ 2654486539 CBV_bit2_1E38400B 0;
BA_ "GenSigTimeoutTime_ESL" SG_ 2654486539 CBV_bit2_1E38400B 0;
BA_ "GenSigTimeoutTime_GNMM" SG_ 2654486539 CBV_bit2_1E38400B 0;
BA_ "GenSigTimeoutTime_HCP" SG_ 2654486539 CBV_bit2_1E38400B 0;
BA_ "GenSigTimeoutTime_IPC" SG_ 2654486539 CBV_bit2_1E38400B 0;
BA_ "GenSigTimeoutTime_RFHM" SG_ 2654486539 CBV_bit2_1E38400B 0;
BA_ "GenSigTimeoutTime_SGW" SG_ 2654486539 CBV_bit2_1E38400B 0;
BA_ "GenSigTimeoutTime_TCM" SG_ 2654486539 CBV_bit2_1E38400B 0;
BA_ "GenSigTimeoutTime_AGSM" SG_ 2654486539 CBV_bit3_NMCoordinatorBit_1E38400B 0;
BA_ "GenSigTimeoutTime_ASBS" SG_ 2654486539 CBV_bit3_NMCoordinatorBit_1E38400B 0;
BA_ "GenSigTimeoutTime_BCM" SG_ 2654486539 CBV_bit3_NMCoordinatorBit_1E38400B 0;
BA_ "GenSigTimeoutTime_BSM" SG_ 2654486539 CBV_bit3_NMCoordinatorBit_1E38400B 0;
BA_ "GenSigTimeoutTime_CADM" SG_ 2654486539 CBV_bit3_NMCoordinatorBit_1E38400B 0;
BA_ "GenSigTimeoutTime_DMSM" SG_ 2654486539 CBV_bit3_NMCoordinatorBit_1E38400B 0;
BA_ "GenSigTimeoutTime_DTCM" SG_ 2654486539 CBV_bit3_NMCoordinatorBit_1E38400B 0;
BA_ "GenSigTimeoutTime_ECM" SG_ 2654486539 CBV_bit3_NMCoordinatorBit_1E38400B 0;
BA_ "GenSigTimeoutTime_ELSDM" SG_ 2654486539 CBV_bit3_NMCoordinatorBit_1E38400B 0;
BA_ "GenSigTimeoutTime_ESL" SG_ 2654486539 CBV_bit3_NMCoordinatorBit_1E38400B 0;
BA_ "GenSigTimeoutTime_GNMM" SG_ 2654486539 CBV_bit3_NMCoordinatorBit_1E38400B 0;
BA_ "GenSigTimeoutTime_HCP" SG_ 2654486539 CBV_bit3_NMCoordinatorBit_1E38400B 0;
BA_ "GenSigTimeoutTime_IPC" SG_ 2654486539 CBV_bit3_NMCoordinatorBit_1E38400B 0;
BA_ "GenSigTimeoutTime_RFHM" SG_ 2654486539 CBV_bit3_NMCoordinatorBit_1E38400B 0;
BA_ "GenSigTimeoutTime_SGW" SG_ 2654486539 CBV_bit3_NMCoordinatorBit_1E38400B 0;
BA_ "GenSigTimeoutTime_TCM" SG_ 2654486539 CBV_bit3_NMCoordinatorBit_1E38400B 0;
BA_ "GenSigTimeoutTime_AGSM" SG_ 2654486539 CBV_bit4_ActiveWakeupBit_1E38400B 0;
BA_ "GenSigTimeoutTime_ASBS" SG_ 2654486539 CBV_bit4_ActiveWakeupBit_1E38400B 0;
BA_ "GenSigTimeoutTime_BCM" SG_ 2654486539 CBV_bit4_ActiveWakeupBit_1E38400B 0;
BA_ "GenSigTimeoutTime_BSM" SG_ 2654486539 CBV_bit4_ActiveWakeupBit_1E38400B 0;
BA_ "GenSigTimeoutTime_CADM" SG_ 2654486539 CBV_bit4_ActiveWakeupBit_1E38400B 0;
BA_ "GenSigTimeoutTime_DMSM" SG_ 2654486539 CBV_bit4_ActiveWakeupBit_1E38400B 0;
BA_ "GenSigTimeoutTime_DTCM" SG_ 2654486539 CBV_bit4_ActiveWakeupBit_1E38400B 0;
BA_ "GenSigTimeoutTime_ECM" SG_ 2654486539 CBV_bit4_ActiveWakeupBit_1E38400B 0;
BA_ "GenSigTimeoutTime_ELSDM" SG_ 2654486539 CBV_bit4_ActiveWakeupBit_1E38400B 0;
BA_ "GenSigTimeoutTime_ESL" SG_ 2654486539 CBV_bit4_ActiveWakeupBit_1E38400B 0;
BA_ "GenSigTimeoutTime_GNMM" SG_ 2654486539 CBV_bit4_ActiveWakeupBit_1E38400B 0;
BA_ "GenSigTimeoutTime_HCP" SG_ 2654486539 CBV_bit4_ActiveWakeupBit_1E38400B 0;
BA_ "GenSigTimeoutTime_IPC" SG_ 2654486539 CBV_bit4_ActiveWakeupBit_1E38400B 0;
BA_ "GenSigTimeoutTime_RFHM" SG_ 2654486539 CBV_bit4_ActiveWakeupBit_1E38400B 0;
BA_ "GenSigTimeoutTime_SGW" SG_ 2654486539 CBV_bit4_ActiveWakeupBit_1E38400B 0;
BA_ "GenSigTimeoutTime_TCM" SG_ 2654486539 CBV_bit4_ActiveWakeupBit_1E38400B 0;
BA_ "GenSigTimeoutTime_AGSM" SG_ 2654486539 CBV_bit5_1E38400B 0;
BA_ "GenSigTimeoutTime_ASBS" SG_ 2654486539 CBV_bit5_1E38400B 0;
BA_ "GenSigTimeoutTime_BCM" SG_ 2654486539 CBV_bit5_1E38400B 0;
BA_ "GenSigTimeoutTime_BSM" SG_ 2654486539 CBV_bit5_1E38400B 0;
BA_ "GenSigTimeoutTime_CADM" SG_ 2654486539 CBV_bit5_1E38400B 0;
BA_ "GenSigTimeoutTime_DMSM" SG_ 2654486539 CBV_bit5_1E38400B 0;
BA_ "GenSigTimeoutTime_DTCM" SG_ 2654486539 CBV_bit5_1E38400B 0;
BA_ "GenSigTimeoutTime_ECM" SG_ 2654486539 CBV_bit5_1E38400B 0;
BA_ "GenSigTimeoutTime_ELSDM" SG_ 2654486539 CBV_bit5_1E38400B 0;
BA_ "GenSigTimeoutTime_ESL" SG_ 2654486539 CBV_bit5_1E38400B 0;
BA_ "GenSigTimeoutTime_GNMM" SG_ 2654486539 CBV_bit5_1E38400B 0;
BA_ "GenSigTimeoutTime_HCP" SG_ 2654486539 CBV_bit5_1E38400B 0;
BA_ "GenSigTimeoutTime_IPC" SG_ 2654486539 CBV_bit5_1E38400B 0;
BA_ "GenSigTimeoutTime_RFHM" SG_ 2654486539 CBV_bit5_1E38400B 0;
BA_ "GenSigTimeoutTime_SGW" SG_ 2654486539 CBV_bit5_1E38400B 0;
BA_ "GenSigTimeoutTime_TCM" SG_ 2654486539 CBV_bit5_1E38400B 0;
BA_ "GenSigTimeoutTime_AGSM" SG_ 2654486539 CBV_bit6_PartialNtwInfBit_1E38400B 0;
BA_ "GenSigTimeoutTime_ASBS" SG_ 2654486539 CBV_bit6_PartialNtwInfBit_1E38400B 0;
BA_ "GenSigTimeoutTime_BCM" SG_ 2654486539 CBV_bit6_PartialNtwInfBit_1E38400B 0;
BA_ "GenSigTimeoutTime_BSM" SG_ 2654486539 CBV_bit6_PartialNtwInfBit_1E38400B 0;
BA_ "GenSigTimeoutTime_CADM" SG_ 2654486539 CBV_bit6_PartialNtwInfBit_1E38400B 0;
BA_ "GenSigTimeoutTime_DMSM" SG_ 2654486539 CBV_bit6_PartialNtwInfBit_1E38400B 0;
BA_ "GenSigTimeoutTime_DTCM" SG_ 2654486539 CBV_bit6_PartialNtwInfBit_1E38400B 0;
BA_ "GenSigTimeoutTime_ECM" SG_ 2654486539 CBV_bit6_PartialNtwInfBit_1E38400B 0;
BA_ "GenSigTimeoutTime_ELSDM" SG_ 2654486539 CBV_bit6_PartialNtwInfBit_1E38400B 0;
BA_ "GenSigTimeoutTime_ESL" SG_ 2654486539 CBV_bit6_PartialNtwInfBit_1E38400B 0;
BA_ "GenSigTimeoutTime_GNMM" SG_ 2654486539 CBV_bit6_PartialNtwInfBit_1E38400B 0;
BA_ "GenSigTimeoutTime_HCP" SG_ 2654486539 CBV_bit6_PartialNtwInfBit_1E38400B 0;
BA_ "GenSigTimeoutTime_IPC" SG_ 2654486539 CBV_bit6_PartialNtwInfBit_1E38400B 0;
BA_ "GenSigTimeoutTime_RFHM" SG_ 2654486539 CBV_bit6_PartialNtwInfBit_1E38400B 0;
BA_ "GenSigTimeoutTime_SGW" SG_ 2654486539 CBV_bit6_PartialNtwInfBit_1E38400B 0;
BA_ "GenSigTimeoutTime_TCM" SG_ 2654486539 CBV_bit6_PartialNtwInfBit_1E38400B 0;
BA_ "GenSigTimeoutTime_AGSM" SG_ 2654486539 CBV_bit7_1E38400B 0;
BA_ "GenSigTimeoutTime_ASBS" SG_ 2654486539 CBV_bit7_1E38400B 0;
BA_ "GenSigTimeoutTime_BCM" SG_ 2654486539 CBV_bit7_1E38400B 0;
BA_ "GenSigTimeoutTime_BSM" SG_ 2654486539 CBV_bit7_1E38400B 0;
BA_ "GenSigTimeoutTime_CADM" SG_ 2654486539 CBV_bit7_1E38400B 0;
BA_ "GenSigTimeoutTime_DMSM" SG_ 2654486539 CBV_bit7_1E38400B 0;
BA_ "GenSigTimeoutTime_DTCM" SG_ 2654486539 CBV_bit7_1E38400B 0;
BA_ "GenSigTimeoutTime_ECM" SG_ 2654486539 CBV_bit7_1E38400B 0;
BA_ "GenSigTimeoutTime_ELSDM" SG_ 2654486539 CBV_bit7_1E38400B 0;
BA_ "GenSigTimeoutTime_ESL" SG_ 2654486539 CBV_bit7_1E38400B 0;
BA_ "GenSigTimeoutTime_GNMM" SG_ 2654486539 CBV_bit7_1E38400B 0;
BA_ "GenSigTimeoutTime_HCP" SG_ 2654486539 CBV_bit7_1E38400B 0;
BA_ "GenSigTimeoutTime_IPC" SG_ 2654486539 CBV_bit7_1E38400B 0;
BA_ "GenSigTimeoutTime_RFHM" SG_ 2654486539 CBV_bit7_1E38400B 0;
BA_ "GenSigTimeoutTime_SGW" SG_ 2654486539 CBV_bit7_1E38400B 0;
BA_ "GenSigTimeoutTime_TCM" SG_ 2654486539 CBV_bit7_1E38400B 0;
BA_ "GenSigTimeoutTime_AGSM" SG_ 2654486539 SourceNodeIdentifier_1E38400B 0;
BA_ "GenSigTimeoutTime_ASBS" SG_ 2654486539 SourceNodeIdentifier_1E38400B 0;
BA_ "GenSigTimeoutTime_BCM" SG_ 2654486539 SourceNodeIdentifier_1E38400B 0;
BA_ "GenSigTimeoutTime_BSM" SG_ 2654486539 SourceNodeIdentifier_1E38400B 0;
BA_ "GenSigTimeoutTime_CADM" SG_ 2654486539 SourceNodeIdentifier_1E38400B 0;
BA_ "GenSigTimeoutTime_DMSM" SG_ 2654486539 SourceNodeIdentifier_1E38400B 0;
BA_ "GenSigTimeoutTime_DTCM" SG_ 2654486539 SourceNodeIdentifier_1E38400B 0;
BA_ "GenSigTimeoutTime_ECM" SG_ 2654486539 SourceNodeIdentifier_1E38400B 0;
BA_ "GenSigTimeoutTime_ELSDM" SG_ 2654486539 SourceNodeIdentifier_1E38400B 0;
BA_ "GenSigTimeoutTime_ESL" SG_ 2654486539 SourceNodeIdentifier_1E38400B 0;
BA_ "GenSigTimeoutTime_GNMM" SG_ 2654486539 SourceNodeIdentifier_1E38400B 0;
BA_ "GenSigTimeoutTime_HCP" SG_ 2654486539 SourceNodeIdentifier_1E38400B 0;
BA_ "GenSigTimeoutTime_IPC" SG_ 2654486539 SourceNodeIdentifier_1E38400B 0;
BA_ "GenSigTimeoutTime_RFHM" SG_ 2654486539 SourceNodeIdentifier_1E38400B 0;
BA_ "GenSigTimeoutTime_SGW" SG_ 2654486539 SourceNodeIdentifier_1E38400B 0;
BA_ "GenSigTimeoutTime_TCM" SG_ 2654486539 SourceNodeIdentifier_1E38400B 0;
BA_ "GenSigTimeoutTime_IPC" SG_ 2654486549 CBV_bit3_NMCoordinatorBit_1E384015 0;
BA_ "GenSigTimeoutTime_RFHM" SG_ 2654486549 CBV_bit3_NMCoordinatorBit_1E384015 0;
BA_ "GenSigTimeoutTime_SGW" SG_ 2654486549 CBV_bit3_NMCoordinatorBit_1E384015 0;
BA_ "GenSigTimeoutTime_TCM" SG_ 2654486549 CBV_bit3_NMCoordinatorBit_1E384015 0;
BA_ "GenSigTimeoutTime_AGSM" SG_ 2654486549 CBV_bit4_ActiveWakeupBit_1E384015 0;
BA_ "GenSigTimeoutTime_ASBS" SG_ 2654486549 CBV_bit4_ActiveWakeupBit_1E384015 0;
BA_ "GenSigTimeoutTime_BCM" SG_ 2654486549 CBV_bit4_ActiveWakeupBit_1E384015 0;
BA_ "GenSigTimeoutTime_BSM" SG_ 2654486549 CBV_bit4_ActiveWakeupBit_1E384015 0;
BA_ "GenSigTimeoutTime_CADM" SG_ 2654486549 CBV_bit4_ActiveWakeupBit_1E384015 0;
BA_ "GenSigTimeoutTime_DMSM" SG_ 2654486549 CBV_bit4_ActiveWakeupBit_1E384015 0;
BA_ "GenSigTimeoutTime_DTCM" SG_ 2654486549 CBV_bit4_ActiveWakeupBit_1E384015 0;
BA_ "GenSigTimeoutTime_ECM" SG_ 2654486549 CBV_bit4_ActiveWakeupBit_1E384015 0;
BA_ "GenSigTimeoutTime_ELSDM" SG_ 2654486549 CBV_bit4_ActiveWakeupBit_1E384015 0;
BA_ "GenSigTimeoutTime_ESL" SG_ 2654486549 CBV_bit4_ActiveWakeupBit_1E384015 0;
BA_ "GenSigTimeoutTime_GNMM" SG_ 2654486549 CBV_bit4_ActiveWakeupBit_1E384015 0;
BA_ "GenSigTimeoutTime_HCP" SG_ 2654486549 CBV_bit4_ActiveWakeupBit_1E384015 0;
BA_ "GenSigTimeoutTime_IPC" SG_ 2654486549 CBV_bit4_ActiveWakeupBit_1E384015 0;
BA_ "GenSigTimeoutTime_RFHM" SG_ 2654486549 CBV_bit4_ActiveWakeupBit_1E384015 0;
BA_ "GenSigTimeoutTime_SGW" SG_ 2654486549 CBV_bit4_ActiveWakeupBit_1E384015 0;
BA_ "GenSigTimeoutTime_TCM" SG_ 2654486549 CBV_bit4_ActiveWakeupBit_1E384015 0;
BA_ "GenSigTimeoutTime_AGSM" SG_ 2654486549 CBV_bit5_1E384015 0;
BA_ "GenSigTimeoutTime_ASBS" SG_ 2654486549 CBV_bit5_1E384015 0;
BA_ "GenSigTimeoutTime_BCM" SG_ 2654486549 CBV_bit5_1E384015 0;
BA_ "GenSigTimeoutTime_BSM" SG_ 2654486549 CBV_bit5_1E384015 0;
BA_ "GenSigTimeoutTime_CADM" SG_ 2654486549 CBV_bit5_1E384015 0;
BA_ "GenSigTimeoutTime_DMSM" SG_ 2654486549 CBV_bit5_1E384015 0;
BA_ "GenSigTimeoutTime_DTCM" SG_ 2654486549 CBV_bit5_1E384015 0;
BA_ "GenSigTimeoutTime_ECM" SG_ 2654486549 CBV_bit5_1E384015 0;
BA_ "GenSigTimeoutTime_ELSDM" SG_ 2654486549 CBV_bit5_1E384015 0;
BA_ "GenSigTimeoutTime_ESL" SG_ 2654486549 CBV_bit5_1E384015 0;
BA_ "GenSigTimeoutTime_GNMM" SG_ 2654486549 CBV_bit5_1E384015 0;
BA_ "GenSigTimeoutTime_HCP" SG_ 2654486549 CBV_bit5_1E384015 0;
BA_ "GenSigTimeoutTime_IPC" SG_ 2654486549 CBV_bit5_1E384015 0;
BA_ "GenSigTimeoutTime_RFHM" SG_ 2654486549 CBV_bit5_1E384015 0;
BA_ "GenSigTimeoutTime_SGW" SG_ 2654486549 CBV_bit5_1E384015 0;
BA_ "GenSigTimeoutTime_TCM" SG_ 2654486549 CBV_bit5_1E384015 0;
BA_ "GenSigTimeoutTime_AGSM" SG_ 2654486549 CBV_bit6_PartialNtwInfBit_1E384015 0;
BA_ "GenSigTimeoutTime_ASBS" SG_ 2654486549 CBV_bit6_PartialNtwInfBit_1E384015 0;
BA_ "GenSigTimeoutTime_BCM" SG_ 2654486549 CBV_bit6_PartialNtwInfBit_1E384015 0;
BA_ "GenSigTimeoutTime_BSM" SG_ 2654486549 CBV_bit6_PartialNtwInfBit_1E384015 0;
BA_ "GenSigTimeoutTime_CADM" SG_ 2654486549 CBV_bit6_PartialNtwInfBit_1E384015 0;
BA_ "GenSigTimeoutTime_DMSM" SG_ 2654486549 CBV_bit6_PartialNtwInfBit_1E384015 0;
BA_ "GenSigTimeoutTime_DTCM" SG_ 2654486549 CBV_bit6_PartialNtwInfBit_1E384015 0;
BA_ "GenSigTimeoutTime_ECM" SG_ 2654486549 CBV_bit6_PartialNtwInfBit_1E384015 0;
BA_ "GenSigTimeoutTime_ELSDM" SG_ 2654486549 CBV_bit6_PartialNtwInfBit_1E384015 0;
BA_ "GenSigTimeoutTime_ESL" SG_ 2654486549 CBV_bit6_PartialNtwInfBit_1E384015 0;
BA_ "GenSigTimeoutTime_GNMM" SG_ 2654486549 CBV_bit6_PartialNtwInfBit_1E384015 0;
BA_ "GenSigTimeoutTime_HCP" SG_ 2654486549 CBV_bit6_PartialNtwInfBit_1E384015 0;
BA_ "GenSigTimeoutTime_IPC" SG_ 2654486549 CBV_bit6_PartialNtwInfBit_1E384015 0;
BA_ "GenSigTimeoutTime_RFHM" SG_ 2654486549 CBV_bit6_PartialNtwInfBit_1E384015 0;
BA_ "GenSigTimeoutTime_SGW" SG_ 2654486549 CBV_bit6_PartialNtwInfBit_1E384015 0;
BA_ "GenSigTimeoutTime_TCM" SG_ 2654486549 CBV_bit6_PartialNtwInfBit_1E384015 0;
BA_ "GenSigTimeoutTime_AGSM" SG_ 2654486549 CBV_bit7_1E384015 0;
BA_ "GenSigTimeoutTime_ASBS" SG_ 2654486549 CBV_bit7_1E384015 0;
BA_ "GenSigTimeoutTime_BCM" SG_ 2654486549 CBV_bit7_1E384015 0;
BA_ "GenSigTimeoutTime_BSM" SG_ 2654486549 CBV_bit7_1E384015 0;
BA_ "GenSigTimeoutTime_CADM" SG_ 2654486549 CBV_bit7_1E384015 0;
BA_ "GenSigTimeoutTime_DMSM" SG_ 2654486549 CBV_bit7_1E384015 0;
BA_ "GenSigTimeoutTime_DTCM" SG_ 2654486549 CBV_bit7_1E384015 0;
BA_ "GenSigTimeoutTime_ECM" SG_ 2654486549 CBV_bit7_1E384015 0;
BA_ "GenSigTimeoutTime_ELSDM" SG_ 2654486549 CBV_bit7_1E384015 0;
BA_ "GenSigTimeoutTime_ESL" SG_ 2654486549 CBV_bit7_1E384015 0;
BA_ "GenSigTimeoutTime_GNMM" SG_ 2654486549 CBV_bit7_1E384015 0;
BA_ "GenSigTimeoutTime_HCP" SG_ 2654486549 CBV_bit7_1E384015 0;
BA_ "GenSigTimeoutTime_IPC" SG_ 2654486549 CBV_bit7_1E384015 0;
BA_ "GenSigTimeoutTime_RFHM" SG_ 2654486549 CBV_bit7_1E384015 0;
BA_ "GenSigTimeoutTime_SGW" SG_ 2654486549 CBV_bit7_1E384015 0;
BA_ "GenSigTimeoutTime_TCM" SG_ 2654486549 CBV_bit7_1E384015 0;
BA_ "GenSigTimeoutTime_AGSM" SG_ 2654486549 SourceNodeIdentifier_1E384015 0;
BA_ "GenSigTimeoutTime_ASBS" SG_ 2654486549 SourceNodeIdentifier_1E384015 0;
BA_ "GenSigTimeoutTime_BCM" SG_ 2654486549 SourceNodeIdentifier_1E384015 0;
BA_ "GenSigTimeoutTime_BSM" SG_ 2654486549 SourceNodeIdentifier_1E384015 0;
BA_ "GenSigTimeoutTime_CADM" SG_ 2654486549 SourceNodeIdentifier_1E384015 0;
BA_ "GenSigTimeoutTime_DMSM" SG_ 2654486549 SourceNodeIdentifier_1E384015 0;
BA_ "GenSigTimeoutTime_DTCM" SG_ 2654486549 SourceNodeIdentifier_1E384015 0;
BA_ "GenSigTimeoutTime_ECM" SG_ 2654486549 SourceNodeIdentifier_1E384015 0;
BA_ "GenSigTimeoutTime_ELSDM" SG_ 2654486549 SourceNodeIdentifier_1E384015 0;
BA_ "GenSigTimeoutTime_ESL" SG_ 2654486549 SourceNodeIdentifier_1E384015 0;
BA_ "GenSigTimeoutTime_GNMM" SG_ 2654486549 SourceNodeIdentifier_1E384015 0;
BA_ "GenSigTimeoutTime_ESL" SG_ 2654486669 CBV_bit1_1E38408D 0;
BA_ "GenSigTimeoutTime_GNMM" SG_ 2654486669 CBV_bit1_1E38408D 0;
BA_ "GenSigTimeoutTime_HCP" SG_ 2654486669 CBV_bit1_1E38408D 0;
BA_ "GenSigTimeoutTime_IPC" SG_ 2654486669 CBV_bit1_1E38408D 0;
BA_ "GenSigTimeoutTime_RFHM" SG_ 2654486669 CBV_bit1_1E38408D 0;
BA_ "GenSigTimeoutTime_SGW" SG_ 2654486669 CBV_bit1_1E38408D 0;
BA_ "GenSigTimeoutTime_TCM" SG_ 2654486669 CBV_bit1_1E38408D 0;
BA_ "GenSigTimeoutTime_AGSM" SG_ 2654486669 CBV_bit2_1E38408D 0;
BA_ "GenSigTimeoutTime_ASBS" SG_ 2654486669 CBV_bit2_1E38408D 0;
BA_ "GenSigTimeoutTime_BCM" SG_ 2654486669 CBV_bit2_1E38408D 0;
BA_ "GenSigTimeoutTime_BSM" SG_ 2654486669 CBV_bit2_1E38408D 0;
BA_ "GenSigTimeoutTime_CADM" SG_ 2654486669 CBV_bit2_1E38408D 0;
BA_ "GenSigTimeoutTime_DMSM" SG_ 2654486669 CBV_bit2_1E38408D 0;
BA_ "GenSigTimeoutTime_DTCM" SG_ 2654486669 CBV_bit2_1E38408D 0;
BA_ "GenSigTimeoutTime_ECM" SG_ 2654486669 CBV_bit2_1E38408D 0;
BA_ "GenSigTimeoutTime_ELSDM" SG_ 2654486669 CBV_bit2_1E38408D 0;
BA_ "GenSigTimeoutTime_ESL" SG_ 2654486669 CBV_bit2_1E38408D 0;
BA_ "GenSigTimeoutTime_GNMM" SG_ 2654486669 CBV_bit2_1E38408D 0;
BA_ "GenSigTimeoutTime_HCP" SG_ 2654486669 CBV_bit2_1E38408D 0;
BA_ "GenSigTimeoutTime_IPC" SG_ 2654486669 CBV_bit2_1E38408D 0;
BA_ "GenSigTimeoutTime_RFHM" SG_ 2654486669 CBV_bit2_1E38408D 0;
BA_ "GenSigTimeoutTime_SGW" SG_ 2654486669 CBV_bit2_1E38408D 0;
BA_ "GenSigTimeoutTime_TCM" SG_ 2654486669 CBV_bit2_1E38408D 0;
BA_ "GenSigTimeoutTime_AGSM" SG_ 2654486669 CBV_bit3_NMCoordinatorBit_1E38408D 0;
BA_ "GenSigTimeoutTime_ASBS" SG_ 2654486669 CBV_bit3_NMCoordinatorBit_1E38408D 0;
BA_ "GenSigTimeoutTime_BCM" SG_ 2654486669 CBV_bit3_NMCoordinatorBit_1E38408D 0;
BA_ "GenSigTimeoutTime_BSM" SG_ 2654486669 CBV_bit3_NMCoordinatorBit_1E38408D 0;
BA_ "GenSigTimeoutTime_CADM" SG_ 2654486669 CBV_bit3_NMCoordinatorBit_1E38408D 0;
BA_ "GenSigTimeoutTime_DMSM" SG_ 2654486669 CBV_bit3_NMCoordinatorBit_1E38408D 0;
BA_ "GenSigTimeoutTime_DTCM" SG_ 2654486669 CBV_bit3_NMCoordinatorBit_1E38408D 0;
BA_ "GenSigTimeoutTime_ECM" SG_ 2654486669 CBV_bit3_NMCoordinatorBit_1E38408D 0;
BA_ "GenSigTimeoutTime_ELSDM" SG_ 2654486669 CBV_bit3_NMCoordinatorBit_1E38408D 0;
BA_ "GenSigTimeoutTime_ESL" SG_ 2654486669 CBV_bit3_NMCoordinatorBit_1E38408D 0;
BA_ "GenSigTimeoutTime_GNMM" SG_ 2654486669 CBV_bit3_NMCoordinatorBit_1E38408D 0;
BA_ "GenSigTimeoutTime_HCP" SG_ 2654486669 CBV_bit3_NMCoordinatorBit_1E38408D 0;
BA_ "GenSigTimeoutTime_IPC" SG_ 2654486669 CBV_bit3_NMCoordinatorBit_1E38408D 0;
BA_ "GenSigTimeoutTime_RFHM" SG_ 2654486669 CBV_bit3_NMCoordinatorBit_1E38408D 0;
BA_ "GenSigTimeoutTime_SGW" SG_ 2654486669 CBV_bit3_NMCoordinatorBit_1E38408D 0;
BA_ "GenSigTimeoutTime_TCM" SG_ 2654486669 CBV_bit3_NMCoordinatorBit_1E38408D 0;
BA_ "GenSigTimeoutTime_AGSM" SG_ 2654486669 CBV_bit4_ActiveWakeupBit_1E38408D 0;
BA_ "GenSigTimeoutTime_ASBS" SG_ 2654486669 CBV_bit4_ActiveWakeupBit_1E38408D 0;
BA_ "GenSigTimeoutTime_BCM" SG_ 2654486669 CBV_bit4_ActiveWakeupBit_1E38408D 0;
BA_ "GenSigTimeoutTime_BSM" SG_ 2654486669 CBV_bit4_ActiveWakeupBit_1E38408D 0;
BA_ "GenSigTimeoutTime_CADM" SG_ 2654486669 CBV_bit4_ActiveWakeupBit_1E38408D 0;
BA_ "GenSigTimeoutTime_DMSM" SG_ 2654486669 CBV_bit4_ActiveWakeupBit_1E38408D 0;
BA_ "GenSigTimeoutTime_DTCM" SG_ 2654486669 CBV_bit4_ActiveWakeupBit_1E38408D 0;
BA_ "GenSigTimeoutTime_ECM" SG_ 2654486669 CBV_bit4_ActiveWakeupBit_1E38408D 0;
BA_ "GenSigTimeoutTime_ELSDM" SG_ 2654486669 CBV_bit4_ActiveWakeupBit_1E38408D 0;
BA_ "GenSigTimeoutTime_ESL" SG_ 2654486669 CBV_bit4_ActiveWakeupBit_1E38408D 0;
BA_ "GenSigTimeoutTime_GNMM" SG_ 2654486669 CBV_bit4_ActiveWakeupBit_1E38408D 0;
BA_ "GenSigTimeoutTime_HCP" SG_ 2654486669 CBV_bit4_ActiveWakeupBit_1E38408D 0;
BA_ "GenSigTimeoutTime_IPC" SG_ 2654486669 CBV_bit4_ActiveWakeupBit_1E38408D 0;
BA_ "GenSigTimeoutTime_RFHM" SG_ 2654486669 CBV_bit4_ActiveWakeupBit_1E38408D 0;
BA_ "GenSigTimeoutTime_SGW" SG_ 2654486669 CBV_bit4_ActiveWakeupBit_1E38408D 0;
BA_ "GenSigTimeoutTime_TCM" SG_ 2654486669 CBV_bit4_ActiveWakeupBit_1E38408D 0;
BA_ "GenSigTimeoutTime_AGSM" SG_ 2654486669 CBV_bit5_1E38408D 0;
BA_ "GenSigTimeoutTime_ASBS" SG_ 2654486669 CBV_bit5_1E38408D 0;
BA_ "GenSigTimeoutTime_BCM" SG_ 2654486669 CBV_bit5_1E38408D 0;
BA_ "GenSigTimeoutTime_BSM" SG_ 2654486669 CBV_bit5_1E38408D 0;
BA_ "GenSigTimeoutTime_CADM" SG_ 2654486669 CBV_bit5_1E38408D 0;
BA_ "GenSigTimeoutTime_DMSM" SG_ 2654486669 CBV_bit5_1E38408D 0;
BA_ "GenSigTimeoutTime_DTCM" SG_ 2654486669 CBV_bit5_1E38408D 0;
BA_ "GenSigTimeoutTime_ECM" SG_ 2654486669 CBV_bit5_1E38408D 0;
BA_ "GenSigTimeoutTime_ELSDM" SG_ 2654486669 CBV_bit5_1E38408D 0;
BA_ "GenSigTimeoutTime_ESL" SG_ 2654486669 CBV_bit5_1E38408D 0;
BA_ "GenSigTimeoutTime_GNMM" SG_ 2654486669 CBV_bit5_1E38408D 0;
BA_ "GenSigTimeoutTime_HCP" SG_ 2654486669 CBV_bit5_1E38408D 0;
BA_ "GenSigTimeoutTime_IPC" SG_ 2654486669 CBV_bit5_1E38408D 0;
BA_ "GenSigTimeoutTime_RFHM" SG_ 2654486669 CBV_bit5_1E38408D 0;
BA_ "GenSigTimeoutTime_HCP" SG_ 2654486549 SourceNodeIdentifier_1E384015 0;
BA_ "GenSigTimeoutTime_IPC" SG_ 2654486549 SourceNodeIdentifier_1E384015 0;
BA_ "GenSigTimeoutTime_RFHM" SG_ 2654486549 SourceNodeIdentifier_1E384015 0;
BA_ "GenSigTimeoutTime_SGW" SG_ 2654486549 SourceNodeIdentifier_1E384015 0;
BA_ "GenSigTimeoutTime_TCM" SG_ 2654486549 SourceNodeIdentifier_1E384015 0;
BA_ "GenSigTimeoutTime_AGSM" SG_ 2654486626 CBV_bit0_RepeatMessageRequestBit_1E384062 0;
BA_ "GenSigTimeoutTime_ASBS" SG_ 2654486626 CBV_bit0_RepeatMessageRequestBit_1E384062 0;
BA_ "GenSigTimeoutTime_BCM" SG_ 2654486626 CBV_bit0_RepeatMessageRequestBit_1E384062 0;
BA_ "GenSigTimeoutTime_BSM" SG_ 2654486626 CBV_bit0_RepeatMessageRequestBit_1E384062 0;
BA_ "GenSigTimeoutTime_CADM" SG_ 2654486626 CBV_bit0_RepeatMessageRequestBit_1E384062 0;
BA_ "GenSigTimeoutTime_DMSM" SG_ 2654486626 CBV_bit0_RepeatMessageRequestBit_1E384062 0;
BA_ "GenSigTimeoutTime_DTCM" SG_ 2654486626 CBV_bit0_RepeatMessageRequestBit_1E384062 0;
BA_ "GenSigTimeoutTime_ECM" SG_ 2654486626 CBV_bit0_RepeatMessageRequestBit_1E384062 0;
BA_ "GenSigTimeoutTime_ELSDM" SG_ 2654486626 CBV_bit0_RepeatMessageRequestBit_1E384062 0;
BA_ "GenSigTimeoutTime_ESL" SG_ 2654486626 CBV_bit0_RepeatMessageRequestBit_1E384062 0;
BA_ "GenSigTimeoutTime_GNMM" SG_ 2654486626 CBV_bit0_RepeatMessageRequestBit_1E384062 0;
BA_ "GenSigTimeoutTime_HCP" SG_ 2654486626 CBV_bit0_RepeatMessageRequestBit_1E384062 0;
BA_ "GenSigTimeoutTime_IPC" SG_ 2654486626 CBV_bit0_RepeatMessageRequestBit_1E384062 0;
BA_ "GenSigTimeoutTime_RFHM" SG_ 2654486626 CBV_bit0_RepeatMessageRequestBit_1E384062 0;
BA_ "GenSigTimeoutTime_SGW" SG_ 2654486626 CBV_bit0_RepeatMessageRequestBit_1E384062 0;
BA_ "GenSigTimeoutTime_TCM" SG_ 2654486626 CBV_bit0_RepeatMessageRequestBit_1E384062 0;
BA_ "GenSigTimeoutTime_AGSM" SG_ 2654486626 CBV_bit1_1E384062 0;
BA_ "GenSigTimeoutTime_ASBS" SG_ 2654486626 CBV_bit1_1E384062 0;
BA_ "GenSigTimeoutTime_BCM" SG_ 2654486626 CBV_bit1_1E384062 0;
BA_ "GenSigTimeoutTime_BSM" SG_ 2654486626 CBV_bit1_1E384062 0;
BA_ "GenSigTimeoutTime_CADM" SG_ 2654486626 CBV_bit1_1E384062 0;
BA_ "GenSigTimeoutTime_DMSM" SG_ 2654486626 CBV_bit1_1E384062 0;
BA_ "GenSigTimeoutTime_DTCM" SG_ 2654486626 CBV_bit1_1E384062 0;
BA_ "GenSigTimeoutTime_ECM" SG_ 2654486626 CBV_bit1_1E384062 0;
BA_ "GenSigTimeoutTime_ELSDM" SG_ 2654486626 CBV_bit1_1E384062 0;
BA_ "GenSigTimeoutTime_ESL" SG_ 2654486626 CBV_bit1_1E384062 0;
BA_ "GenSigTimeoutTime_GNMM" SG_ 2654486626 CBV_bit1_1E384062 0;
BA_ "GenSigTimeoutTime_HCP" SG_ 2654486626 CBV_bit1_1E384062 0;
BA_ "GenSigTimeoutTime_IPC" SG_ 2654486626 CBV_bit1_1E384062 0;
BA_ "GenSigTimeoutTime_RFHM" SG_ 2654486626 CBV_bit1_1E384062 0;
BA_ "GenSigTimeoutTime_SGW" SG_ 2654486626 CBV_bit1_1E384062 0;
BA_ "GenSigTimeoutTime_TCM" SG_ 2654486626 CBV_bit1_1E384062 0;
BA_ "GenSigTimeoutTime_AGSM" SG_ 2654486626 CBV_bit2_1E384062 0;
BA_ "GenSigTimeoutTime_ASBS" SG_ 2654486626 CBV_bit2_1E384062 0;
BA_ "GenSigTimeoutTime_BCM" SG_ 2654486626 CBV_bit2_1E384062 0;
BA_ "GenSigTimeoutTime_BSM" SG_ 2654486626 CBV_bit2_1E384062 0;
BA_ "GenSigTimeoutTime_CADM" SG_ 2654486626 CBV_bit2_1E384062 0;
BA_ "GenSigTimeoutTime_DMSM" SG_ 2654486626 CBV_bit2_1E384062 0;
BA_ "GenSigTimeoutTime_DTCM" SG_ 2654486626 CBV_bit2_1E384062 0;
BA_ "GenSigTimeoutTime_ECM" SG_ 2654486626 CBV_bit2_1E384062 0;
BA_ "GenSigTimeoutTime_ELSDM" SG_ 2654486626 CBV_bit2_1E384062 0;
BA_ "GenSigTimeoutTime_ESL" SG_ 2654486626 CBV_bit2_1E384062 0;
BA_ "GenSigTimeoutTime_GNMM" SG_ 2654486626 CBV_bit2_1E384062 0;
BA_ "GenSigTimeoutTime_HCP" SG_ 2654486626 CBV_bit2_1E384062 0;
BA_ "GenSigTimeoutTime_IPC" SG_ 2654486626 CBV_bit2_1E384062 0;
BA_ "GenSigTimeoutTime_RFHM" SG_ 2654486626 CBV_bit2_1E384062 0;
BA_ "GenSigTimeoutTime_SGW" SG_ 2654486626 CBV_bit2_1E384062 0;
BA_ "GenSigTimeoutTime_TCM" SG_ 2654486626 CBV_bit2_1E384062 0;
BA_ "GenSigTimeoutTime_AGSM" SG_ 2654486626 CBV_bit3_NMCoordinatorBit_1E384062 0;
BA_ "GenSigTimeoutTime_ASBS" SG_ 2654486626 CBV_bit3_NMCoordinatorBit_1E384062 0;
BA_ "GenSigTimeoutTime_BCM" SG_ 2654486626 CBV_bit3_NMCoordinatorBit_1E384062 0;
BA_ "GenSigTimeoutTime_BSM" SG_ 2654486626 CBV_bit3_NMCoordinatorBit_1E384062 0;
BA_ "GenSigTimeoutTime_CADM" SG_ 2654486626 CBV_bit3_NMCoordinatorBit_1E384062 0;
BA_ "GenSigTimeoutTime_DMSM" SG_ 2654486626 CBV_bit3_NMCoordinatorBit_1E384062 0;
BA_ "GenSigTimeoutTime_DTCM" SG_ 2654486626 CBV_bit3_NMCoordinatorBit_1E384062 0;
BA_ "GenSigTimeoutTime_ECM" SG_ 2654486626 CBV_bit3_NMCoordinatorBit_1E384062 0;
BA_ "GenSigTimeoutTime_ELSDM" SG_ 2654486626 CBV_bit3_NMCoordinatorBit_1E384062 0;
BA_ "GenSigTimeoutTime_ESL" SG_ 2654486626 CBV_bit3_NMCoordinatorBit_1E384062 0;
BA_ "GenSigTimeoutTime_GNMM" SG_ 2654486626 CBV_bit3_NMCoordinatorBit_1E384062 0;
BA_ "GenSigTimeoutTime_HCP" SG_ 2654486626 CBV_bit3_NMCoordinatorBit_1E384062 0;
BA_ "GenSigTimeoutTime_IPC" SG_ 2654486626 CBV_bit3_NMCoordinatorBit_1E384062 0;
BA_ "GenSigTimeoutTime_RFHM" SG_ 2654486626 CBV_bit3_NMCoordinatorBit_1E384062 0;
BA_ "GenSigTimeoutTime_SGW" SG_ 2654486626 CBV_bit3_NMCoordinatorBit_1E384062 0;
BA_ "GenSigTimeoutTime_TCM" SG_ 2654486626 CBV_bit3_NMCoordinatorBit_1E384062 0;
BA_ "GenSigTimeoutTime_AGSM" SG_ 2654486626 CBV_bit4_ActiveWakeupBit_1E384062 0;
BA_ "GenSigTimeoutTime_ASBS" SG_ 2654486626 CBV_bit4_ActiveWakeupBit_1E384062 0;
BA_ "GenSigTimeoutTime_BCM" SG_ 2654486626 CBV_bit4_ActiveWakeupBit_1E384062 0;
BA_ "GenSigTimeoutTime_BSM" SG_ 2654486626 CBV_bit4_ActiveWakeupBit_1E384062 0;
BA_ "GenSigTimeoutTime_CADM" SG_ 2654486626 CBV_bit4_ActiveWakeupBit_1E384062 0;
BA_ "GenSigTimeoutTime_DMSM" SG_ 2654486626 CBV_bit4_ActiveWakeupBit_1E384062 0;
BA_ "GenSigTimeoutTime_DTCM" SG_ 2654486626 CBV_bit4_ActiveWakeupBit_1E384062 0;
BA_ "GenSigTimeoutTime_ECM" SG_ 2654486626 CBV_bit4_ActiveWakeupBit_1E384062 0;
BA_ "GenSigTimeoutTime_ADCAM" SG_ 2654486529 CBV_bit0_RepeatMessageRequestBit_1E384001 0;
BA_ "GenSigTimeoutTime_EVCU2" SG_ 2654486529 CBV_bit0_RepeatMessageRequestBit_1E384001 0;
BA_ "GenSigTimeoutTime_VDCM" SG_ 2654486529 CBV_bit0_RepeatMessageRequestBit_1E384001 0;
BA_ "GenSigTimeoutTime_ADCAM" SG_ 2654486529 CBV_bit1_1E384001 0;
BA_ "GenSigTimeoutTime_EVCU2" SG_ 2654486529 CBV_bit1_1E384001 0;
BA_ "GenSigTimeoutTime_VDCM" SG_ 2654486529 CBV_bit1_1E384001 0;
BA_ "GenSigTimeoutTime_ADCAM" SG_ 2654486529 CBV_bit2_1E384001 0;
BA_ "GenSigTimeoutTime_EVCU2" SG_ 2654486529 CBV_bit2_1E384001 0;
BA_ "GenSigTimeoutTime_VDCM" SG_ 2654486529 CBV_bit2_1E384001 0;
BA_ "GenSigTimeoutTime_ADCAM" SG_ 2654486529 CBV_bit3_NMCoordinatorBit_1E384001 0;
BA_ "GenSigTimeoutTime_EVCU2" SG_ 2654486529 CBV_bit3_NMCoordinatorBit_1E384001 0;
BA_ "GenSigTimeoutTime_VDCM" SG_ 2654486529 CBV_bit3_NMCoordinatorBit_1E384001 0;
BA_ "GenSigTimeoutTime_ADCAM" SG_ 2654486529 CBV_bit4_ActiveWakeupBit_1E384001 0;
BA_ "GenSigTimeoutTime_EVCU2" SG_ 2654486529 CBV_bit4_ActiveWakeupBit_1E384001 0;
BA_ "GenSigTimeoutTime_VDCM" SG_ 2654486529 CBV_bit4_ActiveWakeupBit_1E384001 0;
BA_ "GenSigTimeoutTime_ADCAM" SG_ 2654486529 CBV_bit5_1E384001 0;
BA_ "GenSigTimeoutTime_EVCU2" SG_ 2654486529 CBV_bit5_1E384001 0;
BA_ "GenSigTimeoutTime_VDCM" SG_ 2654486529 CBV_bit5_1E384001 0;
BA_ "GenSigTimeoutTime_ADCAM" SG_ 2654486529 CBV_bit6_PartialNtwInfBit_1E384001 0;
BA_ "GenSigTimeoutTime_EVCU2" SG_ 2654486529 CBV_bit6_PartialNtwInfBit_1E384001 0;
BA_ "GenSigTimeoutTime_VDCM" SG_ 2654486529 CBV_bit6_PartialNtwInfBit_1E384001 0;
BA_ "GenSigTimeoutTime_ADCAM" SG_ 2654486529 CBV_bit7_1E384001 0;
BA_ "GenSigTimeoutTime_EVCU2" SG_ 2654486529 CBV_bit7_1E384001 0;
BA_ "GenSigTimeoutTime_VDCM" SG_ 2654486529 CBV_bit7_1E384001 0;
BA_ "GenSigTimeoutTime_ADCAM" SG_ 2654486529 SourceNodeIdentifier_1E384001 0;
BA_ "GenSigTimeoutTime_EVCU2" SG_ 2654486529 SourceNodeIdentifier_1E384001 0;
BA_ "GenSigTimeoutTime_VDCM" SG_ 2654486529 SourceNodeIdentifier_1E384001 0;
BA_ "GenSigTimeoutTime_AGSM" SG_ 2654486529 CBV_bit0_RepeatMessageRequestBit_1E384001 0;
BA_ "GenSigTimeoutTime_ASBS" SG_ 2654486529 CBV_bit0_RepeatMessageRequestBit_1E384001 0;
BA_ "GenSigTimeoutTime_BCM" SG_ 2654486529 CBV_bit0_RepeatMessageRequestBit_1E384001 0;
BA_ "GenSigTimeoutTime_BSM" SG_ 2654486529 CBV_bit0_RepeatMessageRequestBit_1E384001 0;
BA_ "GenSigTimeoutTime_CADM" SG_ 2654486529 CBV_bit0_RepeatMessageRequestBit_1E384001 0;
BA_ "GenSigTimeoutTime_DMSM" SG_ 2654486529 CBV_bit0_RepeatMessageRequestBit_1E384001 0;
BA_ "GenSigTimeoutTime_DTCM" SG_ 2654486529 CBV_bit0_RepeatMessageRequestBit_1E384001 0;
BA_ "GenSigTimeoutTime_ECM" SG_ 2654486529 CBV_bit0_RepeatMessageRequestBit_1E384001 0;
BA_ "GenSigTimeoutTime_ELSDM" SG_ 2654486529 CBV_bit0_RepeatMessageRequestBit_1E384001 0;
BA_ "GenSigTimeoutTime_ESL" SG_ 2654486529 CBV_bit0_RepeatMessageRequestBit_1E384001 0;
BA_ "GenSigTimeoutTime_GNMM" SG_ 2654486529 CBV_bit0_RepeatMessageRequestBit_1E384001 0;
BA_ "GenSigTimeoutTime_HCP" SG_ 2654486529 CBV_bit0_RepeatMessageRequestBit_1E384001 0;
BA_ "GenSigTimeoutTime_IPC" SG_ 2654486529 CBV_bit0_RepeatMessageRequestBit_1E384001 0;
BA_ "GenSigTimeoutTime_RFHM" SG_ 2654486529 CBV_bit0_RepeatMessageRequestBit_1E384001 0;
BA_ "GenSigTimeoutTime_SGW" SG_ 2654486529 CBV_bit0_RepeatMessageRequestBit_1E384001 0;
BA_ "GenSigTimeoutTime_TCM" SG_ 2654486529 CBV_bit0_RepeatMessageRequestBit_1E384001 0;
BA_ "GenSigTimeoutTime_AGSM" SG_ 2654486529 CBV_bit1_1E384001 0;
BA_ "GenSigTimeoutTime_ASBS" SG_ 2654486529 CBV_bit1_1E384001 0;
BA_ "GenSigTimeoutTime_BCM" SG_ 2654486529 CBV_bit1_1E384001 0;
BA_ "GenSigTimeoutTime_BSM" SG_ 2654486529 CBV_bit1_1E384001 0;
BA_ "GenSigTimeoutTime_CADM" SG_ 2654486529 CBV_bit1_1E384001 0;
BA_ "GenSigTimeoutTime_DMSM" SG_ 2654486529 CBV_bit1_1E384001 0;
BA_ "GenSigTimeoutTime_DTCM" SG_ 2654486529 CBV_bit1_1E384001 0;
BA_ "GenSigTimeoutTime_ECM" SG_ 2654486529 CBV_bit1_1E384001 0;
BA_ "GenSigTimeoutTime_ELSDM" SG_ 2654486529 CBV_bit1_1E384001 0;
BA_ "GenSigTimeoutTime_ESL" SG_ 2654486529 CBV_bit1_1E384001 0;
BA_ "GenSigTimeoutTime_GNMM" SG_ 2654486529 CBV_bit1_1E384001 0;
BA_ "GenSigTimeoutTime_HCP" SG_ 2654486529 CBV_bit1_1E384001 0;
BA_ "GenSigTimeoutTime_IPC" SG_ 2654486529 CBV_bit1_1E384001 0;
BA_ "GenSigTimeoutTime_RFHM" SG_ 2654486529 CBV_bit1_1E384001 0;
BA_ "GenSigTimeoutTime_SGW" SG_ 2654486529 CBV_bit1_1E384001 0;
BA_ "GenSigTimeoutTime_TCM" SG_ 2654486529 CBV_bit1_1E384001 0;
BA_ "GenSigTimeoutTime_AGSM" SG_ 2654486529 CBV_bit2_1E384001 0;
BA_ "GenSigTimeoutTime_ASBS" SG_ 2654486529 CBV_bit2_1E384001 0;
BA_ "GenSigTimeoutTime_BCM" SG_ 2654486529 CBV_bit2_1E384001 0;
BA_ "GenSigTimeoutTime_BSM" SG_ 2654486529 CBV_bit2_1E384001 0;
BA_ "GenSigTimeoutTime_CADM" SG_ 2654486529 CBV_bit2_1E384001 0;
BA_ "GenSigTimeoutTime_DMSM" SG_ 2654486529 CBV_bit2_1E384001 0;
BA_ "GenSigTimeoutTime_DTCM" SG_ 2654486529 CBV_bit2_1E384001 0;
BA_ "GenSigTimeoutTime_ECM" SG_ 2654486529 CBV_bit2_1E384001 0;
BA_ "GenSigTimeoutTime_ELSDM" SG_ 2654486529 CBV_bit2_1E384001 0;
BA_ "GenSigTimeoutTime_ESL" SG_ 2654486529 CBV_bit2_1E384001 0;
BA_ "GenSigTimeoutTime_GNMM" SG_ 2654486529 CBV_bit2_1E384001 0;
BA_ "GenSigTimeoutTime_HCP" SG_ 2654486529 CBV_bit2_1E384001 0;
BA_ "GenSigTimeoutTime_IPC" SG_ 2654486529 CBV_bit2_1E384001 0;
BA_ "GenSigTimeoutTime_RFHM" SG_ 2654486529 CBV_bit2_1E384001 0;
BA_ "GenSigTimeoutTime_SGW" SG_ 2654486529 CBV_bit2_1E384001 0;
BA_ "GenSigTimeoutTime_TCM" SG_ 2654486529 CBV_bit2_1E384001 0;
BA_ "GenSigTimeoutTime_AGSM" SG_ 2654486529 CBV_bit3_NMCoordinatorBit_1E384001 0;
BA_ "GenSigTimeoutTime_ASBS" SG_ 2654486529 CBV_bit3_NMCoordinatorBit_1E384001 0;
BA_ "GenSigTimeoutTime_BCM" SG_ 2654486529 CBV_bit3_NMCoordinatorBit_1E384001 0;
BA_ "GenSigTimeoutTime_BSM" SG_ 2654486529 CBV_bit3_NMCoordinatorBit_1E384001 0;
BA_ "GenSigTimeoutTime_CADM" SG_ 2654486529 CBV_bit3_NMCoordinatorBit_1E384001 0;
BA_ "GenSigTimeoutTime_DMSM" SG_ 2654486529 CBV_bit3_NMCoordinatorBit_1E384001 0;
BA_ "GenSigTimeoutTime_DTCM" SG_ 2654486529 CBV_bit3_NMCoordinatorBit_1E384001 0;
BA_ "GenSigTimeoutTime_ECM" SG_ 2654486529 CBV_bit3_NMCoordinatorBit_1E384001 0;
BA_ "GenSigTimeoutTime_ELSDM" SG_ 2654486529 CBV_bit3_NMCoordinatorBit_1E384001 0;
BA_ "GenSigTimeoutTime_ESL" SG_ 2654486529 CBV_bit3_NMCoordinatorBit_1E384001 0;
BA_ "GenSigTimeoutTime_GNMM" SG_ 2654486529 CBV_bit3_NMCoordinatorBit_1E384001 0;
BA_ "GenSigTimeoutTime_HCP" SG_ 2654486529 CBV_bit3_NMCoordinatorBit_1E384001 0;
BA_ "GenSigTimeoutTime_IPC" SG_ 2654486529 CBV_bit3_NMCoordinatorBit_1E384001 0;
BA_ "GenSigTimeoutTime_RFHM" SG_ 2654486529 CBV_bit3_NMCoordinatorBit_1E384001 0;
BA_ "GenSigTimeoutTime_SGW" SG_ 2654486529 CBV_bit3_NMCoordinatorBit_1E384001 0;
BA_ "GenSigTimeoutTime_TCM" SG_ 2654486529 CBV_bit3_NMCoordinatorBit_1E384001 0;
BA_ "GenSigTimeoutTime_AGSM" SG_ 2654486529 CBV_bit4_ActiveWakeupBit_1E384001 0;
BA_ "GenSigTimeoutTime_ASBS" SG_ 2654486529 CBV_bit4_ActiveWakeupBit_1E384001 0;
BA_ "GenSigTimeoutTime_BCM" SG_ 2654486529 CBV_bit4_ActiveWakeupBit_1E384001 0;
BA_ "GenSigTimeoutTime_BSM" SG_ 2654486529 CBV_bit4_ActiveWakeupBit_1E384001 0;
BA_ "GenSigTimeoutTime_CADM" SG_ 2654486529 CBV_bit4_ActiveWakeupBit_1E384001 0;
BA_ "GenSigTimeoutTime_DMSM" SG_ 2654486529 CBV_bit4_ActiveWakeupBit_1E384001 0;
BA_ "GenSigTimeoutTime_DTCM" SG_ 2654486529 CBV_bit4_ActiveWakeupBit_1E384001 0;
BA_ "GenSigTimeoutTime_ECM" SG_ 2654486529 CBV_bit4_ActiveWakeupBit_1E384001 0;
BA_ "GenSigTimeoutTime_ELSDM" SG_ 2654486529 CBV_bit4_ActiveWakeupBit_1E384001 0;
BA_ "GenSigTimeoutTime_ESL" SG_ 2654486529 CBV_bit4_ActiveWakeupBit_1E384001 0;
BA_ "GenSigTimeoutTime_GNMM" SG_ 2654486529 CBV_bit4_ActiveWakeupBit_1E384001 0;
BA_ "GenSigTimeoutTime_HCP" SG_ 2654486529 CBV_bit4_ActiveWakeupBit_1E384001 0;
BA_ "GenSigTimeoutTime_IPC" SG_ 2654486529 CBV_bit4_ActiveWakeupBit_1E384001 0;
BA_ "GenSigTimeoutTime_RFHM" SG_ 2654486529 CBV_bit4_ActiveWakeupBit_1E384001 0;
BA_ "GenSigTimeoutTime_SGW" SG_ 2654486529 CBV_bit4_ActiveWakeupBit_1E384001 0;
BA_ "GenSigTimeoutTime_TCM" SG_ 2654486529 CBV_bit4_ActiveWakeupBit_1E384001 0;
BA_ "GenSigTimeoutTime_AGSM" SG_ 2654486529 CBV_bit5_1E384001 0;
BA_ "GenSigTimeoutTime_ASBS" SG_ 2654486529 CBV_bit5_1E384001 0;
BA_ "GenSigTimeoutTime_BCM" SG_ 2654486529 CBV_bit5_1E384001 0;
BA_ "GenSigTimeoutTime_BSM" SG_ 2654486529 CBV_bit5_1E384001 0;
BA_ "GenSigTimeoutTime_CADM" SG_ 2654486529 CBV_bit5_1E384001 0;
BA_ "GenSigTimeoutTime_DMSM" SG_ 2654486529 CBV_bit5_1E384001 0;
BA_ "GenSigTimeoutTime_DTCM" SG_ 2654486529 CBV_bit5_1E384001 0;
BA_ "GenSigTimeoutTime_ECM" SG_ 2654486529 CBV_bit5_1E384001 0;
BA_ "GenSigTimeoutTime_ELSDM" SG_ 2654486529 CBV_bit5_1E384001 0;
BA_ "GenSigTimeoutTime_ESL" SG_ 2654486529 CBV_bit5_1E384001 0;
BA_ "GenSigTimeoutTime_GNMM" SG_ 2654486529 CBV_bit5_1E384001 0;
BA_ "GenSigTimeoutTime_HCP" SG_ 2654486529 CBV_bit5_1E384001 0;
BA_ "GenSigTimeoutTime_IPC" SG_ 2654486529 CBV_bit5_1E384001 0;
BA_ "GenSigTimeoutTime_RFHM" SG_ 2654486529 CBV_bit5_1E384001 0;
BA_ "GenSigTimeoutTime_SGW" SG_ 2654486529 CBV_bit5_1E384001 0;
BA_ "GenSigTimeoutTime_TCM" SG_ 2654486529 CBV_bit5_1E384001 0;
BA_ "GenSigTimeoutTime_AGSM" SG_ 2654486529 CBV_bit6_PartialNtwInfBit_1E384001 0;
BA_ "GenSigTimeoutTime_ASBS" SG_ 2654486529 CBV_bit6_PartialNtwInfBit_1E384001 0;
BA_ "GenSigTimeoutTime_BCM" SG_ 2654486529 CBV_bit6_PartialNtwInfBit_1E384001 0;
BA_ "GenSigTimeoutTime_BSM" SG_ 2654486529 CBV_bit6_PartialNtwInfBit_1E384001 0;
BA_ "GenSigTimeoutTime_CADM" SG_ 2654486529 CBV_bit6_PartialNtwInfBit_1E384001 0;
BA_ "GenSigTimeoutTime_DMSM" SG_ 2654486529 CBV_bit6_PartialNtwInfBit_1E384001 0;
BA_ "GenSigTimeoutTime_DTCM" SG_ 2654486529 CBV_bit6_PartialNtwInfBit_1E384001 0;
BA_ "GenSigTimeoutTime_ECM" SG_ 2654486529 CBV_bit6_PartialNtwInfBit_1E384001 0;
BA_ "GenSigTimeoutTime_ELSDM" SG_ 2654486529 CBV_bit6_PartialNtwInfBit_1E384001 0;
BA_ "GenSigTimeoutTime_ESL" SG_ 2654486529 CBV_bit6_PartialNtwInfBit_1E384001 0;
BA_ "GenSigTimeoutTime_GNMM" SG_ 2654486529 CBV_bit6_PartialNtwInfBit_1E384001 0;
BA_ "GenSigTimeoutTime_HCP" SG_ 2654486529 CBV_bit6_PartialNtwInfBit_1E384001 0;
BA_ "GenSigTimeoutTime_IPC" SG_ 2654486529 CBV_bit6_PartialNtwInfBit_1E384001 0;
BA_ "GenSigTimeoutTime_RFHM" SG_ 2654486529 CBV_bit6_PartialNtwInfBit_1E384001 0;
BA_ "GenSigTimeoutTime_SGW" SG_ 2654486529 CBV_bit6_PartialNtwInfBit_1E384001 0;
BA_ "GenSigTimeoutTime_TCM" SG_ 2654486529 CBV_bit6_PartialNtwInfBit_1E384001 0;
BA_ "GenSigTimeoutTime_AGSM" SG_ 2654486529 CBV_bit7_1E384001 0;
BA_ "GenSigTimeoutTime_ASBS" SG_ 2654486529 CBV_bit7_1E384001 0;
BA_ "GenSigTimeoutTime_BCM" SG_ 2654486529 CBV_bit7_1E384001 0;
BA_ "GenSigTimeoutTime_BSM" SG_ 2654486529 CBV_bit7_1E384001 0;
BA_ "GenSigTimeoutTime_CADM" SG_ 2654486529 CBV_bit7_1E384001 0;
BA_ "GenSigTimeoutTime_DMSM" SG_ 2654486529 CBV_bit7_1E384001 0;
BA_ "GenSigTimeoutTime_DTCM" SG_ 2654486529 CBV_bit7_1E384001 0;
BA_ "GenSigTimeoutTime_ECM" SG_ 2654486529 CBV_bit7_1E384001 0;
BA_ "GenSigTimeoutTime_ELSDM" SG_ 2654486529 CBV_bit7_1E384001 0;
BA_ "GenSigTimeoutTime_ESL" SG_ 2654486529 CBV_bit7_1E384001 0;
BA_ "GenSigTimeoutTime_GNMM" SG_ 2654486529 CBV_bit7_1E384001 0;
BA_ "GenSigTimeoutTime_HCP" SG_ 2654486529 CBV_bit7_1E384001 0;
BA_ "GenSigTimeoutTime_IPC" SG_ 2654486529 CBV_bit7_1E384001 0;
BA_ "GenSigTimeoutTime_RFHM" SG_ 2654486529 CBV_bit7_1E384001 0;
BA_ "GenSigTimeoutTime_SGW" SG_ 2654486529 CBV_bit7_1E384001 0;
BA_ "GenSigTimeoutTime_TCM" SG_ 2654486529 CBV_bit7_1E384001 0;
BA_ "GenSigTimeoutTime_AGSM" SG_ 2654486529 SourceNodeIdentifier_1E384001 0;
BA_ "GenSigTimeoutTime_ASBS" SG_ 2654486529 SourceNodeIdentifier_1E384001 0;
BA_ "GenSigTimeoutTime_BCM" SG_ 2654486529 SourceNodeIdentifier_1E384001 0;
BA_ "GenSigTimeoutTime_BSM" SG_ 2654486529 SourceNodeIdentifier_1E384001 0;
BA_ "GenSigTimeoutTime_CADM" SG_ 2654486529 SourceNodeIdentifier_1E384001 0;
BA_ "GenSigTimeoutTime_DMSM" SG_ 2654486529 SourceNodeIdentifier_1E384001 0;
BA_ "GenSigTimeoutTime_DTCM" SG_ 2654486529 SourceNodeIdentifier_1E384001 0;
BA_ "GenSigTimeoutTime_ECM" SG_ 2654486529 SourceNodeIdentifier_1E384001 0;
BA_ "GenSigTimeoutTime_ELSDM" SG_ 2654486529 SourceNodeIdentifier_1E384001 0;
BA_ "GenSigTimeoutTime_ESL" SG_ 2654486529 SourceNodeIdentifier_1E384001 0;
BA_ "GenSigTimeoutTime_GNMM" SG_ 2654486529 SourceNodeIdentifier_1E384001 0;
BA_ "GenSigTimeoutTime_HCP" SG_ 2654486529 SourceNodeIdentifier_1E384001 0;
BA_ "GenSigTimeoutTime_IPC" SG_ 2654486529 SourceNodeIdentifier_1E384001 0;
BA_ "GenSigTimeoutTime_RFHM" SG_ 2654486529 SourceNodeIdentifier_1E384001 0;
BA_ "GenSigTimeoutTime_SGW" SG_ 2654486529 SourceNodeIdentifier_1E384001 0;
BA_ "GenSigTimeoutTime_TCM" SG_ 2654486529 SourceNodeIdentifier_1E384001 0;
BA_ "GenSigTimeoutTime_ELSDM" SG_ 2654486626 CBV_bit4_ActiveWakeupBit_1E384062 0;
BA_ "GenSigTimeoutTime_ESL" SG_ 2654486626 CBV_bit4_ActiveWakeupBit_1E384062 0;
BA_ "GenSigTimeoutTime_GNMM" SG_ 2654486626 CBV_bit4_ActiveWakeupBit_1E384062 0;
BA_ "GenSigTimeoutTime_HCP" SG_ 2654486626 CBV_bit4_ActiveWakeupBit_1E384062 0;
BA_ "GenSigTimeoutTime_IPC" SG_ 2654486626 CBV_bit4_ActiveWakeupBit_1E384062 0;
BA_ "GenSigTimeoutTime_RFHM" SG_ 2654486626 CBV_bit4_ActiveWakeupBit_1E384062 0;
BA_ "GenSigTimeoutTime_SGW" SG_ 2654486626 CBV_bit4_ActiveWakeupBit_1E384062 0;
BA_ "GenSigTimeoutTime_TCM" SG_ 2654486626 CBV_bit4_ActiveWakeupBit_1E384062 0;
BA_ "GenSigTimeoutTime_AGSM" SG_ 2654486626 CBV_bit5_1E384062 0;
BA_ "GenSigTimeoutTime_ASBS" SG_ 2654486626 CBV_bit5_1E384062 0;
BA_ "GenSigTimeoutTime_BCM" SG_ 2654486626 CBV_bit5_1E384062 0;
BA_ "GenSigTimeoutTime_BSM" SG_ 2654486626 CBV_bit5_1E384062 0;
BA_ "GenSigTimeoutTime_CADM" SG_ 2654486626 CBV_bit5_1E384062 0;
BA_ "GenSigTimeoutTime_DMSM" SG_ 2654486626 CBV_bit5_1E384062 0;
BA_ "GenSigTimeoutTime_DTCM" SG_ 2654486626 CBV_bit5_1E384062 0;
BA_ "GenSigTimeoutTime_ECM" SG_ 2654486626 CBV_bit5_1E384062 0;
BA_ "GenSigTimeoutTime_ELSDM" SG_ 2654486626 CBV_bit5_1E384062 0;
BA_ "GenSigTimeoutTime_ESL" SG_ 2654486626 CBV_bit5_1E384062 0;
BA_ "GenSigTimeoutTime_GNMM" SG_ 2654486626 CBV_bit5_1E384062 0;
BA_ "GenSigTimeoutTime_HCP" SG_ 2654486626 CBV_bit5_1E384062 0;
BA_ "GenSigTimeoutTime_IPC" SG_ 2654486626 CBV_bit5_1E384062 0;
BA_ "GenSigTimeoutTime_RFHM" SG_ 2654486626 CBV_bit5_1E384062 0;
BA_ "GenSigTimeoutTime_SGW" SG_ 2654486626 CBV_bit5_1E384062 0;
BA_ "GenSigTimeoutTime_TCM" SG_ 2654486626 CBV_bit5_1E384062 0;
BA_ "GenSigTimeoutTime_AGSM" SG_ 2654486626 CBV_bit6_PartialNtwInfBit_1E384062 0;
BA_ "GenSigTimeoutTime_ASBS" SG_ 2654486626 CBV_bit6_PartialNtwInfBit_1E384062 0;
BA_ "GenSigTimeoutTime_BCM" SG_ 2654486626 CBV_bit6_PartialNtwInfBit_1E384062 0;
BA_ "GenSigTimeoutTime_BSM" SG_ 2654486626 CBV_bit6_PartialNtwInfBit_1E384062 0;
BA_ "GenSigTimeoutTime_CADM" SG_ 2654486626 CBV_bit6_PartialNtwInfBit_1E384062 0;
BA_ "GenSigTimeoutTime_DMSM" SG_ 2654486626 CBV_bit6_PartialNtwInfBit_1E384062 0;
BA_ "GenSigTimeoutTime_DTCM" SG_ 2654486626 CBV_bit6_PartialNtwInfBit_1E384062 0;
BA_ "GenSigTimeoutTime_ECM" SG_ 2654486626 CBV_bit6_PartialNtwInfBit_1E384062 0;
BA_ "GenSigTimeoutTime_ELSDM" SG_ 2654486626 CBV_bit6_PartialNtwInfBit_1E384062 0;
BA_ "GenSigTimeoutTime_ESL" SG_ 2654486626 CBV_bit6_PartialNtwInfBit_1E384062 0;
BA_ "GenSigTimeoutTime_GNMM" SG_ 2654486626 CBV_bit6_PartialNtwInfBit_1E384062 0;
BA_ "GenSigTimeoutTime_HCP" SG_ 2654486626 CBV_bit6_PartialNtwInfBit_1E384062 0;
BA_ "GenSigTimeoutTime_IPC" SG_ 2654486626 CBV_bit6_PartialNtwInfBit_1E384062 0;
BA_ "GenSigTimeoutTime_RFHM" SG_ 2654486626 CBV_bit6_PartialNtwInfBit_1E384062 0;
BA_ "GenSigTimeoutTime_SGW" SG_ 2654486626 CBV_bit6_PartialNtwInfBit_1E384062 0;
BA_ "GenSigTimeoutTime_TCM" SG_ 2654486626 CBV_bit6_PartialNtwInfBit_1E384062 0;
BA_ "GenSigTimeoutTime_AGSM" SG_ 2654486626 CBV_bit7_1E384062 0;
BA_ "GenSigTimeoutTime_ASBS" SG_ 2654486626 CBV_bit7_1E384062 0;
BA_ "GenSigTimeoutTime_BCM" SG_ 2654486626 CBV_bit7_1E384062 0;
BA_ "GenSigTimeoutTime_BSM" SG_ 2654486626 CBV_bit7_1E384062 0;
BA_ "GenSigTimeoutTime_CADM" SG_ 2654486626 CBV_bit7_1E384062 0;
BA_ "GenSigTimeoutTime_DMSM" SG_ 2654486626 CBV_bit7_1E384062 0;
BA_ "GenSigTimeoutTime_DTCM" SG_ 2654486626 CBV_bit7_1E384062 0;
BA_ "GenSigTimeoutTime_ECM" SG_ 2654486626 CBV_bit7_1E384062 0;
BA_ "GenSigTimeoutTime_ELSDM" SG_ 2654486626 CBV_bit7_1E384062 0;
BA_ "GenSigTimeoutTime_ESL" SG_ 2654486626 CBV_bit7_1E384062 0;
BA_ "GenSigTimeoutTime_GNMM" SG_ 2654486626 CBV_bit7_1E384062 0;
BA_ "GenSigTimeoutTime_HCP" SG_ 2654486626 CBV_bit7_1E384062 0;
BA_ "GenSigTimeoutTime_IPC" SG_ 2654486626 CBV_bit7_1E384062 0;
BA_ "GenSigTimeoutTime_RFHM" SG_ 2654486626 CBV_bit7_1E384062 0;
BA_ "GenSigTimeoutTime_SGW" SG_ 2654486626 CBV_bit7_1E384062 0;
BA_ "GenSigTimeoutTime_TCM" SG_ 2654486626 CBV_bit7_1E384062 0;
BA_ "GenSigTimeoutTime_AGSM" SG_ 2654486626 SourceNodeIdentifier_1E384062 0;
BA_ "GenSigTimeoutTime_ASBS" SG_ 2654486626 SourceNodeIdentifier_1E384062 0;
BA_ "GenSigTimeoutTime_BCM" SG_ 2654486626 SourceNodeIdentifier_1E384062 0;
BA_ "GenSigTimeoutTime_BSM" SG_ 2654486626 SourceNodeIdentifier_1E384062 0;
BA_ "GenSigTimeoutTime_CADM" SG_ 2654486626 SourceNodeIdentifier_1E384062 0;
BA_ "GenSigTimeoutTime_DMSM" SG_ 2654486626 SourceNodeIdentifier_1E384062 0;
BA_ "GenSigTimeoutTime_DTCM" SG_ 2654486626 SourceNodeIdentifier_1E384062 0;
BA_ "GenSigTimeoutTime_ECM" SG_ 2654486626 SourceNodeIdentifier_1E384062 0;
BA_ "GenSigTimeoutTime_ELSDM" SG_ 2654486626 SourceNodeIdentifier_1E384062 0;
BA_ "GenSigTimeoutTime_ESL" SG_ 2654486626 SourceNodeIdentifier_1E384062 0;
BA_ "GenSigTimeoutTime_GNMM" SG_ 2654486626 SourceNodeIdentifier_1E384062 0;
BA_ "GenSigTimeoutTime_HCP" SG_ 2654486626 SourceNodeIdentifier_1E384062 0;
BA_ "GenSigTimeoutTime_IPC" SG_ 2654486626 SourceNodeIdentifier_1E384062 0;
BA_ "GenSigTimeoutTime_RFHM" SG_ 2654486626 SourceNodeIdentifier_1E384062 0;
BA_ "GenSigTimeoutTime_SGW" SG_ 2654486626 SourceNodeIdentifier_1E384062 0;
BA_ "GenSigTimeoutTime_TCM" SG_ 2654486626 SourceNodeIdentifier_1E384062 0;
BA_ "GenSigTimeoutTime_ADCAM" SG_ 2654486531 CBV_bit0_RepeatMessageRequestBit_1E384003 0;
BA_ "GenSigTimeoutTime_EVCU2" SG_ 2654486531 CBV_bit0_RepeatMessageRequestBit_1E384003 0;
BA_ "GenSigTimeoutTime_VDCM" SG_ 2654486531 CBV_bit0_RepeatMessageRequestBit_1E384003 0;
BA_ "GenSigTimeoutTime_ADCAM" SG_ 2654486531 CBV_bit1_1E384003 0;
BA_ "GenSigTimeoutTime_EVCU2" SG_ 2654486531 CBV_bit1_1E384003 0;
BA_ "GenSigTimeoutTime_VDCM" SG_ 2654486531 CBV_bit1_1E384003 0;
BA_ "GenSigTimeoutTime_ADCAM" SG_ 2654486531 CBV_bit2_1E384003 0;
BA_ "GenSigTimeoutTime_EVCU2" SG_ 2654486531 CBV_bit2_1E384003 0;
BA_ "GenSigTimeoutTime_VDCM" SG_ 2654486531 CBV_bit2_1E384003 0;
BA_ "GenSigTimeoutTime_ADCAM" SG_ 2654486531 CBV_bit3_NMCoordinatorBit_1E384003 0;
BA_ "GenSigTimeoutTime_EVCU2" SG_ 2654486531 CBV_bit3_NMCoordinatorBit_1E384003 0;
BA_ "GenSigTimeoutTime_VDCM" SG_ 2654486531 CBV_bit3_NMCoordinatorBit_1E384003 0;
BA_ "GenSigTimeoutTime_ADCAM" SG_ 2654486531 CBV_bit4_ActiveWakeupBit_1E384003 0;
BA_ "GenSigTimeoutTime_EVCU2" SG_ 2654486531 CBV_bit4_ActiveWakeupBit_1E384003 0;
BA_ "GenSigTimeoutTime_VDCM" SG_ 2654486531 CBV_bit4_ActiveWakeupBit_1E384003 0;
BA_ "GenSigTimeoutTime_ADCAM" SG_ 2654486531 CBV_bit5_1E384003 0;
BA_ "GenSigTimeoutTime_EVCU2" SG_ 2654486531 CBV_bit5_1E384003 0;
BA_ "GenSigTimeoutTime_VDCM" SG_ 2654486531 CBV_bit5_1E384003 0;
BA_ "GenSigTimeoutTime_ADCAM" SG_ 2654486531 CBV_bit6_PartialNtwInfBit_1E384003 0;
BA_ "GenSigTimeoutTime_EVCU2" SG_ 2654486531 CBV_bit6_PartialNtwInfBit_1E384003 0;
BA_ "GenSigTimeoutTime_VDCM" SG_ 2654486531 CBV_bit6_PartialNtwInfBit_1E384003 0;
BA_ "GenSigTimeoutTime_ADCAM" SG_ 2654486531 CBV_bit7_1E384003 0;
BA_ "GenSigTimeoutTime_EVCU2" SG_ 2654486531 CBV_bit7_1E384003 0;
BA_ "GenSigTimeoutTime_VDCM" SG_ 2654486531 CBV_bit7_1E384003 0;
BA_ "GenSigTimeoutTime_ADCAM" SG_ 2654486531 SourceNodeIdentifier_1E384003 0;
BA_ "GenSigTimeoutTime_EVCU2" SG_ 2654486531 SourceNodeIdentifier_1E384003 0;
BA_ "GenSigTimeoutTime_VDCM" SG_ 2654486531 SourceNodeIdentifier_1E384003 0;
BA_ "GenSigTimeoutTime_AGSM" SG_ 2654486531 CBV_bit0_RepeatMessageRequestBit_1E384003 0;
BA_ "GenSigTimeoutTime_ASBS" SG_ 2654486531 CBV_bit0_RepeatMessageRequestBit_1E384003 0;
BA_ "GenSigTimeoutTime_BCM" SG_ 2654486531 CBV_bit0_RepeatMessageRequestBit_1E384003 0;
BA_ "GenSigTimeoutTime_BSM" SG_ 2654486531 CBV_bit0_RepeatMessageRequestBit_1E384003 0;
BA_ "GenSigTimeoutTime_CADM" SG_ 2654486531 CBV_bit0_RepeatMessageRequestBit_1E384003 0;
BA_ "GenSigTimeoutTime_DMSM" SG_ 2654486531 CBV_bit0_RepeatMessageRequestBit_1E384003 0;
BA_ "GenSigTimeoutTime_DTCM" SG_ 2654486531 CBV_bit0_RepeatMessageRequestBit_1E384003 0;
BA_ "GenSigTimeoutTime_ECM" SG_ 2654486531 CBV_bit0_RepeatMessageRequestBit_1E384003 0;
BA_ "GenSigTimeoutTime_ELSDM" SG_ 2654486531 CBV_bit0_RepeatMessageRequestBit_1E384003 0;
BA_ "GenSigTimeoutTime_ESL" SG_ 2654486531 CBV_bit0_RepeatMessageRequestBit_1E384003 0;
BA_ "GenSigTimeoutTime_GNMM" SG_ 2654486531 CBV_bit0_RepeatMessageRequestBit_1E384003 0;
BA_ "GenSigTimeoutTime_HCP" SG_ 2654486531 CBV_bit0_RepeatMessageRequestBit_1E384003 0;
BA_ "GenSigTimeoutTime_IPC" SG_ 2654486531 CBV_bit0_RepeatMessageRequestBit_1E384003 0;
BA_ "GenSigTimeoutTime_RFHM" SG_ 2654486531 CBV_bit0_RepeatMessageRequestBit_1E384003 0;
BA_ "GenSigTimeoutTime_SGW" SG_ 2654486531 CBV_bit0_RepeatMessageRequestBit_1E384003 0;
BA_ "GenSigTimeoutTime_TCM" SG_ 2654486531 CBV_bit0_RepeatMessageRequestBit_1E384003 0;
BA_ "GenSigTimeoutTime_AGSM" SG_ 2654486531 CBV_bit1_1E384003 0;
BA_ "GenSigTimeoutTime_ASBS" SG_ 2654486531 CBV_bit1_1E384003 0;
BA_ "GenSigTimeoutTime_BCM" SG_ 2654486531 CBV_bit1_1E384003 0;
BA_ "GenSigTimeoutTime_BSM" SG_ 2654486531 CBV_bit1_1E384003 0;
BA_ "GenSigTimeoutTime_CADM" SG_ 2654486531 CBV_bit1_1E384003 0;
BA_ "GenSigTimeoutTime_DMSM" SG_ 2654486531 CBV_bit1_1E384003 0;
BA_ "GenSigTimeoutTime_DTCM" SG_ 2654486531 CBV_bit1_1E384003 0;
BA_ "GenSigTimeoutTime_ECM" SG_ 2654486531 CBV_bit1_1E384003 0;
BA_ "GenSigTimeoutTime_ELSDM" SG_ 2654486531 CBV_bit1_1E384003 0;
BA_ "GenSigTimeoutTime_ESL" SG_ 2654486531 CBV_bit1_1E384003 0;
BA_ "GenSigTimeoutTime_GNMM" SG_ 2654486531 CBV_bit1_1E384003 0;
BA_ "GenSigTimeoutTime_HCP" SG_ 2654486531 CBV_bit1_1E384003 0;
BA_ "GenSigTimeoutTime_IPC" SG_ 2654486531 CBV_bit1_1E384003 0;
BA_ "GenSigTimeoutTime_RFHM" SG_ 2654486531 CBV_bit1_1E384003 0;
BA_ "GenSigTimeoutTime_SGW" SG_ 2654486531 CBV_bit1_1E384003 0;
BA_ "GenSigTimeoutTime_TCM" SG_ 2654486531 CBV_bit1_1E384003 0;
BA_ "GenSigTimeoutTime_AGSM" SG_ 2654486531 CBV_bit2_1E384003 0;
BA_ "GenSigTimeoutTime_ASBS" SG_ 2654486531 CBV_bit2_1E384003 0;
BA_ "GenSigTimeoutTime_BCM" SG_ 2654486531 CBV_bit2_1E384003 0;
BA_ "GenSigTimeoutTime_BSM" SG_ 2654486531 CBV_bit2_1E384003 0;
BA_ "GenSigTimeoutTime_CADM" SG_ 2654486531 CBV_bit2_1E384003 0;
BA_ "GenSigTimeoutTime_DMSM" SG_ 2654486531 CBV_bit2_1E384003 0;
BA_ "GenSigTimeoutTime_DTCM" SG_ 2654486531 CBV_bit2_1E384003 0;
BA_ "GenSigTimeoutTime_ECM" SG_ 2654486531 CBV_bit2_1E384003 0;
BA_ "GenSigTimeoutTime_ELSDM" SG_ 2654486531 CBV_bit2_1E384003 0;
BA_ "GenSigTimeoutTime_ESL" SG_ 2654486531 CBV_bit2_1E384003 0;
BA_ "GenSigTimeoutTime_GNMM" SG_ 2654486531 CBV_bit2_1E384003 0;
BA_ "GenSigTimeoutTime_HCP" SG_ 2654486531 CBV_bit2_1E384003 0;
BA_ "GenSigTimeoutTime_IPC" SG_ 2654486531 CBV_bit2_1E384003 0;
BA_ "GenSigTimeoutTime_RFHM" SG_ 2654486531 CBV_bit2_1E384003 0;
BA_ "GenSigTimeoutTime_SGW" SG_ 2654486531 CBV_bit2_1E384003 0;
BA_ "GenSigTimeoutTime_TCM" SG_ 2654486531 CBV_bit2_1E384003 0;
BA_ "GenSigTimeoutTime_AGSM" SG_ 2654486531 CBV_bit3_NMCoordinatorBit_1E384003 0;
BA_ "GenSigTimeoutTime_ASBS" SG_ 2654486531 CBV_bit3_NMCoordinatorBit_1E384003 0;
BA_ "GenSigTimeoutTime_BCM" SG_ 2654486531 CBV_bit3_NMCoordinatorBit_1E384003 0;
BA_ "GenSigTimeoutTime_BSM" SG_ 2654486531 CBV_bit3_NMCoordinatorBit_1E384003 0;
BA_ "GenSigTimeoutTime_CADM" SG_ 2654486531 CBV_bit3_NMCoordinatorBit_1E384003 0;
BA_ "GenSigTimeoutTime_DMSM" SG_ 2654486531 CBV_bit3_NMCoordinatorBit_1E384003 0;
BA_ "GenSigTimeoutTime_DTCM" SG_ 2654486531 CBV_bit3_NMCoordinatorBit_1E384003 0;
BA_ "GenSigTimeoutTime_ECM" SG_ 2654486531 CBV_bit3_NMCoordinatorBit_1E384003 0;
BA_ "GenSigTimeoutTime_ELSDM" SG_ 2654486531 CBV_bit3_NMCoordinatorBit_1E384003 0;
BA_ "GenSigTimeoutTime_ESL" SG_ 2654486531 CBV_bit3_NMCoordinatorBit_1E384003 0;
BA_ "GenSigTimeoutTime_GNMM" SG_ 2654486531 CBV_bit3_NMCoordinatorBit_1E384003 0;
BA_ "GenSigTimeoutTime_HCP" SG_ 2654486531 CBV_bit3_NMCoordinatorBit_1E384003 0;
BA_ "GenSigTimeoutTime_IPC" SG_ 2654486531 CBV_bit3_NMCoordinatorBit_1E384003 0;
BA_ "GenSigTimeoutTime_RFHM" SG_ 2654486531 CBV_bit3_NMCoordinatorBit_1E384003 0;
BA_ "GenSigTimeoutTime_SGW" SG_ 2654486531 CBV_bit3_NMCoordinatorBit_1E384003 0;
BA_ "GenSigTimeoutTime_TCM" SG_ 2654486531 CBV_bit3_NMCoordinatorBit_1E384003 0;
BA_ "GenSigTimeoutTime_AGSM" SG_ 2654486531 CBV_bit4_ActiveWakeupBit_1E384003 0;
BA_ "GenSigTimeoutTime_ASBS" SG_ 2654486531 CBV_bit4_ActiveWakeupBit_1E384003 0;
BA_ "GenSigTimeoutTime_BCM" SG_ 2654486531 CBV_bit4_ActiveWakeupBit_1E384003 0;
BA_ "GenSigTimeoutTime_BSM" SG_ 2654486531 CBV_bit4_ActiveWakeupBit_1E384003 0;
BA_ "GenSigTimeoutTime_CADM" SG_ 2654486531 CBV_bit4_ActiveWakeupBit_1E384003 0;
BA_ "GenSigTimeoutTime_DMSM" SG_ 2654486531 CBV_bit4_ActiveWakeupBit_1E384003 0;
BA_ "GenSigTimeoutTime_DTCM" SG_ 2654486531 CBV_bit4_ActiveWakeupBit_1E384003 0;
BA_ "GenSigTimeoutTime_ECM" SG_ 2654486531 CBV_bit4_ActiveWakeupBit_1E384003 0;
BA_ "GenSigTimeoutTime_ELSDM" SG_ 2654486531 CBV_bit4_ActiveWakeupBit_1E384003 0;
BA_ "GenSigTimeoutTime_ESL" SG_ 2654486531 CBV_bit4_ActiveWakeupBit_1E384003 0;
BA_ "GenSigTimeoutTime_GNMM" SG_ 2654486531 CBV_bit4_ActiveWakeupBit_1E384003 0;
BA_ "GenSigTimeoutTime_HCP" SG_ 2654486531 CBV_bit4_ActiveWakeupBit_1E384003 0;
BA_ "GenSigTimeoutTime_IPC" SG_ 2654486531 CBV_bit4_ActiveWakeupBit_1E384003 0;
BA_ "GenSigTimeoutTime_RFHM" SG_ 2654486531 CBV_bit4_ActiveWakeupBit_1E384003 0;
BA_ "GenSigTimeoutTime_SGW" SG_ 2654486531 CBV_bit4_ActiveWakeupBit_1E384003 0;
BA_ "GenSigTimeoutTime_ECM" SG_ 2654486534 CBV_bit3_NMCoordinatorBit_1E384006 0;
BA_ "GenSigTimeoutTime_ELSDM" SG_ 2654486534 CBV_bit3_NMCoordinatorBit_1E384006 0;
BA_ "GenSigTimeoutTime_ESL" SG_ 2654486534 CBV_bit3_NMCoordinatorBit_1E384006 0;
BA_ "GenSigTimeoutTime_GNMM" SG_ 2654486534 CBV_bit3_NMCoordinatorBit_1E384006 0;
BA_ "GenSigTimeoutTime_HCP" SG_ 2654486534 CBV_bit3_NMCoordinatorBit_1E384006 0;
BA_ "GenSigTimeoutTime_IPC" SG_ 2654486534 CBV_bit3_NMCoordinatorBit_1E384006 0;
BA_ "GenSigTimeoutTime_RFHM" SG_ 2654486534 CBV_bit3_NMCoordinatorBit_1E384006 0;
BA_ "GenSigTimeoutTime_SGW" SG_ 2654486534 CBV_bit3_NMCoordinatorBit_1E384006 0;
BA_ "GenSigTimeoutTime_TCM" SG_ 2654486534 CBV_bit3_NMCoordinatorBit_1E384006 0;
BA_ "GenSigTimeoutTime_AGSM" SG_ 2654486534 CBV_bit4_ActiveWakeupBit_1E384006 0;
BA_ "GenSigTimeoutTime_ASBS" SG_ 2654486534 CBV_bit4_ActiveWakeupBit_1E384006 0;
BA_ "GenSigTimeoutTime_BCM" SG_ 2654486534 CBV_bit4_ActiveWakeupBit_1E384006 0;
BA_ "GenSigTimeoutTime_BSM" SG_ 2654486534 CBV_bit4_ActiveWakeupBit_1E384006 0;
BA_ "GenSigTimeoutTime_CADM" SG_ 2654486534 CBV_bit4_ActiveWakeupBit_1E384006 0;
BA_ "GenSigTimeoutTime_DMSM" SG_ 2654486534 CBV_bit4_ActiveWakeupBit_1E384006 0;
BA_ "GenSigTimeoutTime_DTCM" SG_ 2654486534 CBV_bit4_ActiveWakeupBit_1E384006 0;
BA_ "GenSigTimeoutTime_ECM" SG_ 2654486534 CBV_bit4_ActiveWakeupBit_1E384006 0;
BA_ "GenSigTimeoutTime_ELSDM" SG_ 2654486534 CBV_bit4_ActiveWakeupBit_1E384006 0;
BA_ "GenSigTimeoutTime_ESL" SG_ 2654486534 CBV_bit4_ActiveWakeupBit_1E384006 0;
BA_ "GenSigTimeoutTime_GNMM" SG_ 2654486534 CBV_bit4_ActiveWakeupBit_1E384006 0;
BA_ "GenSigTimeoutTime_HCP" SG_ 2654486534 CBV_bit4_ActiveWakeupBit_1E384006 0;
BA_ "GenSigTimeoutTime_IPC" SG_ 2654486534 CBV_bit4_ActiveWakeupBit_1E384006 0;
BA_ "GenSigTimeoutTime_RFHM" SG_ 2654486534 CBV_bit4_ActiveWakeupBit_1E384006 0;
BA_ "GenSigTimeoutTime_SGW" SG_ 2654486534 CBV_bit4_ActiveWakeupBit_1E384006 0;
BA_ "GenSigTimeoutTime_TCM" SG_ 2654486534 CBV_bit4_ActiveWakeupBit_1E384006 0;
BA_ "GenSigTimeoutTime_AGSM" SG_ 2654486534 CBV_bit5_1E384006 0;
BA_ "GenSigTimeoutTime_ASBS" SG_ 2654486534 CBV_bit5_1E384006 0;
BA_ "GenSigTimeoutTime_BCM" SG_ 2654486534 CBV_bit5_1E384006 0;
BA_ "GenSigTimeoutTime_BSM" SG_ 2654486534 CBV_bit5_1E384006 0;
BA_ "GenSigTimeoutTime_CADM" SG_ 2654486534 CBV_bit5_1E384006 0;
BA_ "GenSigTimeoutTime_DMSM" SG_ 2654486534 CBV_bit5_1E384006 0;
BA_ "GenSigTimeoutTime_DTCM" SG_ 2654486534 CBV_bit5_1E384006 0;
BA_ "GenSigTimeoutTime_ECM" SG_ 2654486534 CBV_bit5_1E384006 0;
BA_ "GenSigTimeoutTime_ELSDM" SG_ 2654486534 CBV_bit5_1E384006 0;
BA_ "GenSigTimeoutTime_ESL" SG_ 2654486534 CBV_bit5_1E384006 0;
BA_ "GenSigTimeoutTime_GNMM" SG_ 2654486534 CBV_bit5_1E384006 0;
BA_ "GenSigTimeoutTime_HCP" SG_ 2654486534 CBV_bit5_1E384006 0;
BA_ "GenSigTimeoutTime_IPC" SG_ 2654486534 CBV_bit5_1E384006 0;
BA_ "GenSigTimeoutTime_RFHM" SG_ 2654486534 CBV_bit5_1E384006 0;
BA_ "GenSigTimeoutTime_SGW" SG_ 2654486534 CBV_bit5_1E384006 0;
BA_ "GenSigTimeoutTime_TCM" SG_ 2654486534 CBV_bit5_1E384006 0;
BA_ "GenSigTimeoutTime_AGSM" SG_ 2654486534 CBV_bit6_PartialNtwInfBit_1E384006 0;
BA_ "GenSigTimeoutTime_ASBS" SG_ 2654486534 CBV_bit6_PartialNtwInfBit_1E384006 0;
BA_ "GenSigTimeoutTime_BCM" SG_ 2654486534 CBV_bit6_PartialNtwInfBit_1E384006 0;
BA_ "GenSigTimeoutTime_BSM" SG_ 2654486534 CBV_bit6_PartialNtwInfBit_1E384006 0;
BA_ "GenSigTimeoutTime_CADM" SG_ 2654486534 CBV_bit6_PartialNtwInfBit_1E384006 0;
BA_ "GenSigTimeoutTime_DMSM" SG_ 2654486534 CBV_bit6_PartialNtwInfBit_1E384006 0;
BA_ "GenSigTimeoutTime_DTCM" SG_ 2654486534 CBV_bit6_PartialNtwInfBit_1E384006 0;
BA_ "GenSigTimeoutTime_ECM" SG_ 2654486534 CBV_bit6_PartialNtwInfBit_1E384006 0;
BA_ "GenSigTimeoutTime_ELSDM" SG_ 2654486534 CBV_bit6_PartialNtwInfBit_1E384006 0;
BA_ "GenSigTimeoutTime_ESL" SG_ 2654486534 CBV_bit6_PartialNtwInfBit_1E384006 0;
BA_ "GenSigTimeoutTime_GNMM" SG_ 2654486534 CBV_bit6_PartialNtwInfBit_1E384006 0;
BA_ "GenSigTimeoutTime_HCP" SG_ 2654486534 CBV_bit6_PartialNtwInfBit_1E384006 0;
BA_ "GenSigTimeoutTime_IPC" SG_ 2654486534 CBV_bit6_PartialNtwInfBit_1E384006 0;
BA_ "GenSigTimeoutTime_RFHM" SG_ 2654486534 CBV_bit6_PartialNtwInfBit_1E384006 0;
BA_ "GenSigTimeoutTime_SGW" SG_ 2654486534 CBV_bit6_PartialNtwInfBit_1E384006 0;
BA_ "GenSigTimeoutTime_TCM" SG_ 2654486534 CBV_bit6_PartialNtwInfBit_1E384006 0;
BA_ "GenSigTimeoutTime_AGSM" SG_ 2654486534 CBV_bit7_1E384006 0;
BA_ "GenSigTimeoutTime_ASBS" SG_ 2654486534 CBV_bit7_1E384006 0;
BA_ "GenSigTimeoutTime_BCM" SG_ 2654486534 CBV_bit7_1E384006 0;
BA_ "GenSigTimeoutTime_BSM" SG_ 2654486534 CBV_bit7_1E384006 0;
BA_ "GenSigTimeoutTime_CADM" SG_ 2654486534 CBV_bit7_1E384006 0;
BA_ "GenSigTimeoutTime_DMSM" SG_ 2654486534 CBV_bit7_1E384006 0;
BA_ "GenSigTimeoutTime_DTCM" SG_ 2654486534 CBV_bit7_1E384006 0;
BA_ "GenSigTimeoutTime_ECM" SG_ 2654486534 CBV_bit7_1E384006 0;
BA_ "GenSigTimeoutTime_ELSDM" SG_ 2654486534 CBV_bit7_1E384006 0;
BA_ "GenSigTimeoutTime_ESL" SG_ 2654486534 CBV_bit7_1E384006 0;
BA_ "GenSigTimeoutTime_GNMM" SG_ 2654486534 CBV_bit7_1E384006 0;
BA_ "GenSigTimeoutTime_HCP" SG_ 2654486534 CBV_bit7_1E384006 0;
BA_ "GenSigTimeoutTime_IPC" SG_ 2654486534 CBV_bit7_1E384006 0;
BA_ "GenSigTimeoutTime_RFHM" SG_ 2654486534 CBV_bit7_1E384006 0;
BA_ "GenSigTimeoutTime_SGW" SG_ 2654486534 CBV_bit7_1E384006 0;
BA_ "GenSigTimeoutTime_TCM" SG_ 2654486534 CBV_bit7_1E384006 0;
BA_ "GenSigTimeoutTime_AGSM" SG_ 2654486534 SourceNodeIdentifier_1E384006 0;
BA_ "GenSigTimeoutTime_ASBS" SG_ 2654486534 SourceNodeIdentifier_1E384006 0;
BA_ "GenSigTimeoutTime_BCM" SG_ 2654486534 SourceNodeIdentifier_1E384006 0;
BA_ "GenSigTimeoutTime_BSM" SG_ 2654486534 SourceNodeIdentifier_1E384006 0;
BA_ "GenSigTimeoutTime_CADM" SG_ 2654486534 SourceNodeIdentifier_1E384006 0;
BA_ "GenSigTimeoutTime_DMSM" SG_ 2654486534 SourceNodeIdentifier_1E384006 0;
BA_ "GenSigTimeoutTime_DTCM" SG_ 2654486534 SourceNodeIdentifier_1E384006 0;
BA_ "GenSigTimeoutTime_ECM" SG_ 2654486534 SourceNodeIdentifier_1E384006 0;
BA_ "GenSigTimeoutTime_ELSDM" SG_ 2654486534 SourceNodeIdentifier_1E384006 0;
BA_ "GenSigTimeoutTime_ESL" SG_ 2654486534 SourceNodeIdentifier_1E384006 0;
BA_ "GenSigTimeoutTime_GNMM" SG_ 2654486534 SourceNodeIdentifier_1E384006 0;
BA_ "GenSigTimeoutTime_HCP" SG_ 2654486534 SourceNodeIdentifier_1E384006 0;
BA_ "GenSigTimeoutTime_IPC" SG_ 2654486534 SourceNodeIdentifier_1E384006 0;
BA_ "GenSigTimeoutTime_RFHM" SG_ 2654486534 SourceNodeIdentifier_1E384006 0;
BA_ "GenSigTimeoutTime_SGW" SG_ 2654486534 SourceNodeIdentifier_1E384006 0;
BA_ "GenSigTimeoutTime_TCM" SG_ 2654486534 SourceNodeIdentifier_1E384006 0;
BA_ "GenSigTimeoutTime_AGSM" SG_ 2654486669 CBV_bit0_RepeatMessageRequestBit_1E38408D 0;
BA_ "GenSigTimeoutTime_ASBS" SG_ 2654486669 CBV_bit0_RepeatMessageRequestBit_1E38408D 0;
BA_ "GenSigTimeoutTime_BCM" SG_ 2654486669 CBV_bit0_RepeatMessageRequestBit_1E38408D 0;
BA_ "GenSigTimeoutTime_BSM" SG_ 2654486669 CBV_bit0_RepeatMessageRequestBit_1E38408D 0;
BA_ "GenSigTimeoutTime_CADM" SG_ 2654486669 CBV_bit0_RepeatMessageRequestBit_1E38408D 0;
BA_ "GenSigTimeoutTime_DMSM" SG_ 2654486669 CBV_bit0_RepeatMessageRequestBit_1E38408D 0;
BA_ "GenSigTimeoutTime_DTCM" SG_ 2654486669 CBV_bit0_RepeatMessageRequestBit_1E38408D 0;
BA_ "GenSigTimeoutTime_ECM" SG_ 2654486669 CBV_bit0_RepeatMessageRequestBit_1E38408D 0;
BA_ "GenSigTimeoutTime_ELSDM" SG_ 2654486669 CBV_bit0_RepeatMessageRequestBit_1E38408D 0;
BA_ "GenSigTimeoutTime_ESL" SG_ 2654486669 CBV_bit0_RepeatMessageRequestBit_1E38408D 0;
BA_ "GenSigTimeoutTime_GNMM" SG_ 2654486669 CBV_bit0_RepeatMessageRequestBit_1E38408D 0;
BA_ "GenSigTimeoutTime_HCP" SG_ 2654486669 CBV_bit0_RepeatMessageRequestBit_1E38408D 0;
BA_ "GenSigTimeoutTime_IPC" SG_ 2654486669 CBV_bit0_RepeatMessageRequestBit_1E38408D 0;
BA_ "GenSigTimeoutTime_RFHM" SG_ 2654486669 CBV_bit0_RepeatMessageRequestBit_1E38408D 0;
BA_ "GenSigTimeoutTime_SGW" SG_ 2654486669 CBV_bit0_RepeatMessageRequestBit_1E38408D 0;
BA_ "GenSigTimeoutTime_TCM" SG_ 2654486669 CBV_bit0_RepeatMessageRequestBit_1E38408D 0;
BA_ "GenSigTimeoutTime_AGSM" SG_ 2654486669 CBV_bit1_1E38408D 0;
BA_ "GenSigTimeoutTime_ASBS" SG_ 2654486669 CBV_bit1_1E38408D 0;
BA_ "GenSigTimeoutTime_BCM" SG_ 2654486669 CBV_bit1_1E38408D 0;
BA_ "GenSigTimeoutTime_BSM" SG_ 2654486669 CBV_bit1_1E38408D 0;
BA_ "GenSigTimeoutTime_CADM" SG_ 2654486669 CBV_bit1_1E38408D 0;
BA_ "GenSigTimeoutTime_DMSM" SG_ 2654486669 CBV_bit1_1E38408D 0;
BA_ "GenSigTimeoutTime_DTCM" SG_ 2654486669 CBV_bit1_1E38408D 0;
BA_ "GenSigTimeoutTime_ECM" SG_ 2654486669 CBV_bit1_1E38408D 0;
BA_ "GenSigTimeoutTime_ELSDM" SG_ 2654486669 CBV_bit1_1E38408D 0;
VAL_ 2654486539 CBV_bit0_RepeatMessageRequestBit_1E38400B 0 "Repeat_Message_State_not_requested" 1 "Repeat_Message_State_requested";
VAL_ 2654486539 CBV_bit3_NMCoordinatorBit_1E38400B 0 "Start_of_synchronized_shutdown_is_not_requested_by_main_coordinator" 1 "Start_of_synchronized_shutdown_is_requested_by_main_coordinator";
VAL_ 2654486539 CBV_bit4_ActiveWakeupBit_1E38400B 0 "PassiveWakeup" 1 "ActiveWakeup";
VAL_ 2654486539 CBV_bit6_PartialNtwInfBit_1E38400B 0 "NM_PDU_contains_no_Partial_Network_request_information" 1 "NM_PDU_contains_Partial_Network_request_information";
VAL_ 2654486640 CBV_bit0_RepeatMessageRequestBit_1E384070 0 "Repeat_Message_State_not_requested" 1 "Repeat_Message_State_requested";
VAL_ 2654486640 CBV_bit3_NMCoordinatorBit_1E384070 0 "Start_of_synchronized_shutdown_is_not_requested_by_main_coordinator" 1 "Start_of_synchronized_shutdown_is_requested_by_main_coordinator";
VAL_ 2654486640 CBV_bit4_ActiveWakeupBit_1E384070 0 "PassiveWakeup" 1 "ActiveWakeup";
VAL_ 2654486640 CBV_bit6_PartialNtwInfBit_1E384070 0 "NM_PDU_contains_no_Partial_Network_request_information" 1 "NM_PDU_contains_Partial_Network_request_information";
VAL_ 2654486593 CBV_bit3_NMCoordinatorBit_1E384041 0 "Start_of_synchronized_shutdown_is_not_requested_by_main_coordinator" 1 "Start_of_synchronized_shutdown_is_requested_by_main_coordinator";
VAL_ 2654486593 CBV_bit4_ActiveWakeupBit_1E384041 0 "PassiveWakeup" 1 "ActiveWakeup";
VAL_ 2654486593 CBV_bit6_PartialNtwInfBit_1E384041 0 "NM_PDU_contains_no_Partial_Network_request_information" 1 "NM_PDU_contains_Partial_Network_request_information";
VAL_ 2654486593 CBV_bit0_RepeatMessageRequestBit_1E384041 0 "Repeat_Message_State_not_requested" 1 "Repeat_Message_State_requested";
VAL_ 2654486531 CBV_bit0_RepeatMessageRequestBit_1E384003 0 "Repeat_Message_State_not_requested" 1 "Repeat_Message_State_requested";
VAL_ 2654486531 CBV_bit3_NMCoordinatorBit_1E384003 0 "Start_of_synchronized_shutdown_is_not_requested_by_main_coordinator" 1 "Start_of_synchronized_shutdown_is_requested_by_main_coordinator";
VAL_ 2654486531 CBV_bit4_ActiveWakeupBit_1E384003 0 "PassiveWakeup" 1 "ActiveWakeup";
VAL_ 2654486531 CBV_bit6_PartialNtwInfBit_1E384003 0 "NM_PDU_contains_no_Partial_Network_request_information" 1 "NM_PDU_contains_Partial_Network_request_information";
VAL_ 2654486626 CBV_bit0_RepeatMessageRequestBit_1E384062 0 "Repeat Message State not requested" 1 "Repeat Message State requested";
VAL_ 2654486626 CBV_bit3_NMCoordinatorBit_1E384062 0 "Start of synchronized shutdown is not requested by main coordinator" 1 "Start of synchronized shutdown is requested by main coordinator";
VAL_ 2654486626 CBV_bit4_ActiveWakeupBit_1E384062 0 "PassiveWakeup" 1 "ActiveWakeup";
VAL_ 2654486626 CBV_bit6_PartialNtwInfBit_1E384062 0 "NM PDU contains no Partial Network request information" 1 "NM PDU contains Partial Network request information";
VAL_ 2654486549 CBV_bit0_RepeatMessageRequestBit_1E384015 0 "Repeat_Message_State_not_requested" 1 "Repeat_Message_State_requested";
VAL_ 2654486549 CBV_bit3_NMCoordinatorBit_1E384015 0 "Start_of_synchronized_shutdown_is_not_requested_by_main_coordinator" 1 "Start_of_synchronized_shutdown_is_requested_by_main_coordinator";
VAL_ 2654486549 CBV_bit4_ActiveWakeupBit_1E384015 0 "PassiveWakeup" 1 "ActiveWakeup";
VAL_ 2654486549 CBV_bit6_PartialNtwInfBit_1E384015 0 "NM_PDU_contains_no_Partial_Network_request_information" 1 "NM_PDU_contains_Partial_Network_request_information";
VAL_ 2654486633 CBV_bit3_NMCoordinatorBit_1E384069 0 "Start_of_synchronized_shutdown_is_not_requested_by_main_coordinator" 1 "Start_of_synchronized_shutdown_is_requested_by_main_coordinator";
VAL_ 2654486633 CBV_bit4_ActiveWakeupBit_1E384069 0 "PassiveWakeup" 1 "ActiveWakeup";
VAL_ 2654486633 CBV_bit6_PartialNtwInfBit_1E384069 0 "NM_PDU_contains_no_Partial_Network_request_information" 1 "NM_PDU_contains_Partial_Network_request_information";
VAL_ 2654486633 CBV_bit0_RepeatMessageRequestBit_1E384069 0 "Repeat_Message_State_not_requested" 1 "Repeat_Message_State_requested";
VAL_ 2654486529 CBV_bit0_RepeatMessageRequestBit_1E384001 0 "Repeat_Message_State_not_requested" 1 "Repeat_Message_State_requested";
VAL_ 2654486529 CBV_bit3_NMCoordinatorBit_1E384001 0 "Start_of_synchronized_shutdown_is_not_requested_by_main_coordinator" 1 "Start_of_synchronized_shutdown_is_requested_by_main_coordinator";
VAL_ 2654486529 CBV_bit4_ActiveWakeupBit_1E384001 0 "PassiveWakeup" 1 "ActiveWakeup";
VAL_ 2654486529 CBV_bit6_PartialNtwInfBit_1E384001 0 "NM_PDU_contains_no_Partial_Network_request_information" 1 "NM_PDU_contains_Partial_Network_request_information";
VAL_ 2654486595 CBV_bit0_RepeatMessageRequestBit_1E384043 0 "Repeat_Message_State_not_requested" 1 "Repeat_Message_State_requested";
VAL_ 2654486595 CBV_bit3_NMCoordinatorBit_1E384043 0 "Start_of_synchronized_shutdown_is_not_requested_by_main_coordinator" 1 "Start_of_synchronized_shutdown_is_requested_by_main_coordinator";
VAL_ 2654486595 CBV_bit4_ActiveWakeupBit_1E384043 0 "PassiveWakeup" 1 "ActiveWakeup";
VAL_ 2654486595 CBV_bit6_PartialNtwInfBit_1E384043 0 "NM_PDU_contains_no_Partial_Network_request_information" 1 "NM_PDU_contains_Partial_Network_request_information";
VAL_ 2654486669 CBV_bit3_NMCoordinatorBit_1E38408D 0 "Start_of_synchronized_shutdown_is_not_requested_by_main_coordinator" 1 "Start_of_synchronized_shutdown_is_requested_by_main_coordinator";
VAL_ 2654486669 CBV_bit4_ActiveWakeupBit_1E38408D 0 "PassiveWakeup" 1 "ActiveWakeup";
VAL_ 2654486669 CBV_bit6_PartialNtwInfBit_1E38408D 0 "NM_PDU_contains_no_Partial_Network_request_information" 1 "NM_PDU_contains_Partial_Network_request_information";
VAL_ 2654486669 CBV_bit0_RepeatMessageRequestBit_1E38408D 0 "Repeat_Message_State_not_requested" 1 "Repeat_Message_State_requested";
VAL_ 2654486534 CBV_bit0_RepeatMessageRequestBit_1E384006 0 "Repeat_Message_State_not_requested" 1 "Repeat_Message_State_requested";
VAL_ 2654486534 CBV_bit3_NMCoordinatorBit_1E384006 0 "Start_of_synchronized_shutdown_is_not_requested_by_main_coordinator" 1 "Start_of_synchronized_shutdown_is_requested_by_main_coordinator";
VAL_ 2654486534 CBV_bit4_ActiveWakeupBit_1E384006 0 "PassiveWakeup" 1 "ActiveWakeup";
VAL_ 2654486534 CBV_bit6_PartialNtwInfBit_1E384006 0 "NM_PDU_contains_no_Partial_Network_request_information" 1 "NM_PDU_contains_Partial_Network_request_information";
VAL_ 2654486528 CBV_bit0_RepeatMessageRequestBit_1E384000 0 "Repeat_Message_State_not_requested" 1 "Repeat_Message_State_requested";
VAL_ 2654486528 CBV_bit3_NMCoordinatorBit_1E384000 0 "Start_of_synchronized_shutdown_is_not_requested_by_main_coordinator" 1 "Start_of_synchronized_shutdown_is_requested_by_main_coordinator";
VAL_ 2654486528 CBV_bit4_ActiveWakeupBit_1E384000 0 "PassiveWakeup" 1 "ActiveWakeup";
VAL_ 2654486528 CBV_bit6_PartialNtwInfBit_1E384000 0 "NM_PDU_contains_no_Partial_Network_request_information" 1 "NM_PDU_contains_Partial_Network_request_information";
